// *************************************************************************** *
// *                                                                           *
// * Description:         CANDB File                                           *
// * Generated at:        2023-03-30 16:08                                     *
// * System:              ZSDB123101                                           *
// * Variant:             CS1E                                                 *
// * Network:             Private_CANFD5                                       *
// *                                                                           *
// *************************************************************************** *
VERSION "Private_CANFD5"

NS_ :

BS_ :

BU_ :  ASDM SODL

BO_ 137 SODLPrivateCANFD5Fr72 : 64 SODL
 SG_ ReSideRdrLeDetn229_UB : 487|1@0+ (1,0) [0|1] "" ASDM
 SG_ ReSideRdrLeDetn229RdrDetnAmbigState : 72|1@0+ (1,0) [0|1] "" ASDM
 SG_ ReSideRdrLeDetn229RdrDetnAssoTrkID : 79|7@0+ (1.0,0.0) [0.0|127.0] "Unitless" ASDM
 SG_ ReSideRdrLeDetn229RdrDetnAzi : 34|11@0+ (0.1,-90.0) [-90.0|90.0] "Deg" ASDM
 SG_ ReSideRdrLeDetn229RdrDetnChks : 7|8@0+ (1.0,0.0) [0.0|255.0] "Unitless" ASDM
 SG_ ReSideRdrLeDetn229RdrDetnCntr : 15|4@0+ (1.0,0.0) [0.0|15.0] "Unitless" ASDM
 SG_ ReSideRdrLeDetn229RdrDetnConf : 11|7@0+ (1.0,0.0) [0.0|100.0] "%" ASDM
 SG_ ReSideRdrLeDetn229RdrDetnElevn : 20|5@0+ (1.0,-15.0) [-15.0|15.0] "Deg" ASDM
 SG_ ReSideRdrLeDetn229RdrDetnPwr : 71|6@0+ (1.0,0.0) [0.0|63.0] "dB" ASDM
 SG_ ReSideRdrLeDetn229RdrDetnRng : 55|14@0+ (0.02,-1.0) [-1.0|200.0] "m" ASDM
 SG_ ReSideRdrLeDetn229RdrDetnRngV : 31|13@0+ (0.02,-80.0) [-80.0|80.0] "m/s" ASDM
 SG_ ReSideRdrLeDetn229RdrDetnSameRV : 65|2@0+ (1,0) [0|3] "" ASDM
 SG_ ReSideRdrLeDetn229RdrDetnSts : 57|2@0+ (1,0) [0|3] "" ASDM
 SG_ ReSideRdrLeDetn230_UB : 486|1@0+ (1,0) [0|1] "" ASDM
 SG_ ReSideRdrLeDetn230RdrDetnAmbigState : 152|1@0+ (1,0) [0|1] "" ASDM
 SG_ ReSideRdrLeDetn230RdrDetnAssoTrkID : 159|7@0+ (1.0,0.0) [0.0|127.0] "Unitless" ASDM
 SG_ ReSideRdrLeDetn230RdrDetnAzi : 114|11@0+ (0.1,-90.0) [-90.0|90.0] "Deg" ASDM
 SG_ ReSideRdrLeDetn230RdrDetnChks : 87|8@0+ (1.0,0.0) [0.0|255.0] "Unitless" ASDM
 SG_ ReSideRdrLeDetn230RdrDetnCntr : 95|4@0+ (1.0,0.0) [0.0|15.0] "Unitless" ASDM
 SG_ ReSideRdrLeDetn230RdrDetnConf : 91|7@0+ (1.0,0.0) [0.0|100.0] "%" ASDM
 SG_ ReSideRdrLeDetn230RdrDetnElevn : 100|5@0+ (1.0,-15.0) [-15.0|15.0] "Deg" ASDM
 SG_ ReSideRdrLeDetn230RdrDetnPwr : 151|6@0+ (1.0,0.0) [0.0|63.0] "dB" ASDM
 SG_ ReSideRdrLeDetn230RdrDetnRng : 135|14@0+ (0.02,-1.0) [-1.0|200.0] "m" ASDM
 SG_ ReSideRdrLeDetn230RdrDetnRngV : 111|13@0+ (0.02,-80.0) [-80.0|80.0] "m/s" ASDM
 SG_ ReSideRdrLeDetn230RdrDetnSameRV : 145|2@0+ (1,0) [0|3] "" ASDM
 SG_ ReSideRdrLeDetn230RdrDetnSts : 137|2@0+ (1,0) [0|3] "" ASDM
 SG_ ReSideRdrLeDetn231_UB : 485|1@0+ (1,0) [0|1] "" ASDM
 SG_ ReSideRdrLeDetn231RdrDetnAmbigState : 232|1@0+ (1,0) [0|1] "" ASDM
 SG_ ReSideRdrLeDetn231RdrDetnAssoTrkID : 239|7@0+ (1.0,0.0) [0.0|127.0] "Unitless" ASDM
 SG_ ReSideRdrLeDetn231RdrDetnAzi : 194|11@0+ (0.1,-90.0) [-90.0|90.0] "Deg" ASDM
 SG_ ReSideRdrLeDetn231RdrDetnChks : 167|8@0+ (1.0,0.0) [0.0|255.0] "Unitless" ASDM
 SG_ ReSideRdrLeDetn231RdrDetnCntr : 175|4@0+ (1.0,0.0) [0.0|15.0] "Unitless" ASDM
 SG_ ReSideRdrLeDetn231RdrDetnConf : 171|7@0+ (1.0,0.0) [0.0|100.0] "%" ASDM
 SG_ ReSideRdrLeDetn231RdrDetnElevn : 180|5@0+ (1.0,-15.0) [-15.0|15.0] "Deg" ASDM
 SG_ ReSideRdrLeDetn231RdrDetnPwr : 231|6@0+ (1.0,0.0) [0.0|63.0] "dB" ASDM
 SG_ ReSideRdrLeDetn231RdrDetnRng : 215|14@0+ (0.02,-1.0) [-1.0|200.0] "m" ASDM
 SG_ ReSideRdrLeDetn231RdrDetnRngV : 191|13@0+ (0.02,-80.0) [-80.0|80.0] "m/s" ASDM
 SG_ ReSideRdrLeDetn231RdrDetnSameRV : 225|2@0+ (1,0) [0|3] "" ASDM
 SG_ ReSideRdrLeDetn231RdrDetnSts : 217|2@0+ (1,0) [0|3] "" ASDM
 SG_ ReSideRdrLeDetn232_UB : 484|1@0+ (1,0) [0|1] "" ASDM
 SG_ ReSideRdrLeDetn232RdrDetnAmbigState : 312|1@0+ (1,0) [0|1] "" ASDM
 SG_ ReSideRdrLeDetn232RdrDetnAssoTrkID : 319|7@0+ (1.0,0.0) [0.0|127.0] "Unitless" ASDM
 SG_ ReSideRdrLeDetn232RdrDetnAzi : 274|11@0+ (0.1,-90.0) [-90.0|90.0] "Deg" ASDM
 SG_ ReSideRdrLeDetn232RdrDetnChks : 247|8@0+ (1.0,0.0) [0.0|255.0] "Unitless" ASDM
 SG_ ReSideRdrLeDetn232RdrDetnCntr : 255|4@0+ (1.0,0.0) [0.0|15.0] "Unitless" ASDM
 SG_ ReSideRdrLeDetn232RdrDetnConf : 251|7@0+ (1.0,0.0) [0.0|100.0] "%" ASDM
 SG_ ReSideRdrLeDetn232RdrDetnElevn : 260|5@0+ (1.0,-15.0) [-15.0|15.0] "Deg" ASDM
 SG_ ReSideRdrLeDetn232RdrDetnPwr : 311|6@0+ (1.0,0.0) [0.0|63.0] "dB" ASDM
 SG_ ReSideRdrLeDetn232RdrDetnRng : 295|14@0+ (0.02,-1.0) [-1.0|200.0] "m" ASDM
 SG_ ReSideRdrLeDetn232RdrDetnRngV : 271|13@0+ (0.02,-80.0) [-80.0|80.0] "m/s" ASDM
 SG_ ReSideRdrLeDetn232RdrDetnSameRV : 305|2@0+ (1,0) [0|3] "" ASDM
 SG_ ReSideRdrLeDetn232RdrDetnSts : 297|2@0+ (1,0) [0|3] "" ASDM
 SG_ ReSideRdrLeDetn233_UB : 483|1@0+ (1,0) [0|1] "" ASDM
 SG_ ReSideRdrLeDetn233RdrDetnAmbigState : 392|1@0+ (1,0) [0|1] "" ASDM
 SG_ ReSideRdrLeDetn233RdrDetnAssoTrkID : 399|7@0+ (1.0,0.0) [0.0|127.0] "Unitless" ASDM
 SG_ ReSideRdrLeDetn233RdrDetnAzi : 354|11@0+ (0.1,-90.0) [-90.0|90.0] "Deg" ASDM
 SG_ ReSideRdrLeDetn233RdrDetnChks : 327|8@0+ (1.0,0.0) [0.0|255.0] "Unitless" ASDM
 SG_ ReSideRdrLeDetn233RdrDetnCntr : 335|4@0+ (1.0,0.0) [0.0|15.0] "Unitless" ASDM
 SG_ ReSideRdrLeDetn233RdrDetnConf : 331|7@0+ (1.0,0.0) [0.0|100.0] "%" ASDM
 SG_ ReSideRdrLeDetn233RdrDetnElevn : 340|5@0+ (1.0,-15.0) [-15.0|15.0] "Deg" ASDM
 SG_ ReSideRdrLeDetn233RdrDetnPwr : 391|6@0+ (1.0,0.0) [0.0|63.0] "dB" ASDM
 SG_ ReSideRdrLeDetn233RdrDetnRng : 375|14@0+ (0.02,-1.0) [-1.0|200.0] "m" ASDM
 SG_ ReSideRdrLeDetn233RdrDetnRngV : 351|13@0+ (0.02,-80.0) [-80.0|80.0] "m/s" ASDM
 SG_ ReSideRdrLeDetn233RdrDetnSameRV : 385|2@0+ (1,0) [0|3] "" ASDM
 SG_ ReSideRdrLeDetn233RdrDetnSts : 377|2@0+ (1,0) [0|3] "" ASDM
 SG_ ReSideRdrLeDetn234_UB : 482|1@0+ (1,0) [0|1] "" ASDM
 SG_ ReSideRdrLeDetn234RdrDetnAmbigState : 472|1@0+ (1,0) [0|1] "" ASDM
 SG_ ReSideRdrLeDetn234RdrDetnAssoTrkID : 479|7@0+ (1.0,0.0) [0.0|127.0] "Unitless" ASDM
 SG_ ReSideRdrLeDetn234RdrDetnAzi : 434|11@0+ (0.1,-90.0) [-90.0|90.0] "Deg" ASDM
 SG_ ReSideRdrLeDetn234RdrDetnChks : 407|8@0+ (1.0,0.0) [0.0|255.0] "Unitless" ASDM
 SG_ ReSideRdrLeDetn234RdrDetnCntr : 415|4@0+ (1.0,0.0) [0.0|15.0] "Unitless" ASDM
 SG_ ReSideRdrLeDetn234RdrDetnConf : 411|7@0+ (1.0,0.0) [0.0|100.0] "%" ASDM
 SG_ ReSideRdrLeDetn234RdrDetnElevn : 420|5@0+ (1.0,-15.0) [-15.0|15.0] "Deg" ASDM
 SG_ ReSideRdrLeDetn234RdrDetnPwr : 471|6@0+ (1.0,0.0) [0.0|63.0] "dB" ASDM
 SG_ ReSideRdrLeDetn234RdrDetnRng : 455|14@0+ (0.02,-1.0) [-1.0|200.0] "m" ASDM
 SG_ ReSideRdrLeDetn234RdrDetnRngV : 431|13@0+ (0.02,-80.0) [-80.0|80.0] "m/s" ASDM
 SG_ ReSideRdrLeDetn234RdrDetnSameRV : 465|2@0+ (1,0) [0|3] "" ASDM
 SG_ ReSideRdrLeDetn234RdrDetnSts : 457|2@0+ (1,0) [0|3] "" ASDM

BO_ 144 SODLPrivateCANFD5Fr73 : 64 SODL
 SG_ ReSideRdrLeDetn235_UB : 487|1@0+ (1,0) [0|1] "" ASDM
 SG_ ReSideRdrLeDetn235RdrDetnAmbigState : 72|1@0+ (1,0) [0|1] "" ASDM
 SG_ ReSideRdrLeDetn235RdrDetnAssoTrkID : 79|7@0+ (1.0,0.0) [0.0|127.0] "Unitless" ASDM
 SG_ ReSideRdrLeDetn235RdrDetnAzi : 34|11@0+ (0.1,-90.0) [-90.0|90.0] "Deg" ASDM
 SG_ ReSideRdrLeDetn235RdrDetnChks : 7|8@0+ (1.0,0.0) [0.0|255.0] "Unitless" ASDM
 SG_ ReSideRdrLeDetn235RdrDetnCntr : 15|4@0+ (1.0,0.0) [0.0|15.0] "Unitless" ASDM
 SG_ ReSideRdrLeDetn235RdrDetnConf : 11|7@0+ (1.0,0.0) [0.0|100.0] "%" ASDM
 SG_ ReSideRdrLeDetn235RdrDetnElevn : 20|5@0+ (1.0,-15.0) [-15.0|15.0] "Deg" ASDM
 SG_ ReSideRdrLeDetn235RdrDetnPwr : 71|6@0+ (1.0,0.0) [0.0|63.0] "dB" ASDM
 SG_ ReSideRdrLeDetn235RdrDetnRng : 55|14@0+ (0.02,-1.0) [-1.0|200.0] "m" ASDM
 SG_ ReSideRdrLeDetn235RdrDetnRngV : 31|13@0+ (0.02,-80.0) [-80.0|80.0] "m/s" ASDM
 SG_ ReSideRdrLeDetn235RdrDetnSameRV : 65|2@0+ (1,0) [0|3] "" ASDM
 SG_ ReSideRdrLeDetn235RdrDetnSts : 57|2@0+ (1,0) [0|3] "" ASDM
 SG_ ReSideRdrLeDetn236_UB : 486|1@0+ (1,0) [0|1] "" ASDM
 SG_ ReSideRdrLeDetn236RdrDetnAmbigState : 152|1@0+ (1,0) [0|1] "" ASDM
 SG_ ReSideRdrLeDetn236RdrDetnAssoTrkID : 159|7@0+ (1.0,0.0) [0.0|127.0] "Unitless" ASDM
 SG_ ReSideRdrLeDetn236RdrDetnAzi : 114|11@0+ (0.1,-90.0) [-90.0|90.0] "Deg" ASDM
 SG_ ReSideRdrLeDetn236RdrDetnChks : 87|8@0+ (1.0,0.0) [0.0|255.0] "Unitless" ASDM
 SG_ ReSideRdrLeDetn236RdrDetnCntr : 95|4@0+ (1.0,0.0) [0.0|15.0] "Unitless" ASDM
 SG_ ReSideRdrLeDetn236RdrDetnConf : 91|7@0+ (1.0,0.0) [0.0|100.0] "%" ASDM
 SG_ ReSideRdrLeDetn236RdrDetnElevn : 100|5@0+ (1.0,-15.0) [-15.0|15.0] "Deg" ASDM
 SG_ ReSideRdrLeDetn236RdrDetnPwr : 151|6@0+ (1.0,0.0) [0.0|63.0] "dB" ASDM
 SG_ ReSideRdrLeDetn236RdrDetnRng : 135|14@0+ (0.02,-1.0) [-1.0|200.0] "m" ASDM
 SG_ ReSideRdrLeDetn236RdrDetnRngV : 111|13@0+ (0.02,-80.0) [-80.0|80.0] "m/s" ASDM
 SG_ ReSideRdrLeDetn236RdrDetnSameRV : 145|2@0+ (1,0) [0|3] "" ASDM
 SG_ ReSideRdrLeDetn236RdrDetnSts : 137|2@0+ (1,0) [0|3] "" ASDM
 SG_ ReSideRdrLeDetn237_UB : 485|1@0+ (1,0) [0|1] "" ASDM
 SG_ ReSideRdrLeDetn237RdrDetnAmbigState : 232|1@0+ (1,0) [0|1] "" ASDM
 SG_ ReSideRdrLeDetn237RdrDetnAssoTrkID : 239|7@0+ (1.0,0.0) [0.0|127.0] "Unitless" ASDM
 SG_ ReSideRdrLeDetn237RdrDetnAzi : 194|11@0+ (0.1,-90.0) [-90.0|90.0] "Deg" ASDM
 SG_ ReSideRdrLeDetn237RdrDetnChks : 167|8@0+ (1.0,0.0) [0.0|255.0] "Unitless" ASDM
 SG_ ReSideRdrLeDetn237RdrDetnCntr : 175|4@0+ (1.0,0.0) [0.0|15.0] "Unitless" ASDM
 SG_ ReSideRdrLeDetn237RdrDetnConf : 171|7@0+ (1.0,0.0) [0.0|100.0] "%" ASDM
 SG_ ReSideRdrLeDetn237RdrDetnElevn : 180|5@0+ (1.0,-15.0) [-15.0|15.0] "Deg" ASDM
 SG_ ReSideRdrLeDetn237RdrDetnPwr : 231|6@0+ (1.0,0.0) [0.0|63.0] "dB" ASDM
 SG_ ReSideRdrLeDetn237RdrDetnRng : 215|14@0+ (0.02,-1.0) [-1.0|200.0] "m" ASDM
 SG_ ReSideRdrLeDetn237RdrDetnRngV : 191|13@0+ (0.02,-80.0) [-80.0|80.0] "m/s" ASDM
 SG_ ReSideRdrLeDetn237RdrDetnSameRV : 225|2@0+ (1,0) [0|3] "" ASDM
 SG_ ReSideRdrLeDetn237RdrDetnSts : 217|2@0+ (1,0) [0|3] "" ASDM
 SG_ ReSideRdrLeDetn238_UB : 484|1@0+ (1,0) [0|1] "" ASDM
 SG_ ReSideRdrLeDetn238RdrDetnAmbigState : 312|1@0+ (1,0) [0|1] "" ASDM
 SG_ ReSideRdrLeDetn238RdrDetnAssoTrkID : 319|7@0+ (1.0,0.0) [0.0|127.0] "Unitless" ASDM
 SG_ ReSideRdrLeDetn238RdrDetnAzi : 274|11@0+ (0.1,-90.0) [-90.0|90.0] "Deg" ASDM
 SG_ ReSideRdrLeDetn238RdrDetnChks : 247|8@0+ (1.0,0.0) [0.0|255.0] "Unitless" ASDM
 SG_ ReSideRdrLeDetn238RdrDetnCntr : 255|4@0+ (1.0,0.0) [0.0|15.0] "Unitless" ASDM
 SG_ ReSideRdrLeDetn238RdrDetnConf : 251|7@0+ (1.0,0.0) [0.0|100.0] "%" ASDM
 SG_ ReSideRdrLeDetn238RdrDetnElevn : 260|5@0+ (1.0,-15.0) [-15.0|15.0] "Deg" ASDM
 SG_ ReSideRdrLeDetn238RdrDetnPwr : 311|6@0+ (1.0,0.0) [0.0|63.0] "dB" ASDM
 SG_ ReSideRdrLeDetn238RdrDetnRng : 295|14@0+ (0.02,-1.0) [-1.0|200.0] "m" ASDM
 SG_ ReSideRdrLeDetn238RdrDetnRngV : 271|13@0+ (0.02,-80.0) [-80.0|80.0] "m/s" ASDM
 SG_ ReSideRdrLeDetn238RdrDetnSameRV : 305|2@0+ (1,0) [0|3] "" ASDM
 SG_ ReSideRdrLeDetn238RdrDetnSts : 297|2@0+ (1,0) [0|3] "" ASDM
 SG_ ReSideRdrLeDetn239_UB : 483|1@0+ (1,0) [0|1] "" ASDM
 SG_ ReSideRdrLeDetn239RdrDetnAmbigState : 392|1@0+ (1,0) [0|1] "" ASDM
 SG_ ReSideRdrLeDetn239RdrDetnAssoTrkID : 399|7@0+ (1.0,0.0) [0.0|127.0] "Unitless" ASDM
 SG_ ReSideRdrLeDetn239RdrDetnAzi : 354|11@0+ (0.1,-90.0) [-90.0|90.0] "Deg" ASDM
 SG_ ReSideRdrLeDetn239RdrDetnChks : 327|8@0+ (1.0,0.0) [0.0|255.0] "Unitless" ASDM
 SG_ ReSideRdrLeDetn239RdrDetnCntr : 335|4@0+ (1.0,0.0) [0.0|15.0] "Unitless" ASDM
 SG_ ReSideRdrLeDetn239RdrDetnConf : 331|7@0+ (1.0,0.0) [0.0|100.0] "%" ASDM
 SG_ ReSideRdrLeDetn239RdrDetnElevn : 340|5@0+ (1.0,-15.0) [-15.0|15.0] "Deg" ASDM
 SG_ ReSideRdrLeDetn239RdrDetnPwr : 391|6@0+ (1.0,0.0) [0.0|63.0] "dB" ASDM
 SG_ ReSideRdrLeDetn239RdrDetnRng : 375|14@0+ (0.02,-1.0) [-1.0|200.0] "m" ASDM
 SG_ ReSideRdrLeDetn239RdrDetnRngV : 351|13@0+ (0.02,-80.0) [-80.0|80.0] "m/s" ASDM
 SG_ ReSideRdrLeDetn239RdrDetnSameRV : 385|2@0+ (1,0) [0|3] "" ASDM
 SG_ ReSideRdrLeDetn239RdrDetnSts : 377|2@0+ (1,0) [0|3] "" ASDM
 SG_ ReSideRdrLeDetn240_UB : 482|1@0+ (1,0) [0|1] "" ASDM
 SG_ ReSideRdrLeDetn240RdrDetnAmbigState : 472|1@0+ (1,0) [0|1] "" ASDM
 SG_ ReSideRdrLeDetn240RdrDetnAssoTrkID : 479|7@0+ (1.0,0.0) [0.0|127.0] "Unitless" ASDM
 SG_ ReSideRdrLeDetn240RdrDetnAzi : 434|11@0+ (0.1,-90.0) [-90.0|90.0] "Deg" ASDM
 SG_ ReSideRdrLeDetn240RdrDetnChks : 407|8@0+ (1.0,0.0) [0.0|255.0] "Unitless" ASDM
 SG_ ReSideRdrLeDetn240RdrDetnCntr : 415|4@0+ (1.0,0.0) [0.0|15.0] "Unitless" ASDM
 SG_ ReSideRdrLeDetn240RdrDetnConf : 411|7@0+ (1.0,0.0) [0.0|100.0] "%" ASDM
 SG_ ReSideRdrLeDetn240RdrDetnElevn : 420|5@0+ (1.0,-15.0) [-15.0|15.0] "Deg" ASDM
 SG_ ReSideRdrLeDetn240RdrDetnPwr : 471|6@0+ (1.0,0.0) [0.0|63.0] "dB" ASDM
 SG_ ReSideRdrLeDetn240RdrDetnRng : 455|14@0+ (0.02,-1.0) [-1.0|200.0] "m" ASDM
 SG_ ReSideRdrLeDetn240RdrDetnRngV : 431|13@0+ (0.02,-80.0) [-80.0|80.0] "m/s" ASDM
 SG_ ReSideRdrLeDetn240RdrDetnSameRV : 465|2@0+ (1,0) [0|3] "" ASDM
 SG_ ReSideRdrLeDetn240RdrDetnSts : 457|2@0+ (1,0) [0|3] "" ASDM

BO_ 145 SODLPrivateCANFD5Fr74 : 64 SODL
 SG_ ReSideRdrLeDetn241_UB : 487|1@0+ (1,0) [0|1] "" ASDM
 SG_ ReSideRdrLeDetn241RdrDetnAmbigState : 72|1@0+ (1,0) [0|1] "" ASDM
 SG_ ReSideRdrLeDetn241RdrDetnAssoTrkID : 79|7@0+ (1.0,0.0) [0.0|127.0] "Unitless" ASDM
 SG_ ReSideRdrLeDetn241RdrDetnAzi : 34|11@0+ (0.1,-90.0) [-90.0|90.0] "Deg" ASDM
 SG_ ReSideRdrLeDetn241RdrDetnChks : 7|8@0+ (1.0,0.0) [0.0|255.0] "Unitless" ASDM
 SG_ ReSideRdrLeDetn241RdrDetnCntr : 15|4@0+ (1.0,0.0) [0.0|15.0] "Unitless" ASDM
 SG_ ReSideRdrLeDetn241RdrDetnConf : 11|7@0+ (1.0,0.0) [0.0|100.0] "%" ASDM
 SG_ ReSideRdrLeDetn241RdrDetnElevn : 20|5@0+ (1.0,-15.0) [-15.0|15.0] "Deg" ASDM
 SG_ ReSideRdrLeDetn241RdrDetnPwr : 71|6@0+ (1.0,0.0) [0.0|63.0] "dB" ASDM
 SG_ ReSideRdrLeDetn241RdrDetnRng : 55|14@0+ (0.02,-1.0) [-1.0|200.0] "m" ASDM
 SG_ ReSideRdrLeDetn241RdrDetnRngV : 31|13@0+ (0.02,-80.0) [-80.0|80.0] "m/s" ASDM
 SG_ ReSideRdrLeDetn241RdrDetnSameRV : 65|2@0+ (1,0) [0|3] "" ASDM
 SG_ ReSideRdrLeDetn241RdrDetnSts : 57|2@0+ (1,0) [0|3] "" ASDM
 SG_ ReSideRdrLeDetn242_UB : 486|1@0+ (1,0) [0|1] "" ASDM
 SG_ ReSideRdrLeDetn242RdrDetnAmbigState : 152|1@0+ (1,0) [0|1] "" ASDM
 SG_ ReSideRdrLeDetn242RdrDetnAssoTrkID : 159|7@0+ (1.0,0.0) [0.0|127.0] "Unitless" ASDM
 SG_ ReSideRdrLeDetn242RdrDetnAzi : 114|11@0+ (0.1,-90.0) [-90.0|90.0] "Deg" ASDM
 SG_ ReSideRdrLeDetn242RdrDetnChks : 87|8@0+ (1.0,0.0) [0.0|255.0] "Unitless" ASDM
 SG_ ReSideRdrLeDetn242RdrDetnCntr : 95|4@0+ (1.0,0.0) [0.0|15.0] "Unitless" ASDM
 SG_ ReSideRdrLeDetn242RdrDetnConf : 91|7@0+ (1.0,0.0) [0.0|100.0] "%" ASDM
 SG_ ReSideRdrLeDetn242RdrDetnElevn : 100|5@0+ (1.0,-15.0) [-15.0|15.0] "Deg" ASDM
 SG_ ReSideRdrLeDetn242RdrDetnPwr : 151|6@0+ (1.0,0.0) [0.0|63.0] "dB" ASDM
 SG_ ReSideRdrLeDetn242RdrDetnRng : 135|14@0+ (0.02,-1.0) [-1.0|200.0] "m" ASDM
 SG_ ReSideRdrLeDetn242RdrDetnRngV : 111|13@0+ (0.02,-80.0) [-80.0|80.0] "m/s" ASDM
 SG_ ReSideRdrLeDetn242RdrDetnSameRV : 145|2@0+ (1,0) [0|3] "" ASDM
 SG_ ReSideRdrLeDetn242RdrDetnSts : 137|2@0+ (1,0) [0|3] "" ASDM
 SG_ ReSideRdrLeDetn243_UB : 485|1@0+ (1,0) [0|1] "" ASDM
 SG_ ReSideRdrLeDetn243RdrDetnAmbigState : 232|1@0+ (1,0) [0|1] "" ASDM
 SG_ ReSideRdrLeDetn243RdrDetnAssoTrkID : 239|7@0+ (1.0,0.0) [0.0|127.0] "Unitless" ASDM
 SG_ ReSideRdrLeDetn243RdrDetnAzi : 194|11@0+ (0.1,-90.0) [-90.0|90.0] "Deg" ASDM
 SG_ ReSideRdrLeDetn243RdrDetnChks : 167|8@0+ (1.0,0.0) [0.0|255.0] "Unitless" ASDM
 SG_ ReSideRdrLeDetn243RdrDetnCntr : 175|4@0+ (1.0,0.0) [0.0|15.0] "Unitless" ASDM
 SG_ ReSideRdrLeDetn243RdrDetnConf : 171|7@0+ (1.0,0.0) [0.0|100.0] "%" ASDM
 SG_ ReSideRdrLeDetn243RdrDetnElevn : 180|5@0+ (1.0,-15.0) [-15.0|15.0] "Deg" ASDM
 SG_ ReSideRdrLeDetn243RdrDetnPwr : 231|6@0+ (1.0,0.0) [0.0|63.0] "dB" ASDM
 SG_ ReSideRdrLeDetn243RdrDetnRng : 215|14@0+ (0.02,-1.0) [-1.0|200.0] "m" ASDM
 SG_ ReSideRdrLeDetn243RdrDetnRngV : 191|13@0+ (0.02,-80.0) [-80.0|80.0] "m/s" ASDM
 SG_ ReSideRdrLeDetn243RdrDetnSameRV : 225|2@0+ (1,0) [0|3] "" ASDM
 SG_ ReSideRdrLeDetn243RdrDetnSts : 217|2@0+ (1,0) [0|3] "" ASDM
 SG_ ReSideRdrLeDetn244_UB : 484|1@0+ (1,0) [0|1] "" ASDM
 SG_ ReSideRdrLeDetn244RdrDetnAmbigState : 312|1@0+ (1,0) [0|1] "" ASDM
 SG_ ReSideRdrLeDetn244RdrDetnAssoTrkID : 319|7@0+ (1.0,0.0) [0.0|127.0] "Unitless" ASDM
 SG_ ReSideRdrLeDetn244RdrDetnAzi : 274|11@0+ (0.1,-90.0) [-90.0|90.0] "Deg" ASDM
 SG_ ReSideRdrLeDetn244RdrDetnChks : 247|8@0+ (1.0,0.0) [0.0|255.0] "Unitless" ASDM
 SG_ ReSideRdrLeDetn244RdrDetnCntr : 255|4@0+ (1.0,0.0) [0.0|15.0] "Unitless" ASDM
 SG_ ReSideRdrLeDetn244RdrDetnConf : 251|7@0+ (1.0,0.0) [0.0|100.0] "%" ASDM
 SG_ ReSideRdrLeDetn244RdrDetnElevn : 260|5@0+ (1.0,-15.0) [-15.0|15.0] "Deg" ASDM
 SG_ ReSideRdrLeDetn244RdrDetnPwr : 311|6@0+ (1.0,0.0) [0.0|63.0] "dB" ASDM
 SG_ ReSideRdrLeDetn244RdrDetnRng : 295|14@0+ (0.02,-1.0) [-1.0|200.0] "m" ASDM
 SG_ ReSideRdrLeDetn244RdrDetnRngV : 271|13@0+ (0.02,-80.0) [-80.0|80.0] "m/s" ASDM
 SG_ ReSideRdrLeDetn244RdrDetnSameRV : 305|2@0+ (1,0) [0|3] "" ASDM
 SG_ ReSideRdrLeDetn244RdrDetnSts : 297|2@0+ (1,0) [0|3] "" ASDM
 SG_ ReSideRdrLeDetn245_UB : 483|1@0+ (1,0) [0|1] "" ASDM
 SG_ ReSideRdrLeDetn245RdrDetnAmbigState : 392|1@0+ (1,0) [0|1] "" ASDM
 SG_ ReSideRdrLeDetn245RdrDetnAssoTrkID : 399|7@0+ (1.0,0.0) [0.0|127.0] "Unitless" ASDM
 SG_ ReSideRdrLeDetn245RdrDetnAzi : 354|11@0+ (0.1,-90.0) [-90.0|90.0] "Deg" ASDM
 SG_ ReSideRdrLeDetn245RdrDetnChks : 327|8@0+ (1.0,0.0) [0.0|255.0] "Unitless" ASDM
 SG_ ReSideRdrLeDetn245RdrDetnCntr : 335|4@0+ (1.0,0.0) [0.0|15.0] "Unitless" ASDM
 SG_ ReSideRdrLeDetn245RdrDetnConf : 331|7@0+ (1.0,0.0) [0.0|100.0] "%" ASDM
 SG_ ReSideRdrLeDetn245RdrDetnElevn : 340|5@0+ (1.0,-15.0) [-15.0|15.0] "Deg" ASDM
 SG_ ReSideRdrLeDetn245RdrDetnPwr : 391|6@0+ (1.0,0.0) [0.0|63.0] "dB" ASDM
 SG_ ReSideRdrLeDetn245RdrDetnRng : 375|14@0+ (0.02,-1.0) [-1.0|200.0] "m" ASDM
 SG_ ReSideRdrLeDetn245RdrDetnRngV : 351|13@0+ (0.02,-80.0) [-80.0|80.0] "m/s" ASDM
 SG_ ReSideRdrLeDetn245RdrDetnSameRV : 385|2@0+ (1,0) [0|3] "" ASDM
 SG_ ReSideRdrLeDetn245RdrDetnSts : 377|2@0+ (1,0) [0|3] "" ASDM
 SG_ ReSideRdrLeDetn246_UB : 482|1@0+ (1,0) [0|1] "" ASDM
 SG_ ReSideRdrLeDetn246RdrDetnAmbigState : 472|1@0+ (1,0) [0|1] "" ASDM
 SG_ ReSideRdrLeDetn246RdrDetnAssoTrkID : 479|7@0+ (1.0,0.0) [0.0|127.0] "Unitless" ASDM
 SG_ ReSideRdrLeDetn246RdrDetnAzi : 434|11@0+ (0.1,-90.0) [-90.0|90.0] "Deg" ASDM
 SG_ ReSideRdrLeDetn246RdrDetnChks : 407|8@0+ (1.0,0.0) [0.0|255.0] "Unitless" ASDM
 SG_ ReSideRdrLeDetn246RdrDetnCntr : 415|4@0+ (1.0,0.0) [0.0|15.0] "Unitless" ASDM
 SG_ ReSideRdrLeDetn246RdrDetnConf : 411|7@0+ (1.0,0.0) [0.0|100.0] "%" ASDM
 SG_ ReSideRdrLeDetn246RdrDetnElevn : 420|5@0+ (1.0,-15.0) [-15.0|15.0] "Deg" ASDM
 SG_ ReSideRdrLeDetn246RdrDetnPwr : 471|6@0+ (1.0,0.0) [0.0|63.0] "dB" ASDM
 SG_ ReSideRdrLeDetn246RdrDetnRng : 455|14@0+ (0.02,-1.0) [-1.0|200.0] "m" ASDM
 SG_ ReSideRdrLeDetn246RdrDetnRngV : 431|13@0+ (0.02,-80.0) [-80.0|80.0] "m/s" ASDM
 SG_ ReSideRdrLeDetn246RdrDetnSameRV : 465|2@0+ (1,0) [0|3] "" ASDM
 SG_ ReSideRdrLeDetn246RdrDetnSts : 457|2@0+ (1,0) [0|3] "" ASDM

BO_ 146 SODLPrivateCANFD5Fr75 : 64 SODL
 SG_ ReSideRdrLeDetn247_UB : 487|1@0+ (1,0) [0|1] "" ASDM
 SG_ ReSideRdrLeDetn247RdrDetnAmbigState : 72|1@0+ (1,0) [0|1] "" ASDM
 SG_ ReSideRdrLeDetn247RdrDetnAssoTrkID : 79|7@0+ (1.0,0.0) [0.0|127.0] "Unitless" ASDM
 SG_ ReSideRdrLeDetn247RdrDetnAzi : 34|11@0+ (0.1,-90.0) [-90.0|90.0] "Deg" ASDM
 SG_ ReSideRdrLeDetn247RdrDetnChks : 7|8@0+ (1.0,0.0) [0.0|255.0] "Unitless" ASDM
 SG_ ReSideRdrLeDetn247RdrDetnCntr : 15|4@0+ (1.0,0.0) [0.0|15.0] "Unitless" ASDM
 SG_ ReSideRdrLeDetn247RdrDetnConf : 11|7@0+ (1.0,0.0) [0.0|100.0] "%" ASDM
 SG_ ReSideRdrLeDetn247RdrDetnElevn : 20|5@0+ (1.0,-15.0) [-15.0|15.0] "Deg" ASDM
 SG_ ReSideRdrLeDetn247RdrDetnPwr : 71|6@0+ (1.0,0.0) [0.0|63.0] "dB" ASDM
 SG_ ReSideRdrLeDetn247RdrDetnRng : 55|14@0+ (0.02,-1.0) [-1.0|200.0] "m" ASDM
 SG_ ReSideRdrLeDetn247RdrDetnRngV : 31|13@0+ (0.02,-80.0) [-80.0|80.0] "m/s" ASDM
 SG_ ReSideRdrLeDetn247RdrDetnSameRV : 65|2@0+ (1,0) [0|3] "" ASDM
 SG_ ReSideRdrLeDetn247RdrDetnSts : 57|2@0+ (1,0) [0|3] "" ASDM
 SG_ ReSideRdrLeDetn248_UB : 486|1@0+ (1,0) [0|1] "" ASDM
 SG_ ReSideRdrLeDetn248RdrDetnAmbigState : 152|1@0+ (1,0) [0|1] "" ASDM
 SG_ ReSideRdrLeDetn248RdrDetnAssoTrkID : 159|7@0+ (1.0,0.0) [0.0|127.0] "Unitless" ASDM
 SG_ ReSideRdrLeDetn248RdrDetnAzi : 114|11@0+ (0.1,-90.0) [-90.0|90.0] "Deg" ASDM
 SG_ ReSideRdrLeDetn248RdrDetnChks : 87|8@0+ (1.0,0.0) [0.0|255.0] "Unitless" ASDM
 SG_ ReSideRdrLeDetn248RdrDetnCntr : 95|4@0+ (1.0,0.0) [0.0|15.0] "Unitless" ASDM
 SG_ ReSideRdrLeDetn248RdrDetnConf : 91|7@0+ (1.0,0.0) [0.0|100.0] "%" ASDM
 SG_ ReSideRdrLeDetn248RdrDetnElevn : 100|5@0+ (1.0,-15.0) [-15.0|15.0] "Deg" ASDM
 SG_ ReSideRdrLeDetn248RdrDetnPwr : 151|6@0+ (1.0,0.0) [0.0|63.0] "dB" ASDM
 SG_ ReSideRdrLeDetn248RdrDetnRng : 135|14@0+ (0.02,-1.0) [-1.0|200.0] "m" ASDM
 SG_ ReSideRdrLeDetn248RdrDetnRngV : 111|13@0+ (0.02,-80.0) [-80.0|80.0] "m/s" ASDM
 SG_ ReSideRdrLeDetn248RdrDetnSameRV : 145|2@0+ (1,0) [0|3] "" ASDM
 SG_ ReSideRdrLeDetn248RdrDetnSts : 137|2@0+ (1,0) [0|3] "" ASDM
 SG_ ReSideRdrLeDetn249_UB : 485|1@0+ (1,0) [0|1] "" ASDM
 SG_ ReSideRdrLeDetn249RdrDetnAmbigState : 232|1@0+ (1,0) [0|1] "" ASDM
 SG_ ReSideRdrLeDetn249RdrDetnAssoTrkID : 239|7@0+ (1.0,0.0) [0.0|127.0] "Unitless" ASDM
 SG_ ReSideRdrLeDetn249RdrDetnAzi : 194|11@0+ (0.1,-90.0) [-90.0|90.0] "Deg" ASDM
 SG_ ReSideRdrLeDetn249RdrDetnChks : 167|8@0+ (1.0,0.0) [0.0|255.0] "Unitless" ASDM
 SG_ ReSideRdrLeDetn249RdrDetnCntr : 175|4@0+ (1.0,0.0) [0.0|15.0] "Unitless" ASDM
 SG_ ReSideRdrLeDetn249RdrDetnConf : 171|7@0+ (1.0,0.0) [0.0|100.0] "%" ASDM
 SG_ ReSideRdrLeDetn249RdrDetnElevn : 180|5@0+ (1.0,-15.0) [-15.0|15.0] "Deg" ASDM
 SG_ ReSideRdrLeDetn249RdrDetnPwr : 231|6@0+ (1.0,0.0) [0.0|63.0] "dB" ASDM
 SG_ ReSideRdrLeDetn249RdrDetnRng : 215|14@0+ (0.02,-1.0) [-1.0|200.0] "m" ASDM
 SG_ ReSideRdrLeDetn249RdrDetnRngV : 191|13@0+ (0.02,-80.0) [-80.0|80.0] "m/s" ASDM
 SG_ ReSideRdrLeDetn249RdrDetnSameRV : 225|2@0+ (1,0) [0|3] "" ASDM
 SG_ ReSideRdrLeDetn249RdrDetnSts : 217|2@0+ (1,0) [0|3] "" ASDM
 SG_ ReSideRdrLeDetn250_UB : 484|1@0+ (1,0) [0|1] "" ASDM
 SG_ ReSideRdrLeDetn250RdrDetnAmbigState : 312|1@0+ (1,0) [0|1] "" ASDM
 SG_ ReSideRdrLeDetn250RdrDetnAssoTrkID : 319|7@0+ (1.0,0.0) [0.0|127.0] "Unitless" ASDM
 SG_ ReSideRdrLeDetn250RdrDetnAzi : 274|11@0+ (0.1,-90.0) [-90.0|90.0] "Deg" ASDM
 SG_ ReSideRdrLeDetn250RdrDetnChks : 247|8@0+ (1.0,0.0) [0.0|255.0] "Unitless" ASDM
 SG_ ReSideRdrLeDetn250RdrDetnCntr : 255|4@0+ (1.0,0.0) [0.0|15.0] "Unitless" ASDM
 SG_ ReSideRdrLeDetn250RdrDetnConf : 251|7@0+ (1.0,0.0) [0.0|100.0] "%" ASDM
 SG_ ReSideRdrLeDetn250RdrDetnElevn : 260|5@0+ (1.0,-15.0) [-15.0|15.0] "Deg" ASDM
 SG_ ReSideRdrLeDetn250RdrDetnPwr : 311|6@0+ (1.0,0.0) [0.0|63.0] "dB" ASDM
 SG_ ReSideRdrLeDetn250RdrDetnRng : 295|14@0+ (0.02,-1.0) [-1.0|200.0] "m" ASDM
 SG_ ReSideRdrLeDetn250RdrDetnRngV : 271|13@0+ (0.02,-80.0) [-80.0|80.0] "m/s" ASDM
 SG_ ReSideRdrLeDetn250RdrDetnSameRV : 305|2@0+ (1,0) [0|3] "" ASDM
 SG_ ReSideRdrLeDetn250RdrDetnSts : 297|2@0+ (1,0) [0|3] "" ASDM
 SG_ ReSideRdrLeDetn251_UB : 483|1@0+ (1,0) [0|1] "" ASDM
 SG_ ReSideRdrLeDetn251RdrDetnAmbigState : 392|1@0+ (1,0) [0|1] "" ASDM
 SG_ ReSideRdrLeDetn251RdrDetnAssoTrkID : 399|7@0+ (1.0,0.0) [0.0|127.0] "Unitless" ASDM
 SG_ ReSideRdrLeDetn251RdrDetnAzi : 354|11@0+ (0.1,-90.0) [-90.0|90.0] "Deg" ASDM
 SG_ ReSideRdrLeDetn251RdrDetnChks : 327|8@0+ (1.0,0.0) [0.0|255.0] "Unitless" ASDM
 SG_ ReSideRdrLeDetn251RdrDetnCntr : 335|4@0+ (1.0,0.0) [0.0|15.0] "Unitless" ASDM
 SG_ ReSideRdrLeDetn251RdrDetnConf : 331|7@0+ (1.0,0.0) [0.0|100.0] "%" ASDM
 SG_ ReSideRdrLeDetn251RdrDetnElevn : 340|5@0+ (1.0,-15.0) [-15.0|15.0] "Deg" ASDM
 SG_ ReSideRdrLeDetn251RdrDetnPwr : 391|6@0+ (1.0,0.0) [0.0|63.0] "dB" ASDM
 SG_ ReSideRdrLeDetn251RdrDetnRng : 375|14@0+ (0.02,-1.0) [-1.0|200.0] "m" ASDM
 SG_ ReSideRdrLeDetn251RdrDetnRngV : 351|13@0+ (0.02,-80.0) [-80.0|80.0] "m/s" ASDM
 SG_ ReSideRdrLeDetn251RdrDetnSameRV : 385|2@0+ (1,0) [0|3] "" ASDM
 SG_ ReSideRdrLeDetn251RdrDetnSts : 377|2@0+ (1,0) [0|3] "" ASDM
 SG_ ReSideRdrLeDetn252_UB : 482|1@0+ (1,0) [0|1] "" ASDM
 SG_ ReSideRdrLeDetn252RdrDetnAmbigState : 472|1@0+ (1,0) [0|1] "" ASDM
 SG_ ReSideRdrLeDetn252RdrDetnAssoTrkID : 479|7@0+ (1.0,0.0) [0.0|127.0] "Unitless" ASDM
 SG_ ReSideRdrLeDetn252RdrDetnAzi : 434|11@0+ (0.1,-90.0) [-90.0|90.0] "Deg" ASDM
 SG_ ReSideRdrLeDetn252RdrDetnChks : 407|8@0+ (1.0,0.0) [0.0|255.0] "Unitless" ASDM
 SG_ ReSideRdrLeDetn252RdrDetnCntr : 415|4@0+ (1.0,0.0) [0.0|15.0] "Unitless" ASDM
 SG_ ReSideRdrLeDetn252RdrDetnConf : 411|7@0+ (1.0,0.0) [0.0|100.0] "%" ASDM
 SG_ ReSideRdrLeDetn252RdrDetnElevn : 420|5@0+ (1.0,-15.0) [-15.0|15.0] "Deg" ASDM
 SG_ ReSideRdrLeDetn252RdrDetnPwr : 471|6@0+ (1.0,0.0) [0.0|63.0] "dB" ASDM
 SG_ ReSideRdrLeDetn252RdrDetnRng : 455|14@0+ (0.02,-1.0) [-1.0|200.0] "m" ASDM
 SG_ ReSideRdrLeDetn252RdrDetnRngV : 431|13@0+ (0.02,-80.0) [-80.0|80.0] "m/s" ASDM
 SG_ ReSideRdrLeDetn252RdrDetnSameRV : 465|2@0+ (1,0) [0|3] "" ASDM
 SG_ ReSideRdrLeDetn252RdrDetnSts : 457|2@0+ (1,0) [0|3] "" ASDM

BO_ 147 SODLPrivateCANFD5Fr76 : 64 SODL
 SG_ ReSideRdrLeDetn253_UB : 327|1@0+ (1,0) [0|1] "" ASDM
 SG_ ReSideRdrLeDetn253RdrDetnAmbigState : 72|1@0+ (1,0) [0|1] "" ASDM
 SG_ ReSideRdrLeDetn253RdrDetnAssoTrkID : 79|7@0+ (1.0,0.0) [0.0|127.0] "Unitless" ASDM
 SG_ ReSideRdrLeDetn253RdrDetnAzi : 34|11@0+ (0.1,-90.0) [-90.0|90.0] "Deg" ASDM
 SG_ ReSideRdrLeDetn253RdrDetnChks : 7|8@0+ (1.0,0.0) [0.0|255.0] "Unitless" ASDM
 SG_ ReSideRdrLeDetn253RdrDetnCntr : 15|4@0+ (1.0,0.0) [0.0|15.0] "Unitless" ASDM
 SG_ ReSideRdrLeDetn253RdrDetnConf : 11|7@0+ (1.0,0.0) [0.0|100.0] "%" ASDM
 SG_ ReSideRdrLeDetn253RdrDetnElevn : 20|5@0+ (1.0,-15.0) [-15.0|15.0] "Deg" ASDM
 SG_ ReSideRdrLeDetn253RdrDetnPwr : 71|6@0+ (1.0,0.0) [0.0|63.0] "dB" ASDM
 SG_ ReSideRdrLeDetn253RdrDetnRng : 55|14@0+ (0.02,-1.0) [-1.0|200.0] "m" ASDM
 SG_ ReSideRdrLeDetn253RdrDetnRngV : 31|13@0+ (0.02,-80.0) [-80.0|80.0] "m/s" ASDM
 SG_ ReSideRdrLeDetn253RdrDetnSameRV : 65|2@0+ (1,0) [0|3] "" ASDM
 SG_ ReSideRdrLeDetn253RdrDetnSts : 57|2@0+ (1,0) [0|3] "" ASDM
 SG_ ReSideRdrLeDetn254_UB : 326|1@0+ (1,0) [0|1] "" ASDM
 SG_ ReSideRdrLeDetn254RdrDetnAmbigState : 152|1@0+ (1,0) [0|1] "" ASDM
 SG_ ReSideRdrLeDetn254RdrDetnAssoTrkID : 159|7@0+ (1.0,0.0) [0.0|127.0] "Unitless" ASDM
 SG_ ReSideRdrLeDetn254RdrDetnAzi : 114|11@0+ (0.1,-90.0) [-90.0|90.0] "Deg" ASDM
 SG_ ReSideRdrLeDetn254RdrDetnChks : 87|8@0+ (1.0,0.0) [0.0|255.0] "Unitless" ASDM
 SG_ ReSideRdrLeDetn254RdrDetnCntr : 95|4@0+ (1.0,0.0) [0.0|15.0] "Unitless" ASDM
 SG_ ReSideRdrLeDetn254RdrDetnConf : 91|7@0+ (1.0,0.0) [0.0|100.0] "%" ASDM
 SG_ ReSideRdrLeDetn254RdrDetnElevn : 100|5@0+ (1.0,-15.0) [-15.0|15.0] "Deg" ASDM
 SG_ ReSideRdrLeDetn254RdrDetnPwr : 151|6@0+ (1.0,0.0) [0.0|63.0] "dB" ASDM
 SG_ ReSideRdrLeDetn254RdrDetnRng : 135|14@0+ (0.02,-1.0) [-1.0|200.0] "m" ASDM
 SG_ ReSideRdrLeDetn254RdrDetnRngV : 111|13@0+ (0.02,-80.0) [-80.0|80.0] "m/s" ASDM
 SG_ ReSideRdrLeDetn254RdrDetnSameRV : 145|2@0+ (1,0) [0|3] "" ASDM
 SG_ ReSideRdrLeDetn254RdrDetnSts : 137|2@0+ (1,0) [0|3] "" ASDM
 SG_ ReSideRdrLeDetn255_UB : 325|1@0+ (1,0) [0|1] "" ASDM
 SG_ ReSideRdrLeDetn255RdrDetnAmbigState : 232|1@0+ (1,0) [0|1] "" ASDM
 SG_ ReSideRdrLeDetn255RdrDetnAssoTrkID : 239|7@0+ (1.0,0.0) [0.0|127.0] "Unitless" ASDM
 SG_ ReSideRdrLeDetn255RdrDetnAzi : 194|11@0+ (0.1,-90.0) [-90.0|90.0] "Deg" ASDM
 SG_ ReSideRdrLeDetn255RdrDetnChks : 167|8@0+ (1.0,0.0) [0.0|255.0] "Unitless" ASDM
 SG_ ReSideRdrLeDetn255RdrDetnCntr : 175|4@0+ (1.0,0.0) [0.0|15.0] "Unitless" ASDM
 SG_ ReSideRdrLeDetn255RdrDetnConf : 171|7@0+ (1.0,0.0) [0.0|100.0] "%" ASDM
 SG_ ReSideRdrLeDetn255RdrDetnElevn : 180|5@0+ (1.0,-15.0) [-15.0|15.0] "Deg" ASDM
 SG_ ReSideRdrLeDetn255RdrDetnPwr : 231|6@0+ (1.0,0.0) [0.0|63.0] "dB" ASDM
 SG_ ReSideRdrLeDetn255RdrDetnRng : 215|14@0+ (0.02,-1.0) [-1.0|200.0] "m" ASDM
 SG_ ReSideRdrLeDetn255RdrDetnRngV : 191|13@0+ (0.02,-80.0) [-80.0|80.0] "m/s" ASDM
 SG_ ReSideRdrLeDetn255RdrDetnSameRV : 225|2@0+ (1,0) [0|3] "" ASDM
 SG_ ReSideRdrLeDetn255RdrDetnSts : 217|2@0+ (1,0) [0|3] "" ASDM
 SG_ ReSideRdrLeDetn256_UB : 324|1@0+ (1,0) [0|1] "" ASDM
 SG_ ReSideRdrLeDetn256RdrDetnAmbigState : 312|1@0+ (1,0) [0|1] "" ASDM
 SG_ ReSideRdrLeDetn256RdrDetnAssoTrkID : 319|7@0+ (1.0,0.0) [0.0|127.0] "Unitless" ASDM
 SG_ ReSideRdrLeDetn256RdrDetnAzi : 274|11@0+ (0.1,-90.0) [-90.0|90.0] "Deg" ASDM
 SG_ ReSideRdrLeDetn256RdrDetnChks : 247|8@0+ (1.0,0.0) [0.0|255.0] "Unitless" ASDM
 SG_ ReSideRdrLeDetn256RdrDetnCntr : 255|4@0+ (1.0,0.0) [0.0|15.0] "Unitless" ASDM
 SG_ ReSideRdrLeDetn256RdrDetnConf : 251|7@0+ (1.0,0.0) [0.0|100.0] "%" ASDM
 SG_ ReSideRdrLeDetn256RdrDetnElevn : 260|5@0+ (1.0,-15.0) [-15.0|15.0] "Deg" ASDM
 SG_ ReSideRdrLeDetn256RdrDetnPwr : 311|6@0+ (1.0,0.0) [0.0|63.0] "dB" ASDM
 SG_ ReSideRdrLeDetn256RdrDetnRng : 295|14@0+ (0.02,-1.0) [-1.0|200.0] "m" ASDM
 SG_ ReSideRdrLeDetn256RdrDetnRngV : 271|13@0+ (0.02,-80.0) [-80.0|80.0] "m/s" ASDM
 SG_ ReSideRdrLeDetn256RdrDetnSameRV : 305|2@0+ (1,0) [0|3] "" ASDM
 SG_ ReSideRdrLeDetn256RdrDetnSts : 297|2@0+ (1,0) [0|3] "" ASDM

BO_ 148 SODLPrivateCANFD5Fr77 : 64 SODL
 SG_ ReSideRdrLeDetTiSync_UB : 119|1@0+ (1,0) [0|1] "" ASDM
 SG_ ReSideRdrLeDetTiSyncRdrStsDetChks : 7|8@0+ (1.0,0.0) [0.0|255.0] "Unitless" ASDM
 SG_ ReSideRdrLeDetTiSyncRdrStsDetCntr : 15|4@0+ (1.0,0.0) [0.0|15.0] "Unitless" ASDM
 SG_ ReSideRdrLeDetTiSyncRdrStsDetLatency : 23|16@0+ (1.0,0.0) [0.0|65535.0] "Unitless" ASDM
 SG_ ReSideRdrLeDetTiSyncRdrStsDetTiStamp20 : 39|32@0+ (1.0,0.0) [0.0|4294967295.0] "s" ASDM
 SG_ ReSideRdrLeDetTiSyncRdrStsDetTiStampHi20 : 71|16@0+ (1.0,0.0) [0.0|65535.0] "s" ASDM
 SG_ ReSideRdrLeDetTiSyncRdrStsDetTiStampNano20 : 87|32@0+ (1.0,0.0) [0.0|4294967295.0] "ns" ASDM
 SG_ ReSideRdrLeDetTiSyncRdrStsDetTistampStsGlbTiBas : 11|1@0+ (1,0) [0|1] "" ASDM
 SG_ ReSideRdrLeDetTiSyncRdrStsDetTistampStsSyncToGateway : 10|1@0+ (1,0) [0|1] "" ASDM
 SG_ ReSideRdrLeDetTiSyncRdrStsDetTistampStsTiLeap : 9|1@0+ (1,0) [0|1] "" ASDM
 SG_ ReSideRdrLeDetTiSyncRdrStsDetTistampStsTiOut : 8|1@0+ (1,0) [0|1] "" ASDM

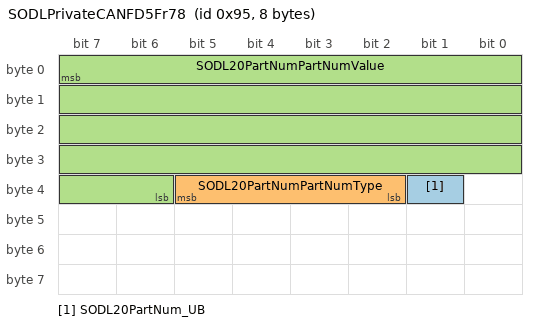
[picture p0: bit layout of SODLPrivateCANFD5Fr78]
BO_ 149 SODLPrivateCANFD5Fr78 : 8 SODL
 SG_ SODL20PartNum_UB : 33|1@0+ (1,0) [0|1] "" ASDM
 SG_ SODL20PartNumPartNumType : 37|4@0+ (1.0,0.0) [0.0|15.0] "Unitless" ASDM
 SG_ SODL20PartNumPartNumValue : 7|34@0+ (1.0,0.0) [0.0|17179869183.0] "Unitless" ASDM

BO_ 1282 SodlPrivateCanFD5NmFr01 : 8 SODL
 SG_ PNC16_SODL : 16|1@0+ (1,0) [0|0] "" ASDM
 SG_ PNC17_SODL : 17|1@0+ (1,0) [0|0] "" ASDM
 SG_ PNC18_SODL : 18|1@0+ (1,0) [0|0] "" ASDM
 SG_ PNC19_SODL : 19|1@0+ (1,0) [0|0] "" ASDM
 SG_ PNC20_SODL : 20|1@0+ (1,0) [0|0] "" ASDM
 SG_ PNC21_SODL : 21|1@0+ (1,0) [0|0] "" ASDM
 SG_ PNC22_SODL : 22|1@0+ (1,0) [0|0] "" ASDM
 SG_ PNC23_SODL : 23|1@0+ (1,0) [0|0] "" ASDM
 SG_ PNC24_SODL : 24|1@0+ (1,0) [0|0] "" ASDM
 SG_ PNC25_SODL : 25|1@0+ (1,0) [0|0] "" ASDM
 SG_ PNC26_SODL : 26|1@0+ (1,0) [0|0] "" ASDM
 SG_ PNC27_SODL : 27|1@0+ (1,0) [0|0] "" ASDM
 SG_ PNC28_SODL : 28|1@0+ (1,0) [0|0] "" ASDM
 SG_ PNC29_SODL : 29|1@0+ (1,0) [0|0] "" ASDM
 SG_ PNC30_SODL : 30|1@0+ (1,0) [0|0] "" ASDM
 SG_ PNC31_SODL : 31|1@0+ (1,0) [0|0] "" ASDM
 SG_ PNC32_SODL : 32|1@0+ (1,0) [0|0] "" ASDM
 SG_ PNC33_SODL : 33|1@0+ (1,0) [0|0] "" ASDM
 SG_ PNC34_SODL : 34|1@0+ (1,0) [0|0] "" ASDM
 SG_ PNC35_SODL : 35|1@0+ (1,0) [0|0] "" ASDM
 SG_ PNC36_SODL : 36|1@0+ (1,0) [0|0] "" ASDM
 SG_ PNC37_SODL : 37|1@0+ (1,0) [0|0] "" ASDM
 SG_ PNC38_SODL : 38|1@0+ (1,0) [0|0] "" ASDM
 SG_ PNC39_SODL : 39|1@0+ (1,0) [0|0] "" ASDM
 SG_ PNC40_SODL : 40|1@0+ (1,0) [0|0] "" ASDM
 SG_ PNC41_SODL : 41|1@0+ (1,0) [0|0] "" ASDM
 SG_ PNC42_SODL : 42|1@0+ (1,0) [0|0] "" ASDM
 SG_ NM_PNI_SODL : 14|1@0+ (1,0) [0|0] "" ASDM
 SG_ NM_AW_SODL : 12|1@0+ (1,0) [0|0] "" ASDM
 SG_ NM_CS_SODL : 11|1@0+ (1,0) [0|0] "" ASDM
 SG_ NM_RMR_SODL : 8|1@0+ (1,0) [0|0] "" ASDM
 SG_ NM_NodeID_SODL : 7|8@0+ (1,0) [0|0] "" ASDM

BO_ 1665 SodrToAdcuPrivateCanFD5DiagResFr : 64 SODL
 SG_ SodlToAdcuPrivateCanFD5DiagResNpdu : 7|512@0+ (1,0) [0|0] "" ASDM

CM_ SG_ 137 ReSideRdrLeDetn229RdrDetnAmbigState "Dection ambiguous status";
CM_ SG_ 137 ReSideRdrLeDetn229RdrDetnAssoTrkID "Associated tracker ID
";
CM_ SG_ 137 ReSideRdrLeDetn229RdrDetnAzi "Refer to the data element description in ReSideRdrLeDetn1 with the same data element name";
CM_ SG_ 137 ReSideRdrLeDetn229RdrDetnChks "Refer to the data element description in ReSideRdrLeDetn1 with the same data element name";
CM_ SG_ 137 ReSideRdrLeDetn229RdrDetnCntr "Refer to the data element description in ReSideRdrLeDetn1 with the same data element name";
CM_ SG_ 137 ReSideRdrLeDetn229RdrDetnConf "Refer to the data element description in ReSideRdrLeDetn1 with the same data element name";
CM_ SG_ 137 ReSideRdrLeDetn229RdrDetnElevn "Refer to the data element description in ReSideRdrLeDetn1 with the same data element name";
CM_ SG_ 137 ReSideRdrLeDetn229RdrDetnPwr "Refer to the data element description in ReSideRdrLeDetn1 with the same data element name";
CM_ SG_ 137 ReSideRdrLeDetn229RdrDetnRng "Refer to the data element description in ReSideRdrLeDetn1 with the same data element name";
CM_ SG_ 137 ReSideRdrLeDetn229RdrDetnRngV "Range Velocity";
CM_ SG_ 137 ReSideRdrLeDetn229RdrDetnSameRV "object with same distance and speed";
CM_ SG_ 137 ReSideRdrLeDetn229RdrDetnSts "Refer to the data element description in ReSideRdrLeDetn1 with the same data element name";
CM_ SG_ 137 ReSideRdrLeDetn230RdrDetnAmbigState "Dection ambiguous status";
CM_ SG_ 137 ReSideRdrLeDetn230RdrDetnAssoTrkID "Associated tracker ID
";
CM_ SG_ 137 ReSideRdrLeDetn230RdrDetnAzi "Refer to the data element description in ReSideRdrLeDetn1 with the same data element name";
CM_ SG_ 137 ReSideRdrLeDetn230RdrDetnChks "Refer to the data element description in ReSideRdrLeDetn1 with the same data element name";
CM_ SG_ 137 ReSideRdrLeDetn230RdrDetnCntr "Refer to the data element description in ReSideRdrLeDetn1 with the same data element name";
CM_ SG_ 137 ReSideRdrLeDetn230RdrDetnConf "Refer to the data element description in ReSideRdrLeDetn1 with the same data element name";
CM_ SG_ 137 ReSideRdrLeDetn230RdrDetnElevn "Refer to the data element description in ReSideRdrLeDetn1 with the same data element name";
CM_ SG_ 137 ReSideRdrLeDetn230RdrDetnPwr "Refer to the data element description in ReSideRdrLeDetn1 with the same data element name";
CM_ SG_ 137 ReSideRdrLeDetn230RdrDetnRng "Refer to the data element description in ReSideRdrLeDetn1 with the same data element name";
CM_ SG_ 137 ReSideRdrLeDetn230RdrDetnRngV "Range Velocity";
CM_ SG_ 137 ReSideRdrLeDetn230RdrDetnSameRV "object with same distance and speed";
CM_ SG_ 137 ReSideRdrLeDetn230RdrDetnSts "Refer to the data element description in ReSideRdrLeDetn1 with the same data element name";
CM_ SG_ 137 ReSideRdrLeDetn231RdrDetnAmbigState "Dection ambiguous status";
CM_ SG_ 137 ReSideRdrLeDetn231RdrDetnAssoTrkID "Associated tracker ID
";
CM_ SG_ 137 ReSideRdrLeDetn231RdrDetnAzi "Refer to the data element description in ReSideRdrLeDetn1 with the same data element name";
CM_ SG_ 137 ReSideRdrLeDetn231RdrDetnChks "Refer to the data element description in ReSideRdrLeDetn1 with the same data element name";
CM_ SG_ 137 ReSideRdrLeDetn231RdrDetnCntr "Refer to the data element description in ReSideRdrLeDetn1 with the same data element name";
CM_ SG_ 137 ReSideRdrLeDetn231RdrDetnConf "Refer to the data element description in ReSideRdrLeDetn1 with the same data element name";
CM_ SG_ 137 ReSideRdrLeDetn231RdrDetnElevn "Refer to the data element description in ReSideRdrLeDetn1 with the same data element name";
CM_ SG_ 137 ReSideRdrLeDetn231RdrDetnPwr "Refer to the data element description in ReSideRdrLeDetn1 with the same data element name";
CM_ SG_ 137 ReSideRdrLeDetn231RdrDetnRng "Refer to the data element description in ReSideRdrLeDetn1 with the same data element name";
CM_ SG_ 137 ReSideRdrLeDetn231RdrDetnRngV "Range Velocity";
CM_ SG_ 137 ReSideRdrLeDetn231RdrDetnSameRV "object with same distance and speed";
CM_ SG_ 137 ReSideRdrLeDetn231RdrDetnSts "Refer to the data element description in ReSideRdrLeDetn1 with the same data element name";
CM_ SG_ 137 ReSideRdrLeDetn232RdrDetnAmbigState "Dection ambiguous status";
CM_ SG_ 137 ReSideRdrLeDetn232RdrDetnAssoTrkID "Associated tracker ID
";
CM_ SG_ 137 ReSideRdrLeDetn232RdrDetnAzi "Refer to the data element description in ReSideRdrLeDetn1 with the same data element name";
CM_ SG_ 137 ReSideRdrLeDetn232RdrDetnChks "Refer to the data element description in ReSideRdrLeDetn1 with the same data element name";
CM_ SG_ 137 ReSideRdrLeDetn232RdrDetnCntr "Refer to the data element description in ReSideRdrLeDetn1 with the same data element name";
CM_ SG_ 137 ReSideRdrLeDetn232RdrDetnConf "Refer to the data element description in ReSideRdrLeDetn1 with the same data element name";
CM_ SG_ 137 ReSideRdrLeDetn232RdrDetnElevn "Refer to the data element description in ReSideRdrLeDetn1 with the same data element name";
CM_ SG_ 137 ReSideRdrLeDetn232RdrDetnPwr "Refer to the data element description in ReSideRdrLeDetn1 with the same data element name";
CM_ SG_ 137 ReSideRdrLeDetn232RdrDetnRng "Refer to the data element description in ReSideRdrLeDetn1 with the same data element name";
CM_ SG_ 137 ReSideRdrLeDetn232RdrDetnRngV "Range Velocity";
CM_ SG_ 137 ReSideRdrLeDetn232RdrDetnSameRV "object with same distance and speed";
CM_ SG_ 137 ReSideRdrLeDetn232RdrDetnSts "Refer to the data element description in ReSideRdrLeDetn1 with the same data element name";
CM_ SG_ 137 ReSideRdrLeDetn233RdrDetnAmbigState "Dection ambiguous status";
CM_ SG_ 137 ReSideRdrLeDetn233RdrDetnAssoTrkID "Associated tracker ID
";
CM_ SG_ 137 ReSideRdrLeDetn233RdrDetnAzi "Refer to the data element description in ReSideRdrLeDetn1 with the same data element name";
CM_ SG_ 137 ReSideRdrLeDetn233RdrDetnChks "Refer to the data element description in ReSideRdrLeDetn1 with the same data element name";
CM_ SG_ 137 ReSideRdrLeDetn233RdrDetnCntr "Refer to the data element description in ReSideRdrLeDetn1 with the same data element name";
CM_ SG_ 137 ReSideRdrLeDetn233RdrDetnConf "Refer to the data element description in ReSideRdrLeDetn1 with the same data element name";
CM_ SG_ 137 ReSideRdrLeDetn233RdrDetnElevn "Refer to the data element description in ReSideRdrLeDetn1 with the same data element name";
CM_ SG_ 137 ReSideRdrLeDetn233RdrDetnPwr "Refer to the data element description in ReSideRdrLeDetn1 with the same data element name";
CM_ SG_ 137 ReSideRdrLeDetn233RdrDetnRng "Refer to the data element description in ReSideRdrLeDetn1 with the same data element name";
CM_ SG_ 137 ReSideRdrLeDetn233RdrDetnRngV "Range Velocity";
CM_ SG_ 137 ReSideRdrLeDetn233RdrDetnSameRV "object with same distance and speed";
CM_ SG_ 137 ReSideRdrLeDetn233RdrDetnSts "Refer to the data element description in ReSideRdrLeDetn1 with the same data element name";
CM_ SG_ 137 ReSideRdrLeDetn234RdrDetnAmbigState "Dection ambiguous status";
CM_ SG_ 137 ReSideRdrLeDetn234RdrDetnAssoTrkID "Associated tracker ID
";
CM_ SG_ 137 ReSideRdrLeDetn234RdrDetnAzi "Refer to the data element description in ReSideRdrLeDetn1 with the same data element name";
CM_ SG_ 137 ReSideRdrLeDetn234RdrDetnChks "Refer to the data element description in ReSideRdrLeDetn1 with the same data element name";
CM_ SG_ 137 ReSideRdrLeDetn234RdrDetnCntr "Refer to the data element description in ReSideRdrLeDetn1 with the same data element name";
CM_ SG_ 137 ReSideRdrLeDetn234RdrDetnConf "Refer to the data element description in ReSideRdrLeDetn1 with the same data element name";
CM_ SG_ 137 ReSideRdrLeDetn234RdrDetnElevn "Refer to the data element description in ReSideRdrLeDetn1 with the same data element name";
CM_ SG_ 137 ReSideRdrLeDetn234RdrDetnPwr "Refer to the data element description in ReSideRdrLeDetn1 with the same data element name";
CM_ SG_ 137 ReSideRdrLeDetn234RdrDetnRng "Refer to the data element description in ReSideRdrLeDetn1 with the same data element name";
CM_ SG_ 137 ReSideRdrLeDetn234RdrDetnRngV "Range Velocity";
CM_ SG_ 137 ReSideRdrLeDetn234RdrDetnSameRV "object with same distance and speed";
CM_ SG_ 137 ReSideRdrLeDetn234RdrDetnSts "Refer to the data element description in ReSideRdrLeDetn1 with the same data element name";
CM_ SG_ 144 ReSideRdrLeDetn235RdrDetnAmbigState "Dection ambiguous status";
CM_ SG_ 144 ReSideRdrLeDetn235RdrDetnAssoTrkID "Associated tracker ID
";
CM_ SG_ 144 ReSideRdrLeDetn235RdrDetnAzi "Refer to the data element description in ReSideRdrLeDetn1 with the same data element name";
CM_ SG_ 144 ReSideRdrLeDetn235RdrDetnChks "Refer to the data element description in ReSideRdrLeDetn1 with the same data element name";
CM_ SG_ 144 ReSideRdrLeDetn235RdrDetnCntr "Refer to the data element description in ReSideRdrLeDetn1 with the same data element name";
CM_ SG_ 144 ReSideRdrLeDetn235RdrDetnConf "Refer to the data element description in ReSideRdrLeDetn1 with the same data element name";
CM_ SG_ 144 ReSideRdrLeDetn235RdrDetnElevn "Refer to the data element description in ReSideRdrLeDetn1 with the same data element name";
CM_ SG_ 144 ReSideRdrLeDetn235RdrDetnPwr "Refer to the data element description in ReSideRdrLeDetn1 with the same data element name";
CM_ SG_ 144 ReSideRdrLeDetn235RdrDetnRng "Refer to the data element description in ReSideRdrLeDetn1 with the same data element name";
CM_ SG_ 144 ReSideRdrLeDetn235RdrDetnRngV "Range Velocity";
CM_ SG_ 144 ReSideRdrLeDetn235RdrDetnSameRV "object with same distance and speed";
CM_ SG_ 144 ReSideRdrLeDetn235RdrDetnSts "Refer to the data element description in ReSideRdrLeDetn1 with the same data element name";
CM_ SG_ 144 ReSideRdrLeDetn236RdrDetnAmbigState "Dection ambiguous status";
CM_ SG_ 144 ReSideRdrLeDetn236RdrDetnAssoTrkID "Associated tracker ID
";
CM_ SG_ 144 ReSideRdrLeDetn236RdrDetnAzi "Refer to the data element description in ReSideRdrLeDetn1 with the same data element name";
CM_ SG_ 144 ReSideRdrLeDetn236RdrDetnChks "Refer to the data element description in ReSideRdrLeDetn1 with the same data element name";
CM_ SG_ 144 ReSideRdrLeDetn236RdrDetnCntr "Refer to the data element description in ReSideRdrLeDetn1 with the same data element name";
CM_ SG_ 144 ReSideRdrLeDetn236RdrDetnConf "Refer to the data element description in ReSideRdrLeDetn1 with the same data element name";
CM_ SG_ 144 ReSideRdrLeDetn236RdrDetnElevn "Refer to the data element description in ReSideRdrLeDetn1 with the same data element name";
CM_ SG_ 144 ReSideRdrLeDetn236RdrDetnPwr "Refer to the data element description in ReSideRdrLeDetn1 with the same data element name";
CM_ SG_ 144 ReSideRdrLeDetn236RdrDetnRng "Refer to the data element description in ReSideRdrLeDetn1 with the same data element name";
CM_ SG_ 144 ReSideRdrLeDetn236RdrDetnRngV "Range Velocity";
CM_ SG_ 144 ReSideRdrLeDetn236RdrDetnSameRV "object with same distance and speed";
CM_ SG_ 144 ReSideRdrLeDetn236RdrDetnSts "Refer to the data element description in ReSideRdrLeDetn1 with the same data element name";
CM_ SG_ 144 ReSideRdrLeDetn237RdrDetnAmbigState "Dection ambiguous status";
CM_ SG_ 144 ReSideRdrLeDetn237RdrDetnAssoTrkID "Associated tracker ID
";
CM_ SG_ 144 ReSideRdrLeDetn237RdrDetnAzi "Refer to the data element description in ReSideRdrLeDetn1 with the same data element name";
CM_ SG_ 144 ReSideRdrLeDetn237RdrDetnChks "Refer to the data element description in ReSideRdrLeDetn1 with the same data element name";
CM_ SG_ 144 ReSideRdrLeDetn237RdrDetnCntr "Refer to the data element description in ReSideRdrLeDetn1 with the same data element name";
CM_ SG_ 144 ReSideRdrLeDetn237RdrDetnConf "Refer to the data element description in ReSideRdrLeDetn1 with the same data element name";
CM_ SG_ 144 ReSideRdrLeDetn237RdrDetnElevn "Refer to the data element description in ReSideRdrLeDetn1 with the same data element name";
CM_ SG_ 144 ReSideRdrLeDetn237RdrDetnPwr "Refer to the data element description in ReSideRdrLeDetn1 with the same data element name";
CM_ SG_ 144 ReSideRdrLeDetn237RdrDetnRng "Refer to the data element description in ReSideRdrLeDetn1 with the same data element name";
CM_ SG_ 144 ReSideRdrLeDetn237RdrDetnRngV "Range Velocity";
CM_ SG_ 144 ReSideRdrLeDetn237RdrDetnSameRV "object with same distance and speed";
CM_ SG_ 144 ReSideRdrLeDetn237RdrDetnSts "Refer to the data element description in ReSideRdrLeDetn1 with the same data element name";
CM_ SG_ 144 ReSideRdrLeDetn238RdrDetnAmbigState "Dection ambiguous status";
CM_ SG_ 144 ReSideRdrLeDetn238RdrDetnAssoTrkID "Associated tracker ID
";
CM_ SG_ 144 ReSideRdrLeDetn238RdrDetnAzi "Refer to the data element description in ReSideRdrLeDetn1 with the same data element name";
CM_ SG_ 144 ReSideRdrLeDetn238RdrDetnChks "Refer to the data element description in ReSideRdrLeDetn1 with the same data element name";
CM_ SG_ 144 ReSideRdrLeDetn238RdrDetnCntr "Refer to the data element description in ReSideRdrLeDetn1 with the same data element name";
CM_ SG_ 144 ReSideRdrLeDetn238RdrDetnConf "Refer to the data element description in ReSideRdrLeDetn1 with the same data element name";
CM_ SG_ 144 ReSideRdrLeDetn238RdrDetnElevn "Refer to the data element description in ReSideRdrLeDetn1 with the same data element name";
CM_ SG_ 144 ReSideRdrLeDetn238RdrDetnPwr "Refer to the data element description in ReSideRdrLeDetn1 with the same data element name";
CM_ SG_ 144 ReSideRdrLeDetn238RdrDetnRng "Refer to the data element description in ReSideRdrLeDetn1 with the same data element name";
CM_ SG_ 144 ReSideRdrLeDetn238RdrDetnRngV "Range Velocity";
CM_ SG_ 144 ReSideRdrLeDetn238RdrDetnSameRV "object with same distance and speed";
CM_ SG_ 144 ReSideRdrLeDetn238RdrDetnSts "Refer to the data element description in ReSideRdrLeDetn1 with the same data element name";
CM_ SG_ 144 ReSideRdrLeDetn239RdrDetnAmbigState "Dection ambiguous status";
CM_ SG_ 144 ReSideRdrLeDetn239RdrDetnAssoTrkID "Associated tracker ID
";
CM_ SG_ 144 ReSideRdrLeDetn239RdrDetnAzi "Refer to the data element description in ReSideRdrLeDetn1 with the same data element name";
CM_ SG_ 144 ReSideRdrLeDetn239RdrDetnChks "Refer to the data element description in ReSideRdrLeDetn1 with the same data element name";
CM_ SG_ 144 ReSideRdrLeDetn239RdrDetnCntr "Refer to the data element description in ReSideRdrLeDetn1 with the same data element name";
CM_ SG_ 144 ReSideRdrLeDetn239RdrDetnConf "Refer to the data element description in ReSideRdrLeDetn1 with the same data element name";
CM_ SG_ 144 ReSideRdrLeDetn239RdrDetnElevn "Refer to the data element description in ReSideRdrLeDetn1 with the same data element name";
CM_ SG_ 144 ReSideRdrLeDetn239RdrDetnPwr "Refer to the data element description in ReSideRdrLeDetn1 with the same data element name";
CM_ SG_ 144 ReSideRdrLeDetn239RdrDetnRng "Refer to the data element description in ReSideRdrLeDetn1 with the same data element name";
CM_ SG_ 144 ReSideRdrLeDetn239RdrDetnRngV "Range Velocity";
CM_ SG_ 144 ReSideRdrLeDetn239RdrDetnSameRV "object with same distance and speed";
CM_ SG_ 144 ReSideRdrLeDetn239RdrDetnSts "Refer to the data element description in ReSideRdrLeDetn1 with the same data element name";
CM_ SG_ 144 ReSideRdrLeDetn240RdrDetnAmbigState "Dection ambiguous status";
CM_ SG_ 144 ReSideRdrLeDetn240RdrDetnAssoTrkID "Associated tracker ID
";
CM_ SG_ 144 ReSideRdrLeDetn240RdrDetnAzi "Refer to the data element description in ReSideRdrLeDetn1 with the same data element name";
CM_ SG_ 144 ReSideRdrLeDetn240RdrDetnChks "Refer to the data element description in ReSideRdrLeDetn1 with the same data element name";
CM_ SG_ 144 ReSideRdrLeDetn240RdrDetnCntr "Refer to the data element description in ReSideRdrLeDetn1 with the same data element name";
CM_ SG_ 144 ReSideRdrLeDetn240RdrDetnConf "Refer to the data element description in ReSideRdrLeDetn1 with the same data element name";
CM_ SG_ 144 ReSideRdrLeDetn240RdrDetnElevn "Refer to the data element description in ReSideRdrLeDetn1 with the same data element name";
CM_ SG_ 144 ReSideRdrLeDetn240RdrDetnPwr "Refer to the data element description in ReSideRdrLeDetn1 with the same data element name";
CM_ SG_ 144 ReSideRdrLeDetn240RdrDetnRng "Refer to the data element description in ReSideRdrLeDetn1 with the same data element name";
CM_ SG_ 144 ReSideRdrLeDetn240RdrDetnRngV "Range Velocity";
CM_ SG_ 144 ReSideRdrLeDetn240RdrDetnSameRV "object with same distance and speed";
CM_ SG_ 144 ReSideRdrLeDetn240RdrDetnSts "Refer to the data element description in ReSideRdrLeDetn1 with the same data element name";
CM_ SG_ 145 ReSideRdrLeDetn241RdrDetnAmbigState "Dection ambiguous status";
CM_ SG_ 145 ReSideRdrLeDetn241RdrDetnAssoTrkID "Associated tracker ID
";
CM_ SG_ 145 ReSideRdrLeDetn241RdrDetnAzi "Refer to the data element description in ReSideRdrLeDetn1 with the same data element name";
CM_ SG_ 145 ReSideRdrLeDetn241RdrDetnChks "Refer to the data element description in ReSideRdrLeDetn1 with the same data element name";
CM_ SG_ 145 ReSideRdrLeDetn241RdrDetnCntr "Refer to the data element description in ReSideRdrLeDetn1 with the same data element name";
CM_ SG_ 145 ReSideRdrLeDetn241RdrDetnConf "Refer to the data element description in ReSideRdrLeDetn1 with the same data element name";
CM_ SG_ 145 ReSideRdrLeDetn241RdrDetnElevn "Refer to the data element description in ReSideRdrLeDetn1 with the same data element name";
CM_ SG_ 145 ReSideRdrLeDetn241RdrDetnPwr "Refer to the data element description in ReSideRdrLeDetn1 with the same data element name";
CM_ SG_ 145 ReSideRdrLeDetn241RdrDetnRng "Refer to the data element description in ReSideRdrLeDetn1 with the same data element name";
CM_ SG_ 145 ReSideRdrLeDetn241RdrDetnRngV "Range Velocity";
CM_ SG_ 145 ReSideRdrLeDetn241RdrDetnSameRV "object with same distance and speed";
CM_ SG_ 145 ReSideRdrLeDetn241RdrDetnSts "Refer to the data element description in ReSideRdrLeDetn1 with the same data element name";
CM_ SG_ 145 ReSideRdrLeDetn242RdrDetnAmbigState "Dection ambiguous status";
CM_ SG_ 145 ReSideRdrLeDetn242RdrDetnAssoTrkID "Associated tracker ID
";
CM_ SG_ 145 ReSideRdrLeDetn242RdrDetnAzi "Refer to the data element description in ReSideRdrLeDetn1 with the same data element name";
CM_ SG_ 145 ReSideRdrLeDetn242RdrDetnChks "Refer to the data element description in ReSideRdrLeDetn1 with the same data element name";
CM_ SG_ 145 ReSideRdrLeDetn242RdrDetnCntr "Refer to the data element description in ReSideRdrLeDetn1 with the same data element name";
CM_ SG_ 145 ReSideRdrLeDetn242RdrDetnConf "Refer to the data element description in ReSideRdrLeDetn1 with the same data element name";
CM_ SG_ 145 ReSideRdrLeDetn242RdrDetnElevn "Refer to the data element description in ReSideRdrLeDetn1 with the same data element name";
CM_ SG_ 145 ReSideRdrLeDetn242RdrDetnPwr "Refer to the data element description in ReSideRdrLeDetn1 with the same data element name";
CM_ SG_ 145 ReSideRdrLeDetn242RdrDetnRng "Refer to the data element description in ReSideRdrLeDetn1 with the same data element name";
CM_ SG_ 145 ReSideRdrLeDetn242RdrDetnRngV "Range Velocity";
CM_ SG_ 145 ReSideRdrLeDetn242RdrDetnSameRV "object with same distance and speed";
CM_ SG_ 145 ReSideRdrLeDetn242RdrDetnSts "Refer to the data element description in ReSideRdrLeDetn1 with the same data element name";
CM_ SG_ 145 ReSideRdrLeDetn243RdrDetnAmbigState "Dection ambiguous status";
CM_ SG_ 145 ReSideRdrLeDetn243RdrDetnAssoTrkID "Associated tracker ID
";
CM_ SG_ 145 ReSideRdrLeDetn243RdrDetnAzi "Refer to the data element description in ReSideRdrLeDetn1 with the same data element name";
CM_ SG_ 145 ReSideRdrLeDetn243RdrDetnChks "Refer to the data element description in ReSideRdrLeDetn1 with the same data element name";
CM_ SG_ 145 ReSideRdrLeDetn243RdrDetnCntr "Refer to the data element description in ReSideRdrLeDetn1 with the same data element name";
CM_ SG_ 145 ReSideRdrLeDetn243RdrDetnConf "Refer to the data element description in ReSideRdrLeDetn1 with the same data element name";
CM_ SG_ 145 ReSideRdrLeDetn243RdrDetnElevn "Refer to the data element description in ReSideRdrLeDetn1 with the same data element name";
CM_ SG_ 145 ReSideRdrLeDetn243RdrDetnPwr "Refer to the data element description in ReSideRdrLeDetn1 with the same data element name";
CM_ SG_ 145 ReSideRdrLeDetn243RdrDetnRng "Refer to the data element description in ReSideRdrLeDetn1 with the same data element name";
CM_ SG_ 145 ReSideRdrLeDetn243RdrDetnRngV "Range Velocity";
CM_ SG_ 145 ReSideRdrLeDetn243RdrDetnSameRV "object with same distance and speed";
CM_ SG_ 145 ReSideRdrLeDetn243RdrDetnSts "Refer to the data element description in ReSideRdrLeDetn1 with the same data element name";
CM_ SG_ 145 ReSideRdrLeDetn244RdrDetnAmbigState "Dection ambiguous status";
CM_ SG_ 145 ReSideRdrLeDetn244RdrDetnAssoTrkID "Associated tracker ID
";
CM_ SG_ 145 ReSideRdrLeDetn244RdrDetnAzi "Refer to the data element description in ReSideRdrLeDetn1 with the same data element name";
CM_ SG_ 145 ReSideRdrLeDetn244RdrDetnChks "Refer to the data element description in ReSideRdrLeDetn1 with the same data element name";
CM_ SG_ 145 ReSideRdrLeDetn244RdrDetnCntr "Refer to the data element description in ReSideRdrLeDetn1 with the same data element name";
CM_ SG_ 145 ReSideRdrLeDetn244RdrDetnConf "Refer to the data element description in ReSideRdrLeDetn1 with the same data element name";
CM_ SG_ 145 ReSideRdrLeDetn244RdrDetnElevn "Refer to the data element description in ReSideRdrLeDetn1 with the same data element name";
CM_ SG_ 145 ReSideRdrLeDetn244RdrDetnPwr "Refer to the data element description in ReSideRdrLeDetn1 with the same data element name";
CM_ SG_ 145 ReSideRdrLeDetn244RdrDetnRng "Refer to the data element description in ReSideRdrLeDetn1 with the same data element name";
CM_ SG_ 145 ReSideRdrLeDetn244RdrDetnRngV "Range Velocity";
CM_ SG_ 145 ReSideRdrLeDetn244RdrDetnSameRV "object with same distance and speed";
CM_ SG_ 145 ReSideRdrLeDetn244RdrDetnSts "Refer to the data element description in ReSideRdrLeDetn1 with the same data element name";
CM_ SG_ 145 ReSideRdrLeDetn245RdrDetnAmbigState "Dection ambiguous status";
CM_ SG_ 145 ReSideRdrLeDetn245RdrDetnAssoTrkID "Associated tracker ID
";
CM_ SG_ 145 ReSideRdrLeDetn245RdrDetnAzi "Refer to the data element description in ReSideRdrLeDetn1 with the same data element name";
CM_ SG_ 145 ReSideRdrLeDetn245RdrDetnChks "Refer to the data element description in ReSideRdrLeDetn1 with the same data element name";
CM_ SG_ 145 ReSideRdrLeDetn245RdrDetnCntr "Refer to the data element description in ReSideRdrLeDetn1 with the same data element name";
CM_ SG_ 145 ReSideRdrLeDetn245RdrDetnConf "Refer to the data element description in ReSideRdrLeDetn1 with the same data element name";
CM_ SG_ 145 ReSideRdrLeDetn245RdrDetnElevn "Refer to the data element description in ReSideRdrLeDetn1 with the same data element name";
CM_ SG_ 145 ReSideRdrLeDetn245RdrDetnPwr "Refer to the data element description in ReSideRdrLeDetn1 with the same data element name";
CM_ SG_ 145 ReSideRdrLeDetn245RdrDetnRng "Refer to the data element description in ReSideRdrLeDetn1 with the same data element name";
CM_ SG_ 145 ReSideRdrLeDetn245RdrDetnRngV "Range Velocity";
CM_ SG_ 145 ReSideRdrLeDetn245RdrDetnSameRV "object with same distance and speed";
CM_ SG_ 145 ReSideRdrLeDetn245RdrDetnSts "Refer to the data element description in ReSideRdrLeDetn1 with the same data element name";
CM_ SG_ 145 ReSideRdrLeDetn246RdrDetnAmbigState "Dection ambiguous status";
CM_ SG_ 145 ReSideRdrLeDetn246RdrDetnAssoTrkID "Associated tracker ID
";
CM_ SG_ 145 ReSideRdrLeDetn246RdrDetnAzi "Refer to the data element description in ReSideRdrLeDetn1 with the same data element name";
CM_ SG_ 145 ReSideRdrLeDetn246RdrDetnChks "Refer to the data element description in ReSideRdrLeDetn1 with the same data element name";
CM_ SG_ 145 ReSideRdrLeDetn246RdrDetnCntr "Refer to the data element description in ReSideRdrLeDetn1 with the same data element name";
CM_ SG_ 145 ReSideRdrLeDetn246RdrDetnConf "Refer to the data element description in ReSideRdrLeDetn1 with the same data element name";
CM_ SG_ 145 ReSideRdrLeDetn246RdrDetnElevn "Refer to the data element description in ReSideRdrLeDetn1 with the same data element name";
CM_ SG_ 145 ReSideRdrLeDetn246RdrDetnPwr "Refer to the data element description in ReSideRdrLeDetn1 with the same data element name";
CM_ SG_ 145 ReSideRdrLeDetn246RdrDetnRng "Refer to the data element description in ReSideRdrLeDetn1 with the same data element name";
CM_ SG_ 145 ReSideRdrLeDetn246RdrDetnRngV "Range Velocity";
CM_ SG_ 145 ReSideRdrLeDetn246RdrDetnSameRV "object with same distance and speed";
CM_ SG_ 145 ReSideRdrLeDetn246RdrDetnSts "Refer to the data element description in ReSideRdrLeDetn1 with the same data element name";
CM_ SG_ 146 ReSideRdrLeDetn247RdrDetnAmbigState "Dection ambiguous status";
CM_ SG_ 146 ReSideRdrLeDetn247RdrDetnAssoTrkID "Associated tracker ID
";
CM_ SG_ 146 ReSideRdrLeDetn247RdrDetnAzi "Refer to the data element description in ReSideRdrLeDetn1 with the same data element name";
CM_ SG_ 146 ReSideRdrLeDetn247RdrDetnChks "Refer to the data element description in ReSideRdrLeDetn1 with the same data element name";
CM_ SG_ 146 ReSideRdrLeDetn247RdrDetnCntr "Refer to the data element description in ReSideRdrLeDetn1 with the same data element name";
CM_ SG_ 146 ReSideRdrLeDetn247RdrDetnConf "Refer to the data element description in ReSideRdrLeDetn1 with the same data element name";
CM_ SG_ 146 ReSideRdrLeDetn247RdrDetnElevn "Refer to the data element description in ReSideRdrLeDetn1 with the same data element name";
CM_ SG_ 146 ReSideRdrLeDetn247RdrDetnPwr "Refer to the data element description in ReSideRdrLeDetn1 with the same data element name";
CM_ SG_ 146 ReSideRdrLeDetn247RdrDetnRng "Refer to the data element description in ReSideRdrLeDetn1 with the same data element name";
CM_ SG_ 146 ReSideRdrLeDetn247RdrDetnRngV "Range Velocity";
CM_ SG_ 146 ReSideRdrLeDetn247RdrDetnSameRV "object with same distance and speed";
CM_ SG_ 146 ReSideRdrLeDetn247RdrDetnSts "Refer to the data element description in ReSideRdrLeDetn1 with the same data element name";
CM_ SG_ 146 ReSideRdrLeDetn248RdrDetnAmbigState "Dection ambiguous status";
CM_ SG_ 146 ReSideRdrLeDetn248RdrDetnAssoTrkID "Associated tracker ID
";
CM_ SG_ 146 ReSideRdrLeDetn248RdrDetnAzi "Refer to the data element description in ReSideRdrLeDetn1 with the same data element name";
CM_ SG_ 146 ReSideRdrLeDetn248RdrDetnChks "Refer to the data element description in ReSideRdrLeDetn1 with the same data element name";
CM_ SG_ 146 ReSideRdrLeDetn248RdrDetnCntr "Refer to the data element description in ReSideRdrLeDetn1 with the same data element name";
CM_ SG_ 146 ReSideRdrLeDetn248RdrDetnConf "Refer to the data element description in ReSideRdrLeDetn1 with the same data element name";
CM_ SG_ 146 ReSideRdrLeDetn248RdrDetnElevn "Refer to the data element description in ReSideRdrLeDetn1 with the same data element name";
CM_ SG_ 146 ReSideRdrLeDetn248RdrDetnPwr "Refer to the data element description in ReSideRdrLeDetn1 with the same data element name";
CM_ SG_ 146 ReSideRdrLeDetn248RdrDetnRng "Refer to the data element description in ReSideRdrLeDetn1 with the same data element name";
CM_ SG_ 146 ReSideRdrLeDetn248RdrDetnRngV "Range Velocity";
CM_ SG_ 146 ReSideRdrLeDetn248RdrDetnSameRV "object with same distance and speed";
CM_ SG_ 146 ReSideRdrLeDetn248RdrDetnSts "Refer to the data element description in ReSideRdrLeDetn1 with the same data element name";
CM_ SG_ 146 ReSideRdrLeDetn249RdrDetnAmbigState "Dection ambiguous status";
CM_ SG_ 146 ReSideRdrLeDetn249RdrDetnAssoTrkID "Associated tracker ID
";
CM_ SG_ 146 ReSideRdrLeDetn249RdrDetnAzi "Refer to the data element description in ReSideRdrLeDetn1 with the same data element name";
CM_ SG_ 146 ReSideRdrLeDetn249RdrDetnChks "Refer to the data element description in ReSideRdrLeDetn1 with the same data element name";
CM_ SG_ 146 ReSideRdrLeDetn249RdrDetnCntr "Refer to the data element description in ReSideRdrLeDetn1 with the same data element name";
CM_ SG_ 146 ReSideRdrLeDetn249RdrDetnConf "Refer to the data element description in ReSideRdrLeDetn1 with the same data element name";
CM_ SG_ 146 ReSideRdrLeDetn249RdrDetnElevn "Refer to the data element description in ReSideRdrLeDetn1 with the same data element name";
CM_ SG_ 146 ReSideRdrLeDetn249RdrDetnPwr "Refer to the data element description in ReSideRdrLeDetn1 with the same data element name";
CM_ SG_ 146 ReSideRdrLeDetn249RdrDetnRng "Refer to the data element description in ReSideRdrLeDetn1 with the same data element name";
CM_ SG_ 146 ReSideRdrLeDetn249RdrDetnRngV "Range Velocity";
CM_ SG_ 146 ReSideRdrLeDetn249RdrDetnSameRV "object with same distance and speed";
CM_ SG_ 146 ReSideRdrLeDetn249RdrDetnSts "Refer to the data element description in ReSideRdrLeDetn1 with the same data element name";
CM_ SG_ 146 ReSideRdrLeDetn250RdrDetnAmbigState "Dection ambiguous status";
CM_ SG_ 146 ReSideRdrLeDetn250RdrDetnAssoTrkID "Associated tracker ID
";
CM_ SG_ 146 ReSideRdrLeDetn250RdrDetnAzi "Refer to the data element description in ReSideRdrLeDetn1 with the same data element name";
CM_ SG_ 146 ReSideRdrLeDetn250RdrDetnChks "Refer to the data element description in ReSideRdrLeDetn1 with the same data element name";
CM_ SG_ 146 ReSideRdrLeDetn250RdrDetnCntr "Refer to the data element description in ReSideRdrLeDetn1 with the same data element name";
CM_ SG_ 146 ReSideRdrLeDetn250RdrDetnConf "Refer to the data element description in ReSideRdrLeDetn1 with the same data element name";
CM_ SG_ 146 ReSideRdrLeDetn250RdrDetnElevn "Refer to the data element description in ReSideRdrLeDetn1 with the same data element name";
CM_ SG_ 146 ReSideRdrLeDetn250RdrDetnPwr "Refer to the data element description in ReSideRdrLeDetn1 with the same data element name";
CM_ SG_ 146 ReSideRdrLeDetn250RdrDetnRng "Refer to the data element description in ReSideRdrLeDetn1 with the same data element name";
CM_ SG_ 146 ReSideRdrLeDetn250RdrDetnRngV "Range Velocity";
CM_ SG_ 146 ReSideRdrLeDetn250RdrDetnSameRV "object with same distance and speed";
CM_ SG_ 146 ReSideRdrLeDetn250RdrDetnSts "Refer to the data element description in ReSideRdrLeDetn1 with the same data element name";
CM_ SG_ 146 ReSideRdrLeDetn251RdrDetnAmbigState "Dection ambiguous status";
CM_ SG_ 146 ReSideRdrLeDetn251RdrDetnAssoTrkID "Associated tracker ID
";
CM_ SG_ 146 ReSideRdrLeDetn251RdrDetnAzi "Refer to the data element description in ReSideRdrLeDetn1 with the same data element name";
CM_ SG_ 146 ReSideRdrLeDetn251RdrDetnChks "Refer to the data element description in ReSideRdrLeDetn1 with the same data element name";
CM_ SG_ 146 ReSideRdrLeDetn251RdrDetnCntr "Refer to the data element description in ReSideRdrLeDetn1 with the same data element name";
CM_ SG_ 146 ReSideRdrLeDetn251RdrDetnConf "Refer to the data element description in ReSideRdrLeDetn1 with the same data element name";
CM_ SG_ 146 ReSideRdrLeDetn251RdrDetnElevn "Refer to the data element description in ReSideRdrLeDetn1 with the same data element name";
CM_ SG_ 146 ReSideRdrLeDetn251RdrDetnPwr "Refer to the data element description in ReSideRdrLeDetn1 with the same data element name";
CM_ SG_ 146 ReSideRdrLeDetn251RdrDetnRng "Refer to the data element description in ReSideRdrLeDetn1 with the same data element name";
CM_ SG_ 146 ReSideRdrLeDetn251RdrDetnRngV "Range Velocity";
CM_ SG_ 146 ReSideRdrLeDetn251RdrDetnSameRV "object with same distance and speed";
CM_ SG_ 146 ReSideRdrLeDetn251RdrDetnSts "Refer to the data element description in ReSideRdrLeDetn1 with the same data element name";
CM_ SG_ 146 ReSideRdrLeDetn252RdrDetnAmbigState "Dection ambiguous status";
CM_ SG_ 146 ReSideRdrLeDetn252RdrDetnAssoTrkID "Associated tracker ID
";
CM_ SG_ 146 ReSideRdrLeDetn252RdrDetnAzi "Refer to the data element description in ReSideRdrLeDetn1 with the same data element name";
CM_ SG_ 146 ReSideRdrLeDetn252RdrDetnChks "Refer to the data element description in ReSideRdrLeDetn1 with the same data element name";
CM_ SG_ 146 ReSideRdrLeDetn252RdrDetnCntr "Refer to the data element description in ReSideRdrLeDetn1 with the same data element name";
CM_ SG_ 146 ReSideRdrLeDetn252RdrDetnConf "Refer to the data element description in ReSideRdrLeDetn1 with the same data element name";
CM_ SG_ 146 ReSideRdrLeDetn252RdrDetnElevn "Refer to the data element description in ReSideRdrLeDetn1 with the same data element name";
CM_ SG_ 146 ReSideRdrLeDetn252RdrDetnPwr "Refer to the data element description in ReSideRdrLeDetn1 with the same data element name";
CM_ SG_ 146 ReSideRdrLeDetn252RdrDetnRng "Refer to the data element description in ReSideRdrLeDetn1 with the same data element name";
CM_ SG_ 146 ReSideRdrLeDetn252RdrDetnRngV "Range Velocity";
CM_ SG_ 146 ReSideRdrLeDetn252RdrDetnSameRV "object with same distance and speed";
CM_ SG_ 146 ReSideRdrLeDetn252RdrDetnSts "Refer to the data element description in ReSideRdrLeDetn1 with the same data element name";
CM_ SG_ 147 ReSideRdrLeDetn253RdrDetnAmbigState "Dection ambiguous status";
CM_ SG_ 147 ReSideRdrLeDetn253RdrDetnAssoTrkID "Associated tracker ID
";
CM_ SG_ 147 ReSideRdrLeDetn253RdrDetnAzi "Refer to the data element description in ReSideRdrLeDetn1 with the same data element name";
CM_ SG_ 147 ReSideRdrLeDetn253RdrDetnChks "Refer to the data element description in ReSideRdrLeDetn1 with the same data element name";
CM_ SG_ 147 ReSideRdrLeDetn253RdrDetnCntr "Refer to the data element description in ReSideRdrLeDetn1 with the same data element name";
CM_ SG_ 147 ReSideRdrLeDetn253RdrDetnConf "Refer to the data element description in ReSideRdrLeDetn1 with the same data element name";
CM_ SG_ 147 ReSideRdrLeDetn253RdrDetnElevn "Refer to the data element description in ReSideRdrLeDetn1 with the same data element name";
CM_ SG_ 147 ReSideRdrLeDetn253RdrDetnPwr "Refer to the data element description in ReSideRdrLeDetn1 with the same data element name";
CM_ SG_ 147 ReSideRdrLeDetn253RdrDetnRng "Refer to the data element description in ReSideRdrLeDetn1 with the same data element name";
CM_ SG_ 147 ReSideRdrLeDetn253RdrDetnRngV "Range Velocity";
CM_ SG_ 147 ReSideRdrLeDetn253RdrDetnSameRV "object with same distance and speed";
CM_ SG_ 147 ReSideRdrLeDetn253RdrDetnSts "Refer to the data element description in ReSideRdrLeDetn1 with the same data element name";
CM_ SG_ 147 ReSideRdrLeDetn254RdrDetnAmbigState "Dection ambiguous status";
CM_ SG_ 147 ReSideRdrLeDetn254RdrDetnAssoTrkID "Associated tracker ID
";
CM_ SG_ 147 ReSideRdrLeDetn254RdrDetnAzi "Refer to the data element description in ReSideRdrLeDetn1 with the same data element name";
CM_ SG_ 147 ReSideRdrLeDetn254RdrDetnChks "Refer to the data element description in ReSideRdrLeDetn1 with the same data element name";
CM_ SG_ 147 ReSideRdrLeDetn254RdrDetnCntr "Refer to the data element description in ReSideRdrLeDetn1 with the same data element name";
CM_ SG_ 147 ReSideRdrLeDetn254RdrDetnConf "Refer to the data element description in ReSideRdrLeDetn1 with the same data element name";
CM_ SG_ 147 ReSideRdrLeDetn254RdrDetnElevn "Refer to the data element description in ReSideRdrLeDetn1 with the same data element name";
CM_ SG_ 147 ReSideRdrLeDetn254RdrDetnPwr "Refer to the data element description in ReSideRdrLeDetn1 with the same data element name";
CM_ SG_ 147 ReSideRdrLeDetn254RdrDetnRng "Refer to the data element description in ReSideRdrLeDetn1 with the same data element name";
CM_ SG_ 147 ReSideRdrLeDetn254RdrDetnRngV "Range Velocity";
CM_ SG_ 147 ReSideRdrLeDetn254RdrDetnSameRV "object with same distance and speed";
CM_ SG_ 147 ReSideRdrLeDetn254RdrDetnSts "Refer to the data element description in ReSideRdrLeDetn1 with the same data element name";
CM_ SG_ 147 ReSideRdrLeDetn255RdrDetnAmbigState "Dection ambiguous status";
CM_ SG_ 147 ReSideRdrLeDetn255RdrDetnAssoTrkID "Associated tracker ID
";
CM_ SG_ 147 ReSideRdrLeDetn255RdrDetnAzi "Refer to the data element description in ReSideRdrLeDetn1 with the same data element name";
CM_ SG_ 147 ReSideRdrLeDetn255RdrDetnChks "Refer to the data element description in ReSideRdrLeDetn1 with the same data element name";
CM_ SG_ 147 ReSideRdrLeDetn255RdrDetnCntr "Refer to the data element description in ReSideRdrLeDetn1 with the same data element name";
CM_ SG_ 147 ReSideRdrLeDetn255RdrDetnConf "Refer to the data element description in ReSideRdrLeDetn1 with the same data element name";
CM_ SG_ 147 ReSideRdrLeDetn255RdrDetnElevn "Refer to the data element description in ReSideRdrLeDetn1 with the same data element name";
CM_ SG_ 147 ReSideRdrLeDetn255RdrDetnPwr "Refer to the data element description in ReSideRdrLeDetn1 with the same data element name";
CM_ SG_ 147 ReSideRdrLeDetn255RdrDetnRng "Refer to the data element description in ReSideRdrLeDetn1 with the same data element name";
CM_ SG_ 147 ReSideRdrLeDetn255RdrDetnRngV "Range Velocity";
CM_ SG_ 147 ReSideRdrLeDetn255RdrDetnSameRV "object with same distance and speed";
CM_ SG_ 147 ReSideRdrLeDetn255RdrDetnSts "Refer to the data element description in ReSideRdrLeDetn1 with the same data element name";
CM_ SG_ 147 ReSideRdrLeDetn256RdrDetnAmbigState "Dection ambiguous status";
CM_ SG_ 147 ReSideRdrLeDetn256RdrDetnAssoTrkID "Associated tracker ID
";
CM_ SG_ 147 ReSideRdrLeDetn256RdrDetnAzi "Refer to the data element description in ReSideRdrLeDetn1 with the same data element name";
CM_ SG_ 147 ReSideRdrLeDetn256RdrDetnChks "Refer to the data element description in ReSideRdrLeDetn1 with the same data element name";
CM_ SG_ 147 ReSideRdrLeDetn256RdrDetnCntr "Refer to the data element description in ReSideRdrLeDetn1 with the same data element name";
CM_ SG_ 147 ReSideRdrLeDetn256RdrDetnConf "Refer to the data element description in ReSideRdrLeDetn1 with the same data element name";
CM_ SG_ 147 ReSideRdrLeDetn256RdrDetnElevn "Refer to the data element description in ReSideRdrLeDetn1 with the same data element name";
CM_ SG_ 147 ReSideRdrLeDetn256RdrDetnPwr "Refer to the data element description in ReSideRdrLeDetn1 with the same data element name";
CM_ SG_ 147 ReSideRdrLeDetn256RdrDetnRng "Refer to the data element description in ReSideRdrLeDetn1 with the same data element name";
CM_ SG_ 147 ReSideRdrLeDetn256RdrDetnRngV "Range Velocity";
CM_ SG_ 147 ReSideRdrLeDetn256RdrDetnSameRV "object with same distance and speed";
CM_ SG_ 147 ReSideRdrLeDetn256RdrDetnSts "Refer to the data element description in ReSideRdrLeDetn1 with the same data element name";
CM_ SG_ 148 ReSideRdrLeDetTiSyncRdrStsDetChks "Checksum";
CM_ SG_ 148 ReSideRdrLeDetTiSyncRdrStsDetCntr "Counter";
CM_ SG_ 148 ReSideRdrLeDetTiSyncRdrStsDetLatency "The time instance starting from the end of the last measurement acquisition per cycle to the CAN-FD frames being outputted on the CAN-FD bus";
CM_ SG_ 148 ReSideRdrLeDetTiSyncRdrStsDetTiStamp20 "Timestamp; Seconds part of the time";
CM_ SG_ 148 ReSideRdrLeDetTiSyncRdrStsDetTiStampHi20 "Timestamp; Seconds part of the time";
CM_ SG_ 148 ReSideRdrLeDetTiSyncRdrStsDetTiStampNano20 "Timestamp; Nano Seconds part of the time";
CM_ SG_ 148 ReSideRdrLeDetTiSyncRdrStsDetTistampStsGlbTiBas "Timestamp";
CM_ SG_ 148 ReSideRdrLeDetTiSyncRdrStsDetTistampStsSyncToGateway "Time synchronization status - synchronized to gateway";
CM_ SG_ 148 ReSideRdrLeDetTiSyncRdrStsDetTistampStsTiLeap "Time synchronization status - time leap";
CM_ SG_ 148 ReSideRdrLeDetTiSyncRdrStsDetTistampStsTiOut "Time synchronization status - time out";
CM_ SG_ 149 SODL20PartNumPartNumType "SODL20 part number counter";
CM_ SG_ 149 SODL20PartNumPartNumValue "SODL20 part number value";
BA_DEF_ BO_ "CANFD_BRS" ENUM "0","1";
BA_DEF_ BO_ "GenMsgCycleTime" INT 0 65536; // [ms]
BA_DEF_ BO_ "GenMsgDelayTime" INT 0 65536; // [ms]
BA_DEF_ BO_ "GenMsgSendType" ENUM "cyclic", "spontaneous", "not-used", "not-used", "not-used", "cyclicAndSpontaneous", "not-used", "cyclicIfActive", "NoMsgSendType"; // [us]
BA_DEF_ BO_ "GenMsgStartDelayTime" INT 0 65536; // [ms]
BA_DEF_ BO_ "VFrameFormat" ENUM "StandardCAN","ExtendedCAN","reserved","J1939PG","reserved","reserved","reserved","reserved","reserved","reserved","reserved","reserved","reserved","reserved","StandardCAN_FD","ExtendedCAN_FD";
BA_DEF_ SG_ "GenSigSendType" ENUM "Cyclic","OnWrite","OnWriteWithRepetition","OnChange","OnChangeWithRepetition","IfActive","IfActiveWithRepetition","NoSigSendType";
BA_DEF_ SG_ "GenSigStartValue" HEX 0 80000000;
BA_DEF_ BO_ "GenMsgILSupport" ENUM "No","Yes";
BA_DEF_ BO_ "NmAsrMessage" ENUM "No","Yes";
BA_DEF_ SG_ "GenSigFuncType" ENUM "NoFunction","n/a","n/a","n/a","n/a","n/a","n/a","n/a","n/a","n/a","n/a","n/a","n/a","n/a","n/a","CHK","CNTR","n/a","n/a","n/a","CNTR_AR_01","CRC_AR_01_BOTH","CRC_AR_01_ALT","CRC_AR_01_LOW","CRC_AR_01_NIBBLE","CNTR_AR_04","CRC_AR_04A","CNTR_AR_05","CRC_AR_05";
BA_DEF_ SG_ "GenSigDataID" STRING;
BA_DEF_DEF_ "CANFD_BRS" "1";
BA_DEF_DEF_ "GenSigStartValue" 0;
BA_DEF_DEF_ "VFrameFormat" "J1939PG";
BA_DEF_DEF_ "GenSigSendType" "NoSigSendType";
BA_DEF_DEF_ "GenMsgCycleTime" 0;
BA_DEF_DEF_ "GenMsgDelayTime" 0;
BA_DEF_DEF_ "GenMsgStartDelayTime" 0;
BA_DEF_DEF_ "GenMsgSendType" "NoMsgSendType";
BA_DEF_DEF_ "GenMsgILSupport" "Yes";
BA_DEF_DEF_ "NmAsrMessage" "No";
BA_DEF_DEF_ "GenSigFuncType" "NoFunction";
BA_DEF_DEF_ "GenSigDataID" "";
// Frame: SODLPrivateCANFD5Fr72
BA_ "GenMsgCycleTime" BO_ 137 50 ;
BA_ "GenMsgSendType" BO_ 137 0;
BA_ "VFrameFormat" BO_ 137 14;
// Frame: SODLPrivateCANFD5Fr73
BA_ "GenMsgCycleTime" BO_ 144 50 ;
BA_ "GenMsgSendType" BO_ 144 0;
BA_ "VFrameFormat" BO_ 144 14;
// Frame: SODLPrivateCANFD5Fr74
BA_ "GenMsgCycleTime" BO_ 145 50 ;
BA_ "GenMsgSendType" BO_ 145 0;
BA_ "VFrameFormat" BO_ 145 14;
// Frame: SODLPrivateCANFD5Fr75
BA_ "GenMsgCycleTime" BO_ 146 50 ;
BA_ "GenMsgSendType" BO_ 146 0;
BA_ "VFrameFormat" BO_ 146 14;
// Frame: SODLPrivateCANFD5Fr76
BA_ "GenMsgCycleTime" BO_ 147 50 ;
BA_ "GenMsgSendType" BO_ 147 0;
BA_ "VFrameFormat" BO_ 147 14;
// Frame: SODLPrivateCANFD5Fr77
BA_ "GenMsgCycleTime" BO_ 148 50 ;
BA_ "GenMsgSendType" BO_ 148 0;
BA_ "VFrameFormat" BO_ 148 14;
// Frame: SODLPrivateCANFD5Fr78
BA_ "GenMsgCycleTime" BO_ 149 200 ;
BA_ "GenMsgSendType" BO_ 149 0;
BA_ "VFrameFormat" BO_ 149 14;
// Frame: SodlPrivateCanFD5NmFr01
BA_ "GenMsgDelayTime" BO_ 1282 20 ;
BA_ "GenMsgSendType" BO_ 1282 1;
BA_ "VFrameFormat" BO_ 1282 0;
// Frame: SodrToAdcuPrivateCanFD5DiagResFr
BA_ "GenMsgDelayTime" BO_ 1665 5 ;
BA_ "GenMsgSendType" BO_ 1665 1;
BA_ "VFrameFormat" BO_ 1665 14;
BA_ "GenMsgILSupport" BO_ 1282 0;
BA_ "NmAsrMessage" BO_ 1282 1;
BA_ "GenSigDataID" SG_ 148 ReSideRdrLeDetTiSyncRdrStsDetChks "0x1237";
BA_ "GenSigFuncType" SG_ 148 ReSideRdrLeDetTiSyncRdrStsDetChks 15;
BA_ "GenSigSendType" SG_ 148 ReSideRdrLeDetTiSyncRdrStsDetChks 0;
BA_ "GenSigFuncType" SG_ 148 ReSideRdrLeDetTiSyncRdrStsDetCntr 16;
BA_ "GenSigSendType" SG_ 148 ReSideRdrLeDetTiSyncRdrStsDetCntr 0;
BA_ "GenSigSendType" SG_ 148 ReSideRdrLeDetTiSyncRdrStsDetLatency 0;
BA_ "GenSigSendType" SG_ 148 ReSideRdrLeDetTiSyncRdrStsDetTiStamp20 0;
BA_ "GenSigSendType" SG_ 148 ReSideRdrLeDetTiSyncRdrStsDetTiStampHi20 0;
BA_ "GenSigSendType" SG_ 148 ReSideRdrLeDetTiSyncRdrStsDetTiStampNano20 0;
BA_ "GenSigSendType" SG_ 148 ReSideRdrLeDetTiSyncRdrStsDetTistampStsGlbTiBas 0;
BA_ "GenSigSendType" SG_ 148 ReSideRdrLeDetTiSyncRdrStsDetTistampStsSyncToGateway 0;
BA_ "GenSigSendType" SG_ 148 ReSideRdrLeDetTiSyncRdrStsDetTistampStsTiLeap 0;
BA_ "GenSigSendType" SG_ 148 ReSideRdrLeDetTiSyncRdrStsDetTistampStsTiOut 0;
BA_ "GenSigSendType" SG_ 137 ReSideRdrLeDetn229RdrDetnAmbigState 0;
BA_ "GenSigSendType" SG_ 137 ReSideRdrLeDetn229RdrDetnAssoTrkID 0;
BA_ "GenSigSendType" SG_ 137 ReSideRdrLeDetn229RdrDetnAzi 0;
BA_ "GenSigStartValue" SG_ 137 ReSideRdrLeDetn229RdrDetnAzi 900;
BA_ "GenSigDataID" SG_ 137 ReSideRdrLeDetn229RdrDetnChks "0x1141";
BA_ "GenSigFuncType" SG_ 137 ReSideRdrLeDetn229RdrDetnChks 15;
BA_ "GenSigSendType" SG_ 137 ReSideRdrLeDetn229RdrDetnChks 0;
BA_ "GenSigFuncType" SG_ 137 ReSideRdrLeDetn229RdrDetnCntr 16;
BA_ "GenSigSendType" SG_ 137 ReSideRdrLeDetn229RdrDetnCntr 0;
BA_ "GenSigSendType" SG_ 137 ReSideRdrLeDetn229RdrDetnConf 0;
BA_ "GenSigSendType" SG_ 137 ReSideRdrLeDetn229RdrDetnElevn 0;
BA_ "GenSigStartValue" SG_ 137 ReSideRdrLeDetn229RdrDetnElevn 15;
BA_ "GenSigSendType" SG_ 137 ReSideRdrLeDetn229RdrDetnPwr 0;
BA_ "GenSigSendType" SG_ 137 ReSideRdrLeDetn229RdrDetnRng 0;
BA_ "GenSigStartValue" SG_ 137 ReSideRdrLeDetn229RdrDetnRng 10050;
BA_ "GenSigSendType" SG_ 137 ReSideRdrLeDetn229RdrDetnRngV 0;
BA_ "GenSigStartValue" SG_ 137 ReSideRdrLeDetn229RdrDetnRngV 4000;
BA_ "GenSigSendType" SG_ 137 ReSideRdrLeDetn229RdrDetnSameRV 0;
BA_ "GenSigSendType" SG_ 137 ReSideRdrLeDetn229RdrDetnSts 0;
BA_ "GenSigStartValue" SG_ 137 ReSideRdrLeDetn229RdrDetnSts 3;
BA_ "GenSigSendType" SG_ 137 ReSideRdrLeDetn230RdrDetnAmbigState 0;
BA_ "GenSigSendType" SG_ 137 ReSideRdrLeDetn230RdrDetnAssoTrkID 0;
BA_ "GenSigSendType" SG_ 137 ReSideRdrLeDetn230RdrDetnAzi 0;
BA_ "GenSigStartValue" SG_ 137 ReSideRdrLeDetn230RdrDetnAzi 900;
BA_ "GenSigDataID" SG_ 137 ReSideRdrLeDetn230RdrDetnChks "0x1142";
BA_ "GenSigFuncType" SG_ 137 ReSideRdrLeDetn230RdrDetnChks 15;
BA_ "GenSigSendType" SG_ 137 ReSideRdrLeDetn230RdrDetnChks 0;
BA_ "GenSigFuncType" SG_ 137 ReSideRdrLeDetn230RdrDetnCntr 16;
BA_ "GenSigSendType" SG_ 137 ReSideRdrLeDetn230RdrDetnCntr 0;
BA_ "GenSigSendType" SG_ 137 ReSideRdrLeDetn230RdrDetnConf 0;
BA_ "GenSigSendType" SG_ 137 ReSideRdrLeDetn230RdrDetnElevn 0;
BA_ "GenSigStartValue" SG_ 137 ReSideRdrLeDetn230RdrDetnElevn 15;
BA_ "GenSigSendType" SG_ 137 ReSideRdrLeDetn230RdrDetnPwr 0;
BA_ "GenSigSendType" SG_ 137 ReSideRdrLeDetn230RdrDetnRng 0;
BA_ "GenSigStartValue" SG_ 137 ReSideRdrLeDetn230RdrDetnRng 10050;
BA_ "GenSigSendType" SG_ 137 ReSideRdrLeDetn230RdrDetnRngV 0;
BA_ "GenSigStartValue" SG_ 137 ReSideRdrLeDetn230RdrDetnRngV 4000;
BA_ "GenSigSendType" SG_ 137 ReSideRdrLeDetn230RdrDetnSameRV 0;
BA_ "GenSigSendType" SG_ 137 ReSideRdrLeDetn230RdrDetnSts 0;
BA_ "GenSigStartValue" SG_ 137 ReSideRdrLeDetn230RdrDetnSts 3;
BA_ "GenSigSendType" SG_ 137 ReSideRdrLeDetn231RdrDetnAmbigState 0;
BA_ "GenSigSendType" SG_ 137 ReSideRdrLeDetn231RdrDetnAssoTrkID 0;
BA_ "GenSigSendType" SG_ 137 ReSideRdrLeDetn231RdrDetnAzi 0;
BA_ "GenSigStartValue" SG_ 137 ReSideRdrLeDetn231RdrDetnAzi 900;
BA_ "GenSigDataID" SG_ 137 ReSideRdrLeDetn231RdrDetnChks "0x1143";
BA_ "GenSigFuncType" SG_ 137 ReSideRdrLeDetn231RdrDetnChks 15;
BA_ "GenSigSendType" SG_ 137 ReSideRdrLeDetn231RdrDetnChks 0;
BA_ "GenSigFuncType" SG_ 137 ReSideRdrLeDetn231RdrDetnCntr 16;
BA_ "GenSigSendType" SG_ 137 ReSideRdrLeDetn231RdrDetnCntr 0;
BA_ "GenSigSendType" SG_ 137 ReSideRdrLeDetn231RdrDetnConf 0;
BA_ "GenSigSendType" SG_ 137 ReSideRdrLeDetn231RdrDetnElevn 0;
BA_ "GenSigStartValue" SG_ 137 ReSideRdrLeDetn231RdrDetnElevn 15;
BA_ "GenSigSendType" SG_ 137 ReSideRdrLeDetn231RdrDetnPwr 0;
BA_ "GenSigSendType" SG_ 137 ReSideRdrLeDetn231RdrDetnRng 0;
BA_ "GenSigStartValue" SG_ 137 ReSideRdrLeDetn231RdrDetnRng 10050;
BA_ "GenSigSendType" SG_ 137 ReSideRdrLeDetn231RdrDetnRngV 0;
BA_ "GenSigStartValue" SG_ 137 ReSideRdrLeDetn231RdrDetnRngV 4000;
BA_ "GenSigSendType" SG_ 137 ReSideRdrLeDetn231RdrDetnSameRV 0;
BA_ "GenSigSendType" SG_ 137 ReSideRdrLeDetn231RdrDetnSts 0;
BA_ "GenSigStartValue" SG_ 137 ReSideRdrLeDetn231RdrDetnSts 3;
BA_ "GenSigSendType" SG_ 137 ReSideRdrLeDetn232RdrDetnAmbigState 0;
BA_ "GenSigSendType" SG_ 137 ReSideRdrLeDetn232RdrDetnAssoTrkID 0;
BA_ "GenSigSendType" SG_ 137 ReSideRdrLeDetn232RdrDetnAzi 0;
BA_ "GenSigStartValue" SG_ 137 ReSideRdrLeDetn232RdrDetnAzi 900;
BA_ "GenSigDataID" SG_ 137 ReSideRdrLeDetn232RdrDetnChks "0x1144";
BA_ "GenSigFuncType" SG_ 137 ReSideRdrLeDetn232RdrDetnChks 15;
BA_ "GenSigSendType" SG_ 137 ReSideRdrLeDetn232RdrDetnChks 0;
BA_ "GenSigFuncType" SG_ 137 ReSideRdrLeDetn232RdrDetnCntr 16;
BA_ "GenSigSendType" SG_ 137 ReSideRdrLeDetn232RdrDetnCntr 0;
BA_ "GenSigSendType" SG_ 137 ReSideRdrLeDetn232RdrDetnConf 0;
BA_ "GenSigSendType" SG_ 137 ReSideRdrLeDetn232RdrDetnElevn 0;
BA_ "GenSigStartValue" SG_ 137 ReSideRdrLeDetn232RdrDetnElevn 15;
BA_ "GenSigSendType" SG_ 137 ReSideRdrLeDetn232RdrDetnPwr 0;
BA_ "GenSigSendType" SG_ 137 ReSideRdrLeDetn232RdrDetnRng 0;
BA_ "GenSigStartValue" SG_ 137 ReSideRdrLeDetn232RdrDetnRng 10050;
BA_ "GenSigSendType" SG_ 137 ReSideRdrLeDetn232RdrDetnRngV 0;
BA_ "GenSigStartValue" SG_ 137 ReSideRdrLeDetn232RdrDetnRngV 4000;
BA_ "GenSigSendType" SG_ 137 ReSideRdrLeDetn232RdrDetnSameRV 0;
BA_ "GenSigSendType" SG_ 137 ReSideRdrLeDetn232RdrDetnSts 0;
BA_ "GenSigStartValue" SG_ 137 ReSideRdrLeDetn232RdrDetnSts 3;
BA_ "GenSigSendType" SG_ 137 ReSideRdrLeDetn233RdrDetnAmbigState 0;
BA_ "GenSigSendType" SG_ 137 ReSideRdrLeDetn233RdrDetnAssoTrkID 0;
BA_ "GenSigSendType" SG_ 137 ReSideRdrLeDetn233RdrDetnAzi 0;
BA_ "GenSigStartValue" SG_ 137 ReSideRdrLeDetn233RdrDetnAzi 900;
BA_ "GenSigDataID" SG_ 137 ReSideRdrLeDetn233RdrDetnChks "0x1145";
BA_ "GenSigFuncType" SG_ 137 ReSideRdrLeDetn233RdrDetnChks 15;
BA_ "GenSigSendType" SG_ 137 ReSideRdrLeDetn233RdrDetnChks 0;
BA_ "GenSigFuncType" SG_ 137 ReSideRdrLeDetn233RdrDetnCntr 16;
BA_ "GenSigSendType" SG_ 137 ReSideRdrLeDetn233RdrDetnCntr 0;
BA_ "GenSigSendType" SG_ 137 ReSideRdrLeDetn233RdrDetnConf 0;
BA_ "GenSigSendType" SG_ 137 ReSideRdrLeDetn233RdrDetnElevn 0;
BA_ "GenSigStartValue" SG_ 137 ReSideRdrLeDetn233RdrDetnElevn 15;
BA_ "GenSigSendType" SG_ 137 ReSideRdrLeDetn233RdrDetnPwr 0;
BA_ "GenSigSendType" SG_ 137 ReSideRdrLeDetn233RdrDetnRng 0;
BA_ "GenSigStartValue" SG_ 137 ReSideRdrLeDetn233RdrDetnRng 10050;
BA_ "GenSigSendType" SG_ 137 ReSideRdrLeDetn233RdrDetnRngV 0;
BA_ "GenSigStartValue" SG_ 137 ReSideRdrLeDetn233RdrDetnRngV 4000;
BA_ "GenSigSendType" SG_ 137 ReSideRdrLeDetn233RdrDetnSameRV 0;
BA_ "GenSigSendType" SG_ 137 ReSideRdrLeDetn233RdrDetnSts 0;
BA_ "GenSigStartValue" SG_ 137 ReSideRdrLeDetn233RdrDetnSts 3;
BA_ "GenSigSendType" SG_ 137 ReSideRdrLeDetn234RdrDetnAmbigState 0;
BA_ "GenSigSendType" SG_ 137 ReSideRdrLeDetn234RdrDetnAssoTrkID 0;
BA_ "GenSigSendType" SG_ 137 ReSideRdrLeDetn234RdrDetnAzi 0;
BA_ "GenSigStartValue" SG_ 137 ReSideRdrLeDetn234RdrDetnAzi 900;
BA_ "GenSigDataID" SG_ 137 ReSideRdrLeDetn234RdrDetnChks "0x1146";
BA_ "GenSigFuncType" SG_ 137 ReSideRdrLeDetn234RdrDetnChks 15;
BA_ "GenSigSendType" SG_ 137 ReSideRdrLeDetn234RdrDetnChks 0;
BA_ "GenSigFuncType" SG_ 137 ReSideRdrLeDetn234RdrDetnCntr 16;
BA_ "GenSigSendType" SG_ 137 ReSideRdrLeDetn234RdrDetnCntr 0;
BA_ "GenSigSendType" SG_ 137 ReSideRdrLeDetn234RdrDetnConf 0;
BA_ "GenSigSendType" SG_ 137 ReSideRdrLeDetn234RdrDetnElevn 0;
BA_ "GenSigStartValue" SG_ 137 ReSideRdrLeDetn234RdrDetnElevn 15;
BA_ "GenSigSendType" SG_ 137 ReSideRdrLeDetn234RdrDetnPwr 0;
BA_ "GenSigSendType" SG_ 137 ReSideRdrLeDetn234RdrDetnRng 0;
BA_ "GenSigStartValue" SG_ 137 ReSideRdrLeDetn234RdrDetnRng 10050;
BA_ "GenSigSendType" SG_ 137 ReSideRdrLeDetn234RdrDetnRngV 0;
BA_ "GenSigStartValue" SG_ 137 ReSideRdrLeDetn234RdrDetnRngV 4000;
BA_ "GenSigSendType" SG_ 137 ReSideRdrLeDetn234RdrDetnSameRV 0;
BA_ "GenSigSendType" SG_ 137 ReSideRdrLeDetn234RdrDetnSts 0;
BA_ "GenSigStartValue" SG_ 137 ReSideRdrLeDetn234RdrDetnSts 3;
BA_ "GenSigSendType" SG_ 144 ReSideRdrLeDetn235RdrDetnAmbigState 0;
BA_ "GenSigSendType" SG_ 144 ReSideRdrLeDetn235RdrDetnAssoTrkID 0;
BA_ "GenSigSendType" SG_ 144 ReSideRdrLeDetn235RdrDetnAzi 0;
BA_ "GenSigStartValue" SG_ 144 ReSideRdrLeDetn235RdrDetnAzi 900;
BA_ "GenSigDataID" SG_ 144 ReSideRdrLeDetn235RdrDetnChks "0x1147";
BA_ "GenSigFuncType" SG_ 144 ReSideRdrLeDetn235RdrDetnChks 15;
BA_ "GenSigSendType" SG_ 144 ReSideRdrLeDetn235RdrDetnChks 0;
BA_ "GenSigFuncType" SG_ 144 ReSideRdrLeDetn235RdrDetnCntr 16;
BA_ "GenSigSendType" SG_ 144 ReSideRdrLeDetn235RdrDetnCntr 0;
BA_ "GenSigSendType" SG_ 144 ReSideRdrLeDetn235RdrDetnConf 0;
BA_ "GenSigSendType" SG_ 144 ReSideRdrLeDetn235RdrDetnElevn 0;
BA_ "GenSigStartValue" SG_ 144 ReSideRdrLeDetn235RdrDetnElevn 15;
BA_ "GenSigSendType" SG_ 144 ReSideRdrLeDetn235RdrDetnPwr 0;
BA_ "GenSigSendType" SG_ 144 ReSideRdrLeDetn235RdrDetnRng 0;
BA_ "GenSigStartValue" SG_ 144 ReSideRdrLeDetn235RdrDetnRng 10050;
BA_ "GenSigSendType" SG_ 144 ReSideRdrLeDetn235RdrDetnRngV 0;
BA_ "GenSigStartValue" SG_ 144 ReSideRdrLeDetn235RdrDetnRngV 4000;
BA_ "GenSigSendType" SG_ 144 ReSideRdrLeDetn235RdrDetnSameRV 0;
BA_ "GenSigSendType" SG_ 144 ReSideRdrLeDetn235RdrDetnSts 0;
BA_ "GenSigStartValue" SG_ 144 ReSideRdrLeDetn235RdrDetnSts 3;
BA_ "GenSigSendType" SG_ 144 ReSideRdrLeDetn236RdrDetnAmbigState 0;
BA_ "GenSigSendType" SG_ 144 ReSideRdrLeDetn236RdrDetnAssoTrkID 0;
BA_ "GenSigSendType" SG_ 144 ReSideRdrLeDetn236RdrDetnAzi 0;
BA_ "GenSigStartValue" SG_ 144 ReSideRdrLeDetn236RdrDetnAzi 900;
BA_ "GenSigDataID" SG_ 144 ReSideRdrLeDetn236RdrDetnChks "0x1148";
BA_ "GenSigFuncType" SG_ 144 ReSideRdrLeDetn236RdrDetnChks 15;
BA_ "GenSigSendType" SG_ 144 ReSideRdrLeDetn236RdrDetnChks 0;
BA_ "GenSigFuncType" SG_ 144 ReSideRdrLeDetn236RdrDetnCntr 16;
BA_ "GenSigSendType" SG_ 144 ReSideRdrLeDetn236RdrDetnCntr 0;
BA_ "GenSigSendType" SG_ 144 ReSideRdrLeDetn236RdrDetnConf 0;
BA_ "GenSigSendType" SG_ 144 ReSideRdrLeDetn236RdrDetnElevn 0;
BA_ "GenSigStartValue" SG_ 144 ReSideRdrLeDetn236RdrDetnElevn 15;
BA_ "GenSigSendType" SG_ 144 ReSideRdrLeDetn236RdrDetnPwr 0;
BA_ "GenSigSendType" SG_ 144 ReSideRdrLeDetn236RdrDetnRng 0;
BA_ "GenSigStartValue" SG_ 144 ReSideRdrLeDetn236RdrDetnRng 10050;
BA_ "GenSigSendType" SG_ 144 ReSideRdrLeDetn236RdrDetnRngV 0;
BA_ "GenSigStartValue" SG_ 144 ReSideRdrLeDetn236RdrDetnRngV 4000;
BA_ "GenSigSendType" SG_ 144 ReSideRdrLeDetn236RdrDetnSameRV 0;
BA_ "GenSigSendType" SG_ 144 ReSideRdrLeDetn236RdrDetnSts 0;
BA_ "GenSigStartValue" SG_ 144 ReSideRdrLeDetn236RdrDetnSts 3;
BA_ "GenSigSendType" SG_ 144 ReSideRdrLeDetn237RdrDetnAmbigState 0;
BA_ "GenSigSendType" SG_ 144 ReSideRdrLeDetn237RdrDetnAssoTrkID 0;
BA_ "GenSigSendType" SG_ 144 ReSideRdrLeDetn237RdrDetnAzi 0;
BA_ "GenSigStartValue" SG_ 144 ReSideRdrLeDetn237RdrDetnAzi 900;
BA_ "GenSigDataID" SG_ 144 ReSideRdrLeDetn237RdrDetnChks "0x1149";
BA_ "GenSigFuncType" SG_ 144 ReSideRdrLeDetn237RdrDetnChks 15;
BA_ "GenSigSendType" SG_ 144 ReSideRdrLeDetn237RdrDetnChks 0;
BA_ "GenSigFuncType" SG_ 144 ReSideRdrLeDetn237RdrDetnCntr 16;
BA_ "GenSigSendType" SG_ 144 ReSideRdrLeDetn237RdrDetnCntr 0;
BA_ "GenSigSendType" SG_ 144 ReSideRdrLeDetn237RdrDetnConf 0;
BA_ "GenSigSendType" SG_ 144 ReSideRdrLeDetn237RdrDetnElevn 0;
BA_ "GenSigStartValue" SG_ 144 ReSideRdrLeDetn237RdrDetnElevn 15;
BA_ "GenSigSendType" SG_ 144 ReSideRdrLeDetn237RdrDetnPwr 0;
BA_ "GenSigSendType" SG_ 144 ReSideRdrLeDetn237RdrDetnRng 0;
BA_ "GenSigStartValue" SG_ 144 ReSideRdrLeDetn237RdrDetnRng 10050;
BA_ "GenSigSendType" SG_ 144 ReSideRdrLeDetn237RdrDetnRngV 0;
BA_ "GenSigStartValue" SG_ 144 ReSideRdrLeDetn237RdrDetnRngV 4000;
BA_ "GenSigSendType" SG_ 144 ReSideRdrLeDetn237RdrDetnSameRV 0;
BA_ "GenSigSendType" SG_ 144 ReSideRdrLeDetn237RdrDetnSts 0;
BA_ "GenSigStartValue" SG_ 144 ReSideRdrLeDetn237RdrDetnSts 3;
BA_ "GenSigSendType" SG_ 144 ReSideRdrLeDetn238RdrDetnAmbigState 0;
BA_ "GenSigSendType" SG_ 144 ReSideRdrLeDetn238RdrDetnAssoTrkID 0;
BA_ "GenSigSendType" SG_ 144 ReSideRdrLeDetn238RdrDetnAzi 0;
BA_ "GenSigStartValue" SG_ 144 ReSideRdrLeDetn238RdrDetnAzi 900;
BA_ "GenSigDataID" SG_ 144 ReSideRdrLeDetn238RdrDetnChks "0x114A";
BA_ "GenSigFuncType" SG_ 144 ReSideRdrLeDetn238RdrDetnChks 15;
BA_ "GenSigSendType" SG_ 144 ReSideRdrLeDetn238RdrDetnChks 0;
BA_ "GenSigFuncType" SG_ 144 ReSideRdrLeDetn238RdrDetnCntr 16;
BA_ "GenSigSendType" SG_ 144 ReSideRdrLeDetn238RdrDetnCntr 0;
BA_ "GenSigSendType" SG_ 144 ReSideRdrLeDetn238RdrDetnConf 0;
BA_ "GenSigSendType" SG_ 144 ReSideRdrLeDetn238RdrDetnElevn 0;
BA_ "GenSigStartValue" SG_ 144 ReSideRdrLeDetn238RdrDetnElevn 15;
BA_ "GenSigSendType" SG_ 144 ReSideRdrLeDetn238RdrDetnPwr 0;
BA_ "GenSigSendType" SG_ 144 ReSideRdrLeDetn238RdrDetnRng 0;
BA_ "GenSigStartValue" SG_ 144 ReSideRdrLeDetn238RdrDetnRng 10050;
BA_ "GenSigSendType" SG_ 144 ReSideRdrLeDetn238RdrDetnRngV 0;
BA_ "GenSigStartValue" SG_ 144 ReSideRdrLeDetn238RdrDetnRngV 4000;
BA_ "GenSigSendType" SG_ 144 ReSideRdrLeDetn238RdrDetnSameRV 0;
BA_ "GenSigSendType" SG_ 144 ReSideRdrLeDetn238RdrDetnSts 0;
BA_ "GenSigStartValue" SG_ 144 ReSideRdrLeDetn238RdrDetnSts 3;
BA_ "GenSigSendType" SG_ 144 ReSideRdrLeDetn239RdrDetnAmbigState 0;
BA_ "GenSigSendType" SG_ 144 ReSideRdrLeDetn239RdrDetnAssoTrkID 0;
BA_ "GenSigSendType" SG_ 144 ReSideRdrLeDetn239RdrDetnAzi 0;
BA_ "GenSigStartValue" SG_ 144 ReSideRdrLeDetn239RdrDetnAzi 900;
BA_ "GenSigDataID" SG_ 144 ReSideRdrLeDetn239RdrDetnChks "0x114B";
BA_ "GenSigFuncType" SG_ 144 ReSideRdrLeDetn239RdrDetnChks 15;
BA_ "GenSigSendType" SG_ 144 ReSideRdrLeDetn239RdrDetnChks 0;
BA_ "GenSigFuncType" SG_ 144 ReSideRdrLeDetn239RdrDetnCntr 16;
BA_ "GenSigSendType" SG_ 144 ReSideRdrLeDetn239RdrDetnCntr 0;
BA_ "GenSigSendType" SG_ 144 ReSideRdrLeDetn239RdrDetnConf 0;
BA_ "GenSigSendType" SG_ 144 ReSideRdrLeDetn239RdrDetnElevn 0;
BA_ "GenSigStartValue" SG_ 144 ReSideRdrLeDetn239RdrDetnElevn 15;
BA_ "GenSigSendType" SG_ 144 ReSideRdrLeDetn239RdrDetnPwr 0;
BA_ "GenSigSendType" SG_ 144 ReSideRdrLeDetn239RdrDetnRng 0;
BA_ "GenSigStartValue" SG_ 144 ReSideRdrLeDetn239RdrDetnRng 10050;
BA_ "GenSigSendType" SG_ 144 ReSideRdrLeDetn239RdrDetnRngV 0;
BA_ "GenSigStartValue" SG_ 144 ReSideRdrLeDetn239RdrDetnRngV 4000;
BA_ "GenSigSendType" SG_ 144 ReSideRdrLeDetn239RdrDetnSameRV 0;
BA_ "GenSigSendType" SG_ 144 ReSideRdrLeDetn239RdrDetnSts 0;
BA_ "GenSigStartValue" SG_ 144 ReSideRdrLeDetn239RdrDetnSts 3;
BA_ "GenSigSendType" SG_ 144 ReSideRdrLeDetn240RdrDetnAmbigState 0;
BA_ "GenSigSendType" SG_ 144 ReSideRdrLeDetn240RdrDetnAssoTrkID 0;
BA_ "GenSigSendType" SG_ 144 ReSideRdrLeDetn240RdrDetnAzi 0;
BA_ "GenSigStartValue" SG_ 144 ReSideRdrLeDetn240RdrDetnAzi 900;
BA_ "GenSigDataID" SG_ 144 ReSideRdrLeDetn240RdrDetnChks "0x114C";
BA_ "GenSigFuncType" SG_ 144 ReSideRdrLeDetn240RdrDetnChks 15;
BA_ "GenSigSendType" SG_ 144 ReSideRdrLeDetn240RdrDetnChks 0;
BA_ "GenSigFuncType" SG_ 144 ReSideRdrLeDetn240RdrDetnCntr 16;
BA_ "GenSigSendType" SG_ 144 ReSideRdrLeDetn240RdrDetnCntr 0;
BA_ "GenSigSendType" SG_ 144 ReSideRdrLeDetn240RdrDetnConf 0;
BA_ "GenSigSendType" SG_ 144 ReSideRdrLeDetn240RdrDetnElevn 0;
BA_ "GenSigStartValue" SG_ 144 ReSideRdrLeDetn240RdrDetnElevn 15;
BA_ "GenSigSendType" SG_ 144 ReSideRdrLeDetn240RdrDetnPwr 0;
BA_ "GenSigSendType" SG_ 144 ReSideRdrLeDetn240RdrDetnRng 0;
BA_ "GenSigStartValue" SG_ 144 ReSideRdrLeDetn240RdrDetnRng 10050;
BA_ "GenSigSendType" SG_ 144 ReSideRdrLeDetn240RdrDetnRngV 0;
BA_ "GenSigStartValue" SG_ 144 ReSideRdrLeDetn240RdrDetnRngV 4000;
BA_ "GenSigSendType" SG_ 144 ReSideRdrLeDetn240RdrDetnSameRV 0;
BA_ "GenSigSendType" SG_ 144 ReSideRdrLeDetn240RdrDetnSts 0;
BA_ "GenSigStartValue" SG_ 144 ReSideRdrLeDetn240RdrDetnSts 3;
BA_ "GenSigSendType" SG_ 145 ReSideRdrLeDetn241RdrDetnAmbigState 0;
BA_ "GenSigSendType" SG_ 145 ReSideRdrLeDetn241RdrDetnAssoTrkID 0;
BA_ "GenSigSendType" SG_ 145 ReSideRdrLeDetn241RdrDetnAzi 0;
BA_ "GenSigStartValue" SG_ 145 ReSideRdrLeDetn241RdrDetnAzi 900;
BA_ "GenSigDataID" SG_ 145 ReSideRdrLeDetn241RdrDetnChks "0x114D";
BA_ "GenSigFuncType" SG_ 145 ReSideRdrLeDetn241RdrDetnChks 15;
BA_ "GenSigSendType" SG_ 145 ReSideRdrLeDetn241RdrDetnChks 0;
BA_ "GenSigFuncType" SG_ 145 ReSideRdrLeDetn241RdrDetnCntr 16;
BA_ "GenSigSendType" SG_ 145 ReSideRdrLeDetn241RdrDetnCntr 0;
BA_ "GenSigSendType" SG_ 145 ReSideRdrLeDetn241RdrDetnConf 0;
BA_ "GenSigSendType" SG_ 145 ReSideRdrLeDetn241RdrDetnElevn 0;
BA_ "GenSigStartValue" SG_ 145 ReSideRdrLeDetn241RdrDetnElevn 15;
BA_ "GenSigSendType" SG_ 145 ReSideRdrLeDetn241RdrDetnPwr 0;
BA_ "GenSigSendType" SG_ 145 ReSideRdrLeDetn241RdrDetnRng 0;
BA_ "GenSigStartValue" SG_ 145 ReSideRdrLeDetn241RdrDetnRng 10050;
BA_ "GenSigSendType" SG_ 145 ReSideRdrLeDetn241RdrDetnRngV 0;
BA_ "GenSigStartValue" SG_ 145 ReSideRdrLeDetn241RdrDetnRngV 4000;
BA_ "GenSigSendType" SG_ 145 ReSideRdrLeDetn241RdrDetnSameRV 0;
BA_ "GenSigSendType" SG_ 145 ReSideRdrLeDetn241RdrDetnSts 0;
BA_ "GenSigStartValue" SG_ 145 ReSideRdrLeDetn241RdrDetnSts 3;
BA_ "GenSigSendType" SG_ 145 ReSideRdrLeDetn242RdrDetnAmbigState 0;
BA_ "GenSigSendType" SG_ 145 ReSideRdrLeDetn242RdrDetnAssoTrkID 0;
BA_ "GenSigSendType" SG_ 145 ReSideRdrLeDetn242RdrDetnAzi 0;
BA_ "GenSigStartValue" SG_ 145 ReSideRdrLeDetn242RdrDetnAzi 900;
BA_ "GenSigDataID" SG_ 145 ReSideRdrLeDetn242RdrDetnChks "0x114E";
BA_ "GenSigFuncType" SG_ 145 ReSideRdrLeDetn242RdrDetnChks 15;
BA_ "GenSigSendType" SG_ 145 ReSideRdrLeDetn242RdrDetnChks 0;
BA_ "GenSigFuncType" SG_ 145 ReSideRdrLeDetn242RdrDetnCntr 16;
BA_ "GenSigSendType" SG_ 145 ReSideRdrLeDetn242RdrDetnCntr 0;
BA_ "GenSigSendType" SG_ 145 ReSideRdrLeDetn242RdrDetnConf 0;
BA_ "GenSigSendType" SG_ 145 ReSideRdrLeDetn242RdrDetnElevn 0;
BA_ "GenSigStartValue" SG_ 145 ReSideRdrLeDetn242RdrDetnElevn 15;
BA_ "GenSigSendType" SG_ 145 ReSideRdrLeDetn242RdrDetnPwr 0;
BA_ "GenSigSendType" SG_ 145 ReSideRdrLeDetn242RdrDetnRng 0;
BA_ "GenSigStartValue" SG_ 145 ReSideRdrLeDetn242RdrDetnRng 10050;
BA_ "GenSigSendType" SG_ 145 ReSideRdrLeDetn242RdrDetnRngV 0;
BA_ "GenSigStartValue" SG_ 145 ReSideRdrLeDetn242RdrDetnRngV 4000;
BA_ "GenSigSendType" SG_ 145 ReSideRdrLeDetn242RdrDetnSameRV 0;
BA_ "GenSigSendType" SG_ 145 ReSideRdrLeDetn242RdrDetnSts 0;
BA_ "GenSigStartValue" SG_ 145 ReSideRdrLeDetn242RdrDetnSts 3;
BA_ "GenSigSendType" SG_ 145 ReSideRdrLeDetn243RdrDetnAmbigState 0;
BA_ "GenSigSendType" SG_ 145 ReSideRdrLeDetn243RdrDetnAssoTrkID 0;
BA_ "GenSigSendType" SG_ 145 ReSideRdrLeDetn243RdrDetnAzi 0;
BA_ "GenSigStartValue" SG_ 145 ReSideRdrLeDetn243RdrDetnAzi 900;
BA_ "GenSigDataID" SG_ 145 ReSideRdrLeDetn243RdrDetnChks "0x114F";
BA_ "GenSigFuncType" SG_ 145 ReSideRdrLeDetn243RdrDetnChks 15;
BA_ "GenSigSendType" SG_ 145 ReSideRdrLeDetn243RdrDetnChks 0;
BA_ "GenSigFuncType" SG_ 145 ReSideRdrLeDetn243RdrDetnCntr 16;
BA_ "GenSigSendType" SG_ 145 ReSideRdrLeDetn243RdrDetnCntr 0;
BA_ "GenSigSendType" SG_ 145 ReSideRdrLeDetn243RdrDetnConf 0;
BA_ "GenSigSendType" SG_ 145 ReSideRdrLeDetn243RdrDetnElevn 0;
BA_ "GenSigStartValue" SG_ 145 ReSideRdrLeDetn243RdrDetnElevn 15;
BA_ "GenSigSendType" SG_ 145 ReSideRdrLeDetn243RdrDetnPwr 0;
BA_ "GenSigSendType" SG_ 145 ReSideRdrLeDetn243RdrDetnRng 0;
BA_ "GenSigStartValue" SG_ 145 ReSideRdrLeDetn243RdrDetnRng 10050;
BA_ "GenSigSendType" SG_ 145 ReSideRdrLeDetn243RdrDetnRngV 0;
BA_ "GenSigStartValue" SG_ 145 ReSideRdrLeDetn243RdrDetnRngV 4000;
BA_ "GenSigSendType" SG_ 145 ReSideRdrLeDetn243RdrDetnSameRV 0;
BA_ "GenSigSendType" SG_ 145 ReSideRdrLeDetn243RdrDetnSts 0;
BA_ "GenSigStartValue" SG_ 145 ReSideRdrLeDetn243RdrDetnSts 3;
BA_ "GenSigSendType" SG_ 145 ReSideRdrLeDetn244RdrDetnAmbigState 0;
BA_ "GenSigSendType" SG_ 145 ReSideRdrLeDetn244RdrDetnAssoTrkID 0;
BA_ "GenSigSendType" SG_ 145 ReSideRdrLeDetn244RdrDetnAzi 0;
BA_ "GenSigStartValue" SG_ 145 ReSideRdrLeDetn244RdrDetnAzi 900;
BA_ "GenSigDataID" SG_ 145 ReSideRdrLeDetn244RdrDetnChks "0x1150";
BA_ "GenSigFuncType" SG_ 145 ReSideRdrLeDetn244RdrDetnChks 15;
BA_ "GenSigSendType" SG_ 145 ReSideRdrLeDetn244RdrDetnChks 0;
BA_ "GenSigFuncType" SG_ 145 ReSideRdrLeDetn244RdrDetnCntr 16;
BA_ "GenSigSendType" SG_ 145 ReSideRdrLeDetn244RdrDetnCntr 0;
BA_ "GenSigSendType" SG_ 145 ReSideRdrLeDetn244RdrDetnConf 0;
BA_ "GenSigSendType" SG_ 145 ReSideRdrLeDetn244RdrDetnElevn 0;
BA_ "GenSigStartValue" SG_ 145 ReSideRdrLeDetn244RdrDetnElevn 15;
BA_ "GenSigSendType" SG_ 145 ReSideRdrLeDetn244RdrDetnPwr 0;
BA_ "GenSigSendType" SG_ 145 ReSideRdrLeDetn244RdrDetnRng 0;
BA_ "GenSigStartValue" SG_ 145 ReSideRdrLeDetn244RdrDetnRng 10050;
BA_ "GenSigSendType" SG_ 145 ReSideRdrLeDetn244RdrDetnRngV 0;
BA_ "GenSigStartValue" SG_ 145 ReSideRdrLeDetn244RdrDetnRngV 4000;
BA_ "GenSigSendType" SG_ 145 ReSideRdrLeDetn244RdrDetnSameRV 0;
BA_ "GenSigSendType" SG_ 145 ReSideRdrLeDetn244RdrDetnSts 0;
BA_ "GenSigStartValue" SG_ 145 ReSideRdrLeDetn244RdrDetnSts 3;
BA_ "GenSigSendType" SG_ 145 ReSideRdrLeDetn245RdrDetnAmbigState 0;
BA_ "GenSigSendType" SG_ 145 ReSideRdrLeDetn245RdrDetnAssoTrkID 0;
BA_ "GenSigSendType" SG_ 145 ReSideRdrLeDetn245RdrDetnAzi 0;
BA_ "GenSigStartValue" SG_ 145 ReSideRdrLeDetn245RdrDetnAzi 900;
BA_ "GenSigDataID" SG_ 145 ReSideRdrLeDetn245RdrDetnChks "0x1151";
BA_ "GenSigFuncType" SG_ 145 ReSideRdrLeDetn245RdrDetnChks 15;
BA_ "GenSigSendType" SG_ 145 ReSideRdrLeDetn245RdrDetnChks 0;
BA_ "GenSigFuncType" SG_ 145 ReSideRdrLeDetn245RdrDetnCntr 16;
BA_ "GenSigSendType" SG_ 145 ReSideRdrLeDetn245RdrDetnCntr 0;
BA_ "GenSigSendType" SG_ 145 ReSideRdrLeDetn245RdrDetnConf 0;
BA_ "GenSigSendType" SG_ 145 ReSideRdrLeDetn245RdrDetnElevn 0;
BA_ "GenSigStartValue" SG_ 145 ReSideRdrLeDetn245RdrDetnElevn 15;
BA_ "GenSigSendType" SG_ 145 ReSideRdrLeDetn245RdrDetnPwr 0;
BA_ "GenSigSendType" SG_ 145 ReSideRdrLeDetn245RdrDetnRng 0;
BA_ "GenSigStartValue" SG_ 145 ReSideRdrLeDetn245RdrDetnRng 10050;
BA_ "GenSigSendType" SG_ 145 ReSideRdrLeDetn245RdrDetnRngV 0;
BA_ "GenSigStartValue" SG_ 145 ReSideRdrLeDetn245RdrDetnRngV 4000;
BA_ "GenSigSendType" SG_ 145 ReSideRdrLeDetn245RdrDetnSameRV 0;
BA_ "GenSigSendType" SG_ 145 ReSideRdrLeDetn245RdrDetnSts 0;
BA_ "GenSigStartValue" SG_ 145 ReSideRdrLeDetn245RdrDetnSts 3;
BA_ "GenSigSendType" SG_ 145 ReSideRdrLeDetn246RdrDetnAmbigState 0;
BA_ "GenSigSendType" SG_ 145 ReSideRdrLeDetn246RdrDetnAssoTrkID 0;
BA_ "GenSigSendType" SG_ 145 ReSideRdrLeDetn246RdrDetnAzi 0;
BA_ "GenSigStartValue" SG_ 145 ReSideRdrLeDetn246RdrDetnAzi 900;
BA_ "GenSigDataID" SG_ 145 ReSideRdrLeDetn246RdrDetnChks "0x1152";
BA_ "GenSigFuncType" SG_ 145 ReSideRdrLeDetn246RdrDetnChks 15;
BA_ "GenSigSendType" SG_ 145 ReSideRdrLeDetn246RdrDetnChks 0;
BA_ "GenSigFuncType" SG_ 145 ReSideRdrLeDetn246RdrDetnCntr 16;
BA_ "GenSigSendType" SG_ 145 ReSideRdrLeDetn246RdrDetnCntr 0;
BA_ "GenSigSendType" SG_ 145 ReSideRdrLeDetn246RdrDetnConf 0;
BA_ "GenSigSendType" SG_ 145 ReSideRdrLeDetn246RdrDetnElevn 0;
BA_ "GenSigStartValue" SG_ 145 ReSideRdrLeDetn246RdrDetnElevn 15;
BA_ "GenSigSendType" SG_ 145 ReSideRdrLeDetn246RdrDetnPwr 0;
BA_ "GenSigSendType" SG_ 145 ReSideRdrLeDetn246RdrDetnRng 0;
BA_ "GenSigStartValue" SG_ 145 ReSideRdrLeDetn246RdrDetnRng 10050;
BA_ "GenSigSendType" SG_ 145 ReSideRdrLeDetn246RdrDetnRngV 0;
BA_ "GenSigStartValue" SG_ 145 ReSideRdrLeDetn246RdrDetnRngV 4000;
BA_ "GenSigSendType" SG_ 145 ReSideRdrLeDetn246RdrDetnSameRV 0;
BA_ "GenSigSendType" SG_ 145 ReSideRdrLeDetn246RdrDetnSts 0;
BA_ "GenSigStartValue" SG_ 145 ReSideRdrLeDetn246RdrDetnSts 3;
BA_ "GenSigSendType" SG_ 146 ReSideRdrLeDetn247RdrDetnAmbigState 0;
BA_ "GenSigSendType" SG_ 146 ReSideRdrLeDetn247RdrDetnAssoTrkID 0;
BA_ "GenSigSendType" SG_ 146 ReSideRdrLeDetn247RdrDetnAzi 0;
BA_ "GenSigStartValue" SG_ 146 ReSideRdrLeDetn247RdrDetnAzi 900;
BA_ "GenSigDataID" SG_ 146 ReSideRdrLeDetn247RdrDetnChks "0x1153";
BA_ "GenSigFuncType" SG_ 146 ReSideRdrLeDetn247RdrDetnChks 15;
BA_ "GenSigSendType" SG_ 146 ReSideRdrLeDetn247RdrDetnChks 0;
BA_ "GenSigFuncType" SG_ 146 ReSideRdrLeDetn247RdrDetnCntr 16;
BA_ "GenSigSendType" SG_ 146 ReSideRdrLeDetn247RdrDetnCntr 0;
BA_ "GenSigSendType" SG_ 146 ReSideRdrLeDetn247RdrDetnConf 0;
BA_ "GenSigSendType" SG_ 146 ReSideRdrLeDetn247RdrDetnElevn 0;
BA_ "GenSigStartValue" SG_ 146 ReSideRdrLeDetn247RdrDetnElevn 15;
BA_ "GenSigSendType" SG_ 146 ReSideRdrLeDetn247RdrDetnPwr 0;
BA_ "GenSigSendType" SG_ 146 ReSideRdrLeDetn247RdrDetnRng 0;
BA_ "GenSigStartValue" SG_ 146 ReSideRdrLeDetn247RdrDetnRng 10050;
BA_ "GenSigSendType" SG_ 146 ReSideRdrLeDetn247RdrDetnRngV 0;
BA_ "GenSigStartValue" SG_ 146 ReSideRdrLeDetn247RdrDetnRngV 4000;
BA_ "GenSigSendType" SG_ 146 ReSideRdrLeDetn247RdrDetnSameRV 0;
BA_ "GenSigSendType" SG_ 146 ReSideRdrLeDetn247RdrDetnSts 0;
BA_ "GenSigStartValue" SG_ 146 ReSideRdrLeDetn247RdrDetnSts 3;
BA_ "GenSigSendType" SG_ 146 ReSideRdrLeDetn248RdrDetnAmbigState 0;
BA_ "GenSigSendType" SG_ 146 ReSideRdrLeDetn248RdrDetnAssoTrkID 0;
BA_ "GenSigSendType" SG_ 146 ReSideRdrLeDetn248RdrDetnAzi 0;
BA_ "GenSigStartValue" SG_ 146 ReSideRdrLeDetn248RdrDetnAzi 900;
BA_ "GenSigDataID" SG_ 146 ReSideRdrLeDetn248RdrDetnChks "0x1154";
BA_ "GenSigFuncType" SG_ 146 ReSideRdrLeDetn248RdrDetnChks 15;
BA_ "GenSigSendType" SG_ 146 ReSideRdrLeDetn248RdrDetnChks 0;
BA_ "GenSigFuncType" SG_ 146 ReSideRdrLeDetn248RdrDetnCntr 16;
BA_ "GenSigSendType" SG_ 146 ReSideRdrLeDetn248RdrDetnCntr 0;
BA_ "GenSigSendType" SG_ 146 ReSideRdrLeDetn248RdrDetnConf 0;
BA_ "GenSigSendType" SG_ 146 ReSideRdrLeDetn248RdrDetnElevn 0;
BA_ "GenSigStartValue" SG_ 146 ReSideRdrLeDetn248RdrDetnElevn 15;
BA_ "GenSigSendType" SG_ 146 ReSideRdrLeDetn248RdrDetnPwr 0;
BA_ "GenSigSendType" SG_ 146 ReSideRdrLeDetn248RdrDetnRng 0;
BA_ "GenSigStartValue" SG_ 146 ReSideRdrLeDetn248RdrDetnRng 10050;
BA_ "GenSigSendType" SG_ 146 ReSideRdrLeDetn248RdrDetnRngV 0;
BA_ "GenSigStartValue" SG_ 146 ReSideRdrLeDetn248RdrDetnRngV 4000;
BA_ "GenSigSendType" SG_ 146 ReSideRdrLeDetn248RdrDetnSameRV 0;
BA_ "GenSigSendType" SG_ 146 ReSideRdrLeDetn248RdrDetnSts 0;
BA_ "GenSigStartValue" SG_ 146 ReSideRdrLeDetn248RdrDetnSts 3;
BA_ "GenSigSendType" SG_ 146 ReSideRdrLeDetn249RdrDetnAmbigState 0;
BA_ "GenSigSendType" SG_ 146 ReSideRdrLeDetn249RdrDetnAssoTrkID 0;
BA_ "GenSigSendType" SG_ 146 ReSideRdrLeDetn249RdrDetnAzi 0;
BA_ "GenSigStartValue" SG_ 146 ReSideRdrLeDetn249RdrDetnAzi 900;
BA_ "GenSigDataID" SG_ 146 ReSideRdrLeDetn249RdrDetnChks "0x1155";
BA_ "GenSigFuncType" SG_ 146 ReSideRdrLeDetn249RdrDetnChks 15;
BA_ "GenSigSendType" SG_ 146 ReSideRdrLeDetn249RdrDetnChks 0;
BA_ "GenSigFuncType" SG_ 146 ReSideRdrLeDetn249RdrDetnCntr 16;
BA_ "GenSigSendType" SG_ 146 ReSideRdrLeDetn249RdrDetnCntr 0;
BA_ "GenSigSendType" SG_ 146 ReSideRdrLeDetn249RdrDetnConf 0;
BA_ "GenSigSendType" SG_ 146 ReSideRdrLeDetn249RdrDetnElevn 0;
BA_ "GenSigStartValue" SG_ 146 ReSideRdrLeDetn249RdrDetnElevn 15;
BA_ "GenSigSendType" SG_ 146 ReSideRdrLeDetn249RdrDetnPwr 0;
BA_ "GenSigSendType" SG_ 146 ReSideRdrLeDetn249RdrDetnRng 0;
BA_ "GenSigStartValue" SG_ 146 ReSideRdrLeDetn249RdrDetnRng 10050;
BA_ "GenSigSendType" SG_ 146 ReSideRdrLeDetn249RdrDetnRngV 0;
BA_ "GenSigStartValue" SG_ 146 ReSideRdrLeDetn249RdrDetnRngV 4000;
BA_ "GenSigSendType" SG_ 146 ReSideRdrLeDetn249RdrDetnSameRV 0;
BA_ "GenSigSendType" SG_ 146 ReSideRdrLeDetn249RdrDetnSts 0;
BA_ "GenSigStartValue" SG_ 146 ReSideRdrLeDetn249RdrDetnSts 3;
BA_ "GenSigSendType" SG_ 146 ReSideRdrLeDetn250RdrDetnAmbigState 0;
BA_ "GenSigSendType" SG_ 146 ReSideRdrLeDetn250RdrDetnAssoTrkID 0;
BA_ "GenSigSendType" SG_ 146 ReSideRdrLeDetn250RdrDetnAzi 0;
BA_ "GenSigStartValue" SG_ 146 ReSideRdrLeDetn250RdrDetnAzi 900;
BA_ "GenSigDataID" SG_ 146 ReSideRdrLeDetn250RdrDetnChks "0x1156";
BA_ "GenSigFuncType" SG_ 146 ReSideRdrLeDetn250RdrDetnChks 15;
BA_ "GenSigSendType" SG_ 146 ReSideRdrLeDetn250RdrDetnChks 0;
BA_ "GenSigFuncType" SG_ 146 ReSideRdrLeDetn250RdrDetnCntr 16;
BA_ "GenSigSendType" SG_ 146 ReSideRdrLeDetn250RdrDetnCntr 0;
BA_ "GenSigSendType" SG_ 146 ReSideRdrLeDetn250RdrDetnConf 0;
BA_ "GenSigSendType" SG_ 146 ReSideRdrLeDetn250RdrDetnElevn 0;
BA_ "GenSigStartValue" SG_ 146 ReSideRdrLeDetn250RdrDetnElevn 15;
BA_ "GenSigSendType" SG_ 146 ReSideRdrLeDetn250RdrDetnPwr 0;
BA_ "GenSigSendType" SG_ 146 ReSideRdrLeDetn250RdrDetnRng 0;
BA_ "GenSigStartValue" SG_ 146 ReSideRdrLeDetn250RdrDetnRng 10050;
BA_ "GenSigSendType" SG_ 146 ReSideRdrLeDetn250RdrDetnRngV 0;
BA_ "GenSigStartValue" SG_ 146 ReSideRdrLeDetn250RdrDetnRngV 4000;
BA_ "GenSigSendType" SG_ 146 ReSideRdrLeDetn250RdrDetnSameRV 0;
BA_ "GenSigSendType" SG_ 146 ReSideRdrLeDetn250RdrDetnSts 0;
BA_ "GenSigStartValue" SG_ 146 ReSideRdrLeDetn250RdrDetnSts 3;
BA_ "GenSigSendType" SG_ 146 ReSideRdrLeDetn251RdrDetnAmbigState 0;
BA_ "GenSigSendType" SG_ 146 ReSideRdrLeDetn251RdrDetnAssoTrkID 0;
BA_ "GenSigSendType" SG_ 146 ReSideRdrLeDetn251RdrDetnAzi 0;
BA_ "GenSigStartValue" SG_ 146 ReSideRdrLeDetn251RdrDetnAzi 900;
BA_ "GenSigDataID" SG_ 146 ReSideRdrLeDetn251RdrDetnChks "0x1157";
BA_ "GenSigFuncType" SG_ 146 ReSideRdrLeDetn251RdrDetnChks 15;
BA_ "GenSigSendType" SG_ 146 ReSideRdrLeDetn251RdrDetnChks 0;
BA_ "GenSigFuncType" SG_ 146 ReSideRdrLeDetn251RdrDetnCntr 16;
BA_ "GenSigSendType" SG_ 146 ReSideRdrLeDetn251RdrDetnCntr 0;
BA_ "GenSigSendType" SG_ 146 ReSideRdrLeDetn251RdrDetnConf 0;
BA_ "GenSigSendType" SG_ 146 ReSideRdrLeDetn251RdrDetnElevn 0;
BA_ "GenSigStartValue" SG_ 146 ReSideRdrLeDetn251RdrDetnElevn 15;
BA_ "GenSigSendType" SG_ 146 ReSideRdrLeDetn251RdrDetnPwr 0;
BA_ "GenSigSendType" SG_ 146 ReSideRdrLeDetn251RdrDetnRng 0;
BA_ "GenSigStartValue" SG_ 146 ReSideRdrLeDetn251RdrDetnRng 10050;
BA_ "GenSigSendType" SG_ 146 ReSideRdrLeDetn251RdrDetnRngV 0;
BA_ "GenSigStartValue" SG_ 146 ReSideRdrLeDetn251RdrDetnRngV 4000;
BA_ "GenSigSendType" SG_ 146 ReSideRdrLeDetn251RdrDetnSameRV 0;
BA_ "GenSigSendType" SG_ 146 ReSideRdrLeDetn251RdrDetnSts 0;
BA_ "GenSigStartValue" SG_ 146 ReSideRdrLeDetn251RdrDetnSts 3;
BA_ "GenSigSendType" SG_ 146 ReSideRdrLeDetn252RdrDetnAmbigState 0;
BA_ "GenSigSendType" SG_ 146 ReSideRdrLeDetn252RdrDetnAssoTrkID 0;
BA_ "GenSigSendType" SG_ 146 ReSideRdrLeDetn252RdrDetnAzi 0;
BA_ "GenSigStartValue" SG_ 146 ReSideRdrLeDetn252RdrDetnAzi 900;
BA_ "GenSigDataID" SG_ 146 ReSideRdrLeDetn252RdrDetnChks "0x1158";
BA_ "GenSigFuncType" SG_ 146 ReSideRdrLeDetn252RdrDetnChks 15;
BA_ "GenSigSendType" SG_ 146 ReSideRdrLeDetn252RdrDetnChks 0;
BA_ "GenSigFuncType" SG_ 146 ReSideRdrLeDetn252RdrDetnCntr 16;
BA_ "GenSigSendType" SG_ 146 ReSideRdrLeDetn252RdrDetnCntr 0;
BA_ "GenSigSendType" SG_ 146 ReSideRdrLeDetn252RdrDetnConf 0;
BA_ "GenSigSendType" SG_ 146 ReSideRdrLeDetn252RdrDetnElevn 0;
BA_ "GenSigStartValue" SG_ 146 ReSideRdrLeDetn252RdrDetnElevn 15;
BA_ "GenSigSendType" SG_ 146 ReSideRdrLeDetn252RdrDetnPwr 0;
BA_ "GenSigSendType" SG_ 146 ReSideRdrLeDetn252RdrDetnRng 0;
BA_ "GenSigStartValue" SG_ 146 ReSideRdrLeDetn252RdrDetnRng 10050;
BA_ "GenSigSendType" SG_ 146 ReSideRdrLeDetn252RdrDetnRngV 0;
BA_ "GenSigStartValue" SG_ 146 ReSideRdrLeDetn252RdrDetnRngV 4000;
BA_ "GenSigSendType" SG_ 146 ReSideRdrLeDetn252RdrDetnSameRV 0;
BA_ "GenSigSendType" SG_ 146 ReSideRdrLeDetn252RdrDetnSts 0;
BA_ "GenSigStartValue" SG_ 146 ReSideRdrLeDetn252RdrDetnSts 3;
BA_ "GenSigSendType" SG_ 147 ReSideRdrLeDetn253RdrDetnAmbigState 0;
BA_ "GenSigSendType" SG_ 147 ReSideRdrLeDetn253RdrDetnAssoTrkID 0;
BA_ "GenSigSendType" SG_ 147 ReSideRdrLeDetn253RdrDetnAzi 0;
BA_ "GenSigStartValue" SG_ 147 ReSideRdrLeDetn253RdrDetnAzi 900;
BA_ "GenSigDataID" SG_ 147 ReSideRdrLeDetn253RdrDetnChks "0x1159";
BA_ "GenSigFuncType" SG_ 147 ReSideRdrLeDetn253RdrDetnChks 15;
BA_ "GenSigSendType" SG_ 147 ReSideRdrLeDetn253RdrDetnChks 0;
BA_ "GenSigFuncType" SG_ 147 ReSideRdrLeDetn253RdrDetnCntr 16;
BA_ "GenSigSendType" SG_ 147 ReSideRdrLeDetn253RdrDetnCntr 0;
BA_ "GenSigSendType" SG_ 147 ReSideRdrLeDetn253RdrDetnConf 0;
BA_ "GenSigSendType" SG_ 147 ReSideRdrLeDetn253RdrDetnElevn 0;
BA_ "GenSigStartValue" SG_ 147 ReSideRdrLeDetn253RdrDetnElevn 15;
BA_ "GenSigSendType" SG_ 147 ReSideRdrLeDetn253RdrDetnPwr 0;
BA_ "GenSigSendType" SG_ 147 ReSideRdrLeDetn253RdrDetnRng 0;
BA_ "GenSigStartValue" SG_ 147 ReSideRdrLeDetn253RdrDetnRng 10050;
BA_ "GenSigSendType" SG_ 147 ReSideRdrLeDetn253RdrDetnRngV 0;
BA_ "GenSigStartValue" SG_ 147 ReSideRdrLeDetn253RdrDetnRngV 4000;
BA_ "GenSigSendType" SG_ 147 ReSideRdrLeDetn253RdrDetnSameRV 0;
BA_ "GenSigSendType" SG_ 147 ReSideRdrLeDetn253RdrDetnSts 0;
BA_ "GenSigStartValue" SG_ 147 ReSideRdrLeDetn253RdrDetnSts 3;
BA_ "GenSigSendType" SG_ 147 ReSideRdrLeDetn254RdrDetnAmbigState 0;
BA_ "GenSigSendType" SG_ 147 ReSideRdrLeDetn254RdrDetnAssoTrkID 0;
BA_ "GenSigSendType" SG_ 147 ReSideRdrLeDetn254RdrDetnAzi 0;
BA_ "GenSigStartValue" SG_ 147 ReSideRdrLeDetn254RdrDetnAzi 900;
BA_ "GenSigDataID" SG_ 147 ReSideRdrLeDetn254RdrDetnChks "0x115A";
BA_ "GenSigFuncType" SG_ 147 ReSideRdrLeDetn254RdrDetnChks 15;
BA_ "GenSigSendType" SG_ 147 ReSideRdrLeDetn254RdrDetnChks 0;
BA_ "GenSigFuncType" SG_ 147 ReSideRdrLeDetn254RdrDetnCntr 16;
BA_ "GenSigSendType" SG_ 147 ReSideRdrLeDetn254RdrDetnCntr 0;
BA_ "GenSigSendType" SG_ 147 ReSideRdrLeDetn254RdrDetnConf 0;
BA_ "GenSigSendType" SG_ 147 ReSideRdrLeDetn254RdrDetnElevn 0;
BA_ "GenSigStartValue" SG_ 147 ReSideRdrLeDetn254RdrDetnElevn 15;
BA_ "GenSigSendType" SG_ 147 ReSideRdrLeDetn254RdrDetnPwr 0;
BA_ "GenSigSendType" SG_ 147 ReSideRdrLeDetn254RdrDetnRng 0;
BA_ "GenSigStartValue" SG_ 147 ReSideRdrLeDetn254RdrDetnRng 10050;
BA_ "GenSigSendType" SG_ 147 ReSideRdrLeDetn254RdrDetnRngV 0;
BA_ "GenSigStartValue" SG_ 147 ReSideRdrLeDetn254RdrDetnRngV 4000;
BA_ "GenSigSendType" SG_ 147 ReSideRdrLeDetn254RdrDetnSameRV 0;
BA_ "GenSigSendType" SG_ 147 ReSideRdrLeDetn254RdrDetnSts 0;
BA_ "GenSigStartValue" SG_ 147 ReSideRdrLeDetn254RdrDetnSts 3;
BA_ "GenSigSendType" SG_ 147 ReSideRdrLeDetn255RdrDetnAmbigState 0;
BA_ "GenSigSendType" SG_ 147 ReSideRdrLeDetn255RdrDetnAssoTrkID 0;
BA_ "GenSigSendType" SG_ 147 ReSideRdrLeDetn255RdrDetnAzi 0;
BA_ "GenSigStartValue" SG_ 147 ReSideRdrLeDetn255RdrDetnAzi 900;
BA_ "GenSigDataID" SG_ 147 ReSideRdrLeDetn255RdrDetnChks "0x115B";
BA_ "GenSigFuncType" SG_ 147 ReSideRdrLeDetn255RdrDetnChks 15;
BA_ "GenSigSendType" SG_ 147 ReSideRdrLeDetn255RdrDetnChks 0;
BA_ "GenSigFuncType" SG_ 147 ReSideRdrLeDetn255RdrDetnCntr 16;
BA_ "GenSigSendType" SG_ 147 ReSideRdrLeDetn255RdrDetnCntr 0;
BA_ "GenSigSendType" SG_ 147 ReSideRdrLeDetn255RdrDetnConf 0;
BA_ "GenSigSendType" SG_ 147 ReSideRdrLeDetn255RdrDetnElevn 0;
BA_ "GenSigStartValue" SG_ 147 ReSideRdrLeDetn255RdrDetnElevn 15;
BA_ "GenSigSendType" SG_ 147 ReSideRdrLeDetn255RdrDetnPwr 0;
BA_ "GenSigSendType" SG_ 147 ReSideRdrLeDetn255RdrDetnRng 0;
BA_ "GenSigStartValue" SG_ 147 ReSideRdrLeDetn255RdrDetnRng 10050;
BA_ "GenSigSendType" SG_ 147 ReSideRdrLeDetn255RdrDetnRngV 0;
BA_ "GenSigStartValue" SG_ 147 ReSideRdrLeDetn255RdrDetnRngV 4000;
BA_ "GenSigSendType" SG_ 147 ReSideRdrLeDetn255RdrDetnSameRV 0;
BA_ "GenSigSendType" SG_ 147 ReSideRdrLeDetn255RdrDetnSts 0;
BA_ "GenSigStartValue" SG_ 147 ReSideRdrLeDetn255RdrDetnSts 3;
BA_ "GenSigSendType" SG_ 147 ReSideRdrLeDetn256RdrDetnAmbigState 0;
BA_ "GenSigSendType" SG_ 147 ReSideRdrLeDetn256RdrDetnAssoTrkID 0;
BA_ "GenSigSendType" SG_ 147 ReSideRdrLeDetn256RdrDetnAzi 0;
BA_ "GenSigStartValue" SG_ 147 ReSideRdrLeDetn256RdrDetnAzi 900;
BA_ "GenSigDataID" SG_ 147 ReSideRdrLeDetn256RdrDetnChks "0x115C";
BA_ "GenSigFuncType" SG_ 147 ReSideRdrLeDetn256RdrDetnChks 15;
BA_ "GenSigSendType" SG_ 147 ReSideRdrLeDetn256RdrDetnChks 0;
BA_ "GenSigFuncType" SG_ 147 ReSideRdrLeDetn256RdrDetnCntr 16;
BA_ "GenSigSendType" SG_ 147 ReSideRdrLeDetn256RdrDetnCntr 0;
BA_ "GenSigSendType" SG_ 147 ReSideRdrLeDetn256RdrDetnConf 0;
BA_ "GenSigSendType" SG_ 147 ReSideRdrLeDetn256RdrDetnElevn 0;
BA_ "GenSigStartValue" SG_ 147 ReSideRdrLeDetn256RdrDetnElevn 15;
BA_ "GenSigSendType" SG_ 147 ReSideRdrLeDetn256RdrDetnPwr 0;
BA_ "GenSigSendType" SG_ 147 ReSideRdrLeDetn256RdrDetnRng 0;
BA_ "GenSigStartValue" SG_ 147 ReSideRdrLeDetn256RdrDetnRng 10050;
BA_ "GenSigSendType" SG_ 147 ReSideRdrLeDetn256RdrDetnRngV 0;
BA_ "GenSigStartValue" SG_ 147 ReSideRdrLeDetn256RdrDetnRngV 4000;
BA_ "GenSigSendType" SG_ 147 ReSideRdrLeDetn256RdrDetnSameRV 0;
BA_ "GenSigSendType" SG_ 147 ReSideRdrLeDetn256RdrDetnSts 0;
BA_ "GenSigStartValue" SG_ 147 ReSideRdrLeDetn256RdrDetnSts 3;
BA_ "GenSigSendType" SG_ 149 SODL20PartNumPartNumType 0;
BA_ "GenSigSendType" SG_ 149 SODL20PartNumPartNumValue 0;
VAL_ 137 ReSideRdrLeDetn229RdrDetnAmbigState 0 "YesNo1_Yes" 1 "YesNo1_No";
VAL_ 137 ReSideRdrLeDetn229RdrDetnSameRV 0 "Mode6_0" 1 "Mode6_1" 2 "Mode6_2";
VAL_ 137 ReSideRdrLeDetn229RdrDetnSts 0 "RdrDetnSts_Ukwn" 1 "RdrDetnSts_Movg" 2 "RdrDetnSts_Staty" 3 "RdrDetnSts_Invalid";
VAL_ 137 ReSideRdrLeDetn230RdrDetnAmbigState 0 "YesNo1_Yes" 1 "YesNo1_No";
VAL_ 137 ReSideRdrLeDetn230RdrDetnSameRV 0 "Mode6_0" 1 "Mode6_1" 2 "Mode6_2";
VAL_ 137 ReSideRdrLeDetn230RdrDetnSts 0 "RdrDetnSts_Ukwn" 1 "RdrDetnSts_Movg" 2 "RdrDetnSts_Staty" 3 "RdrDetnSts_Invalid";
VAL_ 137 ReSideRdrLeDetn231RdrDetnAmbigState 0 "YesNo1_Yes" 1 "YesNo1_No";
VAL_ 137 ReSideRdrLeDetn231RdrDetnSameRV 0 "Mode6_0" 1 "Mode6_1" 2 "Mode6_2";
VAL_ 137 ReSideRdrLeDetn231RdrDetnSts 0 "RdrDetnSts_Ukwn" 1 "RdrDetnSts_Movg" 2 "RdrDetnSts_Staty" 3 "RdrDetnSts_Invalid";
VAL_ 137 ReSideRdrLeDetn232RdrDetnAmbigState 0 "YesNo1_Yes" 1 "YesNo1_No";
VAL_ 137 ReSideRdrLeDetn232RdrDetnSameRV 0 "Mode6_0" 1 "Mode6_1" 2 "Mode6_2";
VAL_ 137 ReSideRdrLeDetn232RdrDetnSts 0 "RdrDetnSts_Ukwn" 1 "RdrDetnSts_Movg" 2 "RdrDetnSts_Staty" 3 "RdrDetnSts_Invalid";
VAL_ 137 ReSideRdrLeDetn233RdrDetnAmbigState 0 "YesNo1_Yes" 1 "YesNo1_No";
VAL_ 137 ReSideRdrLeDetn233RdrDetnSameRV 0 "Mode6_0" 1 "Mode6_1" 2 "Mode6_2";
VAL_ 137 ReSideRdrLeDetn233RdrDetnSts 0 "RdrDetnSts_Ukwn" 1 "RdrDetnSts_Movg" 2 "RdrDetnSts_Staty" 3 "RdrDetnSts_Invalid";
VAL_ 137 ReSideRdrLeDetn234RdrDetnAmbigState 0 "YesNo1_Yes" 1 "YesNo1_No";
VAL_ 137 ReSideRdrLeDetn234RdrDetnSameRV 0 "Mode6_0" 1 "Mode6_1" 2 "Mode6_2";
VAL_ 137 ReSideRdrLeDetn234RdrDetnSts 0 "RdrDetnSts_Ukwn" 1 "RdrDetnSts_Movg" 2 "RdrDetnSts_Staty" 3 "RdrDetnSts_Invalid";
VAL_ 144 ReSideRdrLeDetn235RdrDetnAmbigState 0 "YesNo1_Yes" 1 "YesNo1_No";
VAL_ 144 ReSideRdrLeDetn235RdrDetnSameRV 0 "Mode6_0" 1 "Mode6_1" 2 "Mode6_2";
VAL_ 144 ReSideRdrLeDetn235RdrDetnSts 0 "RdrDetnSts_Ukwn" 1 "RdrDetnSts_Movg" 2 "RdrDetnSts_Staty" 3 "RdrDetnSts_Invalid";
VAL_ 144 ReSideRdrLeDetn236RdrDetnAmbigState 0 "YesNo1_Yes" 1 "YesNo1_No";
VAL_ 144 ReSideRdrLeDetn236RdrDetnSameRV 0 "Mode6_0" 1 "Mode6_1" 2 "Mode6_2";
VAL_ 144 ReSideRdrLeDetn236RdrDetnSts 0 "RdrDetnSts_Ukwn" 1 "RdrDetnSts_Movg" 2 "RdrDetnSts_Staty" 3 "RdrDetnSts_Invalid";
VAL_ 144 ReSideRdrLeDetn237RdrDetnAmbigState 0 "YesNo1_Yes" 1 "YesNo1_No";
VAL_ 144 ReSideRdrLeDetn237RdrDetnSameRV 0 "Mode6_0" 1 "Mode6_1" 2 "Mode6_2";
VAL_ 144 ReSideRdrLeDetn237RdrDetnSts 0 "RdrDetnSts_Ukwn" 1 "RdrDetnSts_Movg" 2 "RdrDetnSts_Staty" 3 "RdrDetnSts_Invalid";
VAL_ 144 ReSideRdrLeDetn238RdrDetnAmbigState 0 "YesNo1_Yes" 1 "YesNo1_No";
VAL_ 144 ReSideRdrLeDetn238RdrDetnSameRV 0 "Mode6_0" 1 "Mode6_1" 2 "Mode6_2";
VAL_ 144 ReSideRdrLeDetn238RdrDetnSts 0 "RdrDetnSts_Ukwn" 1 "RdrDetnSts_Movg" 2 "RdrDetnSts_Staty" 3 "RdrDetnSts_Invalid";
VAL_ 144 ReSideRdrLeDetn239RdrDetnAmbigState 0 "YesNo1_Yes" 1 "YesNo1_No";
VAL_ 144 ReSideRdrLeDetn239RdrDetnSameRV 0 "Mode6_0" 1 "Mode6_1" 2 "Mode6_2";
VAL_ 144 ReSideRdrLeDetn239RdrDetnSts 0 "RdrDetnSts_Ukwn" 1 "RdrDetnSts_Movg" 2 "RdrDetnSts_Staty" 3 "RdrDetnSts_Invalid";
VAL_ 144 ReSideRdrLeDetn240RdrDetnAmbigState 0 "YesNo1_Yes" 1 "YesNo1_No";
VAL_ 144 ReSideRdrLeDetn240RdrDetnSameRV 0 "Mode6_0" 1 "Mode6_1" 2 "Mode6_2";
VAL_ 144 ReSideRdrLeDetn240RdrDetnSts 0 "RdrDetnSts_Ukwn" 1 "RdrDetnSts_Movg" 2 "RdrDetnSts_Staty" 3 "RdrDetnSts_Invalid";
VAL_ 145 ReSideRdrLeDetn241RdrDetnAmbigState 0 "YesNo1_Yes" 1 "YesNo1_No";
VAL_ 145 ReSideRdrLeDetn241RdrDetnSameRV 0 "Mode6_0" 1 "Mode6_1" 2 "Mode6_2";
VAL_ 145 ReSideRdrLeDetn241RdrDetnSts 0 "RdrDetnSts_Ukwn" 1 "RdrDetnSts_Movg" 2 "RdrDetnSts_Staty" 3 "RdrDetnSts_Invalid";
VAL_ 145 ReSideRdrLeDetn242RdrDetnAmbigState 0 "YesNo1_Yes" 1 "YesNo1_No";
VAL_ 145 ReSideRdrLeDetn242RdrDetnSameRV 0 "Mode6_0" 1 "Mode6_1" 2 "Mode6_2";
VAL_ 145 ReSideRdrLeDetn242RdrDetnSts 0 "RdrDetnSts_Ukwn" 1 "RdrDetnSts_Movg" 2 "RdrDetnSts_Staty" 3 "RdrDetnSts_Invalid";
VAL_ 145 ReSideRdrLeDetn243RdrDetnAmbigState 0 "YesNo1_Yes" 1 "YesNo1_No";
VAL_ 145 ReSideRdrLeDetn243RdrDetnSameRV 0 "Mode6_0" 1 "Mode6_1" 2 "Mode6_2";
VAL_ 145 ReSideRdrLeDetn243RdrDetnSts 0 "RdrDetnSts_Ukwn" 1 "RdrDetnSts_Movg" 2 "RdrDetnSts_Staty" 3 "RdrDetnSts_Invalid";
VAL_ 145 ReSideRdrLeDetn244RdrDetnAmbigState 0 "YesNo1_Yes" 1 "YesNo1_No";
VAL_ 145 ReSideRdrLeDetn244RdrDetnSameRV 0 "Mode6_0" 1 "Mode6_1" 2 "Mode6_2";
VAL_ 145 ReSideRdrLeDetn244RdrDetnSts 0 "RdrDetnSts_Ukwn" 1 "RdrDetnSts_Movg" 2 "RdrDetnSts_Staty" 3 "RdrDetnSts_Invalid";
VAL_ 145 ReSideRdrLeDetn245RdrDetnAmbigState 0 "YesNo1_Yes" 1 "YesNo1_No";
VAL_ 145 ReSideRdrLeDetn245RdrDetnSameRV 0 "Mode6_0" 1 "Mode6_1" 2 "Mode6_2";
VAL_ 145 ReSideRdrLeDetn245RdrDetnSts 0 "RdrDetnSts_Ukwn" 1 "RdrDetnSts_Movg" 2 "RdrDetnSts_Staty" 3 "RdrDetnSts_Invalid";
VAL_ 145 ReSideRdrLeDetn246RdrDetnAmbigState 0 "YesNo1_Yes" 1 "YesNo1_No";
VAL_ 145 ReSideRdrLeDetn246RdrDetnSameRV 0 "Mode6_0" 1 "Mode6_1" 2 "Mode6_2";
VAL_ 145 ReSideRdrLeDetn246RdrDetnSts 0 "RdrDetnSts_Ukwn" 1 "RdrDetnSts_Movg" 2 "RdrDetnSts_Staty" 3 "RdrDetnSts_Invalid";
VAL_ 146 ReSideRdrLeDetn247RdrDetnAmbigState 0 "YesNo1_Yes" 1 "YesNo1_No";
VAL_ 146 ReSideRdrLeDetn247RdrDetnSameRV 0 "Mode6_0" 1 "Mode6_1" 2 "Mode6_2";
VAL_ 146 ReSideRdrLeDetn247RdrDetnSts 0 "RdrDetnSts_Ukwn" 1 "RdrDetnSts_Movg" 2 "RdrDetnSts_Staty" 3 "RdrDetnSts_Invalid";
VAL_ 146 ReSideRdrLeDetn248RdrDetnAmbigState 0 "YesNo1_Yes" 1 "YesNo1_No";
VAL_ 146 ReSideRdrLeDetn248RdrDetnSameRV 0 "Mode6_0" 1 "Mode6_1" 2 "Mode6_2";
VAL_ 146 ReSideRdrLeDetn248RdrDetnSts 0 "RdrDetnSts_Ukwn" 1 "RdrDetnSts_Movg" 2 "RdrDetnSts_Staty" 3 "RdrDetnSts_Invalid";
VAL_ 146 ReSideRdrLeDetn249RdrDetnAmbigState 0 "YesNo1_Yes" 1 "YesNo1_No";
VAL_ 146 ReSideRdrLeDetn249RdrDetnSameRV 0 "Mode6_0" 1 "Mode6_1" 2 "Mode6_2";
VAL_ 146 ReSideRdrLeDetn249RdrDetnSts 0 "RdrDetnSts_Ukwn" 1 "RdrDetnSts_Movg" 2 "RdrDetnSts_Staty" 3 "RdrDetnSts_Invalid";
VAL_ 146 ReSideRdrLeDetn250RdrDetnAmbigState 0 "YesNo1_Yes" 1 "YesNo1_No";
VAL_ 146 ReSideRdrLeDetn250RdrDetnSameRV 0 "Mode6_0" 1 "Mode6_1" 2 "Mode6_2";
VAL_ 146 ReSideRdrLeDetn250RdrDetnSts 0 "RdrDetnSts_Ukwn" 1 "RdrDetnSts_Movg" 2 "RdrDetnSts_Staty" 3 "RdrDetnSts_Invalid";
VAL_ 146 ReSideRdrLeDetn251RdrDetnAmbigState 0 "YesNo1_Yes" 1 "YesNo1_No";
VAL_ 146 ReSideRdrLeDetn251RdrDetnSameRV 0 "Mode6_0" 1 "Mode6_1" 2 "Mode6_2";
VAL_ 146 ReSideRdrLeDetn251RdrDetnSts 0 "RdrDetnSts_Ukwn" 1 "RdrDetnSts_Movg" 2 "RdrDetnSts_Staty" 3 "RdrDetnSts_Invalid";
VAL_ 146 ReSideRdrLeDetn252RdrDetnAmbigState 0 "YesNo1_Yes" 1 "YesNo1_No";
VAL_ 146 ReSideRdrLeDetn252RdrDetnSameRV 0 "Mode6_0" 1 "Mode6_1" 2 "Mode6_2";
VAL_ 146 ReSideRdrLeDetn252RdrDetnSts 0 "RdrDetnSts_Ukwn" 1 "RdrDetnSts_Movg" 2 "RdrDetnSts_Staty" 3 "RdrDetnSts_Invalid";
VAL_ 147 ReSideRdrLeDetn253RdrDetnAmbigState 0 "YesNo1_Yes" 1 "YesNo1_No";
VAL_ 147 ReSideRdrLeDetn253RdrDetnSameRV 0 "Mode6_0" 1 "Mode6_1" 2 "Mode6_2";
VAL_ 147 ReSideRdrLeDetn253RdrDetnSts 0 "RdrDetnSts_Ukwn" 1 "RdrDetnSts_Movg" 2 "RdrDetnSts_Staty" 3 "RdrDetnSts_Invalid";
VAL_ 147 ReSideRdrLeDetn254RdrDetnAmbigState 0 "YesNo1_Yes" 1 "YesNo1_No";
VAL_ 147 ReSideRdrLeDetn254RdrDetnSameRV 0 "Mode6_0" 1 "Mode6_1" 2 "Mode6_2";
VAL_ 147 ReSideRdrLeDetn254RdrDetnSts 0 "RdrDetnSts_Ukwn" 1 "RdrDetnSts_Movg" 2 "RdrDetnSts_Staty" 3 "RdrDetnSts_Invalid";
VAL_ 147 ReSideRdrLeDetn255RdrDetnAmbigState 0 "YesNo1_Yes" 1 "YesNo1_No";
VAL_ 147 ReSideRdrLeDetn255RdrDetnSameRV 0 "Mode6_0" 1 "Mode6_1" 2 "Mode6_2";
VAL_ 147 ReSideRdrLeDetn255RdrDetnSts 0 "RdrDetnSts_Ukwn" 1 "RdrDetnSts_Movg" 2 "RdrDetnSts_Staty" 3 "RdrDetnSts_Invalid";
VAL_ 147 ReSideRdrLeDetn256RdrDetnAmbigState 0 "YesNo1_Yes" 1 "YesNo1_No";
VAL_ 147 ReSideRdrLeDetn256RdrDetnSameRV 0 "Mode6_0" 1 "Mode6_1" 2 "Mode6_2";
VAL_ 147 ReSideRdrLeDetn256RdrDetnSts 0 "RdrDetnSts_Ukwn" 1 "RdrDetnSts_Movg" 2 "RdrDetnSts_Staty" 3 "RdrDetnSts_Invalid";
VAL_ 148 ReSideRdrLeDetTiSyncRdrStsDetTistampStsGlbTiBas 0 "YesNo2_No" 1 "YesNo2_Yes";
VAL_ 148 ReSideRdrLeDetTiSyncRdrStsDetTistampStsSyncToGateway 0 "YesNo2_No" 1 "YesNo2_Yes";
VAL_ 148 ReSideRdrLeDetTiSyncRdrStsDetTistampStsTiLeap 0 "YesNo2_No" 1 "YesNo2_Yes";
VAL_ 148 ReSideRdrLeDetTiSyncRdrStsDetTistampStsTiOut 0 "YesNo2_No" 1 "YesNo2_Yes";
SIG_GROUP_ 137 ReSideRdrLeDetn229 1 : ReSideRdrLeDetn229RdrDetnAmbigState ReSideRdrLeDetn229RdrDetnAssoTrkID ReSideRdrLeDetn229RdrDetnAzi ReSideRdrLeDetn229RdrDetnChks ReSideRdrLeDetn229RdrDetnCntr ReSideRdrLeDetn229RdrDetnConf ReSideRdrLeDetn229RdrDetnElevn ReSideRdrLeDetn229RdrDetnPwr ReSideRdrLeDetn229RdrDetnRng ReSideRdrLeDetn229RdrDetnRngV ReSideRdrLeDetn229RdrDetnSameRV ReSideRdrLeDetn229RdrDetnSts;
SIG_GROUP_ 137 ReSideRdrLeDetn230 1 : ReSideRdrLeDetn230RdrDetnAmbigState ReSideRdrLeDetn230RdrDetnAssoTrkID ReSideRdrLeDetn230RdrDetnAzi ReSideRdrLeDetn230RdrDetnChks ReSideRdrLeDetn230RdrDetnCntr ReSideRdrLeDetn230RdrDetnConf ReSideRdrLeDetn230RdrDetnElevn ReSideRdrLeDetn230RdrDetnPwr ReSideRdrLeDetn230RdrDetnRng ReSideRdrLeDetn230RdrDetnRngV ReSideRdrLeDetn230RdrDetnSameRV ReSideRdrLeDetn230RdrDetnSts;
SIG_GROUP_ 137 ReSideRdrLeDetn231 1 : ReSideRdrLeDetn231RdrDetnAmbigState ReSideRdrLeDetn231RdrDetnAssoTrkID ReSideRdrLeDetn231RdrDetnAzi ReSideRdrLeDetn231RdrDetnChks ReSideRdrLeDetn231RdrDetnCntr ReSideRdrLeDetn231RdrDetnConf ReSideRdrLeDetn231RdrDetnElevn ReSideRdrLeDetn231RdrDetnPwr ReSideRdrLeDetn231RdrDetnRng ReSideRdrLeDetn231RdrDetnRngV ReSideRdrLeDetn231RdrDetnSameRV ReSideRdrLeDetn231RdrDetnSts;
SIG_GROUP_ 137 ReSideRdrLeDetn232 1 : ReSideRdrLeDetn232RdrDetnAmbigState ReSideRdrLeDetn232RdrDetnAssoTrkID ReSideRdrLeDetn232RdrDetnAzi ReSideRdrLeDetn232RdrDetnChks ReSideRdrLeDetn232RdrDetnCntr ReSideRdrLeDetn232RdrDetnConf ReSideRdrLeDetn232RdrDetnElevn ReSideRdrLeDetn232RdrDetnPwr ReSideRdrLeDetn232RdrDetnRng ReSideRdrLeDetn232RdrDetnRngV ReSideRdrLeDetn232RdrDetnSameRV ReSideRdrLeDetn232RdrDetnSts;
SIG_GROUP_ 137 ReSideRdrLeDetn233 1 : ReSideRdrLeDetn233RdrDetnAmbigState ReSideRdrLeDetn233RdrDetnAssoTrkID ReSideRdrLeDetn233RdrDetnAzi ReSideRdrLeDetn233RdrDetnChks ReSideRdrLeDetn233RdrDetnCntr ReSideRdrLeDetn233RdrDetnConf ReSideRdrLeDetn233RdrDetnElevn ReSideRdrLeDetn233RdrDetnPwr ReSideRdrLeDetn233RdrDetnRng ReSideRdrLeDetn233RdrDetnRngV ReSideRdrLeDetn233RdrDetnSameRV ReSideRdrLeDetn233RdrDetnSts;
SIG_GROUP_ 137 ReSideRdrLeDetn234 1 : ReSideRdrLeDetn234RdrDetnAmbigState ReSideRdrLeDetn234RdrDetnAssoTrkID ReSideRdrLeDetn234RdrDetnAzi ReSideRdrLeDetn234RdrDetnChks ReSideRdrLeDetn234RdrDetnCntr ReSideRdrLeDetn234RdrDetnConf ReSideRdrLeDetn234RdrDetnElevn ReSideRdrLeDetn234RdrDetnPwr ReSideRdrLeDetn234RdrDetnRng ReSideRdrLeDetn234RdrDetnRngV ReSideRdrLeDetn234RdrDetnSameRV ReSideRdrLeDetn234RdrDetnSts;
SIG_GROUP_ 144 ReSideRdrLeDetn235 1 : ReSideRdrLeDetn235RdrDetnAmbigState ReSideRdrLeDetn235RdrDetnAssoTrkID ReSideRdrLeDetn235RdrDetnAzi ReSideRdrLeDetn235RdrDetnChks ReSideRdrLeDetn235RdrDetnCntr ReSideRdrLeDetn235RdrDetnConf ReSideRdrLeDetn235RdrDetnElevn ReSideRdrLeDetn235RdrDetnPwr ReSideRdrLeDetn235RdrDetnRng ReSideRdrLeDetn235RdrDetnRngV ReSideRdrLeDetn235RdrDetnSameRV ReSideRdrLeDetn235RdrDetnSts;
SIG_GROUP_ 144 ReSideRdrLeDetn236 1 : ReSideRdrLeDetn236RdrDetnAmbigState ReSideRdrLeDetn236RdrDetnAssoTrkID ReSideRdrLeDetn236RdrDetnAzi ReSideRdrLeDetn236RdrDetnChks ReSideRdrLeDetn236RdrDetnCntr ReSideRdrLeDetn236RdrDetnConf ReSideRdrLeDetn236RdrDetnElevn ReSideRdrLeDetn236RdrDetnPwr ReSideRdrLeDetn236RdrDetnRng ReSideRdrLeDetn236RdrDetnRngV ReSideRdrLeDetn236RdrDetnSameRV ReSideRdrLeDetn236RdrDetnSts;
SIG_GROUP_ 144 ReSideRdrLeDetn237 1 : ReSideRdrLeDetn237RdrDetnAmbigState ReSideRdrLeDetn237RdrDetnAssoTrkID ReSideRdrLeDetn237RdrDetnAzi ReSideRdrLeDetn237RdrDetnChks ReSideRdrLeDetn237RdrDetnCntr ReSideRdrLeDetn237RdrDetnConf ReSideRdrLeDetn237RdrDetnElevn ReSideRdrLeDetn237RdrDetnPwr ReSideRdrLeDetn237RdrDetnRng ReSideRdrLeDetn237RdrDetnRngV ReSideRdrLeDetn237RdrDetnSameRV ReSideRdrLeDetn237RdrDetnSts;
SIG_GROUP_ 144 ReSideRdrLeDetn238 1 : ReSideRdrLeDetn238RdrDetnAmbigState ReSideRdrLeDetn238RdrDetnAssoTrkID ReSideRdrLeDetn238RdrDetnAzi ReSideRdrLeDetn238RdrDetnChks ReSideRdrLeDetn238RdrDetnCntr ReSideRdrLeDetn238RdrDetnConf ReSideRdrLeDetn238RdrDetnElevn ReSideRdrLeDetn238RdrDetnPwr ReSideRdrLeDetn238RdrDetnRng ReSideRdrLeDetn238RdrDetnRngV ReSideRdrLeDetn238RdrDetnSameRV ReSideRdrLeDetn238RdrDetnSts;
SIG_GROUP_ 144 ReSideRdrLeDetn239 1 : ReSideRdrLeDetn239RdrDetnAmbigState ReSideRdrLeDetn239RdrDetnAssoTrkID ReSideRdrLeDetn239RdrDetnAzi ReSideRdrLeDetn239RdrDetnChks ReSideRdrLeDetn239RdrDetnCntr ReSideRdrLeDetn239RdrDetnConf ReSideRdrLeDetn239RdrDetnElevn ReSideRdrLeDetn239RdrDetnPwr ReSideRdrLeDetn239RdrDetnRng ReSideRdrLeDetn239RdrDetnRngV ReSideRdrLeDetn239RdrDetnSameRV ReSideRdrLeDetn239RdrDetnSts;
SIG_GROUP_ 144 ReSideRdrLeDetn240 1 : ReSideRdrLeDetn240RdrDetnAmbigState ReSideRdrLeDetn240RdrDetnAssoTrkID ReSideRdrLeDetn240RdrDetnAzi ReSideRdrLeDetn240RdrDetnChks ReSideRdrLeDetn240RdrDetnCntr ReSideRdrLeDetn240RdrDetnConf ReSideRdrLeDetn240RdrDetnElevn ReSideRdrLeDetn240RdrDetnPwr ReSideRdrLeDetn240RdrDetnRng ReSideRdrLeDetn240RdrDetnRngV ReSideRdrLeDetn240RdrDetnSameRV ReSideRdrLeDetn240RdrDetnSts;
SIG_GROUP_ 145 ReSideRdrLeDetn241 1 : ReSideRdrLeDetn241RdrDetnAmbigState ReSideRdrLeDetn241RdrDetnAssoTrkID ReSideRdrLeDetn241RdrDetnAzi ReSideRdrLeDetn241RdrDetnChks ReSideRdrLeDetn241RdrDetnCntr ReSideRdrLeDetn241RdrDetnConf ReSideRdrLeDetn241RdrDetnElevn ReSideRdrLeDetn241RdrDetnPwr ReSideRdrLeDetn241RdrDetnRng ReSideRdrLeDetn241RdrDetnRngV ReSideRdrLeDetn241RdrDetnSameRV ReSideRdrLeDetn241RdrDetnSts;
SIG_GROUP_ 145 ReSideRdrLeDetn242 1 : ReSideRdrLeDetn242RdrDetnAmbigState ReSideRdrLeDetn242RdrDetnAssoTrkID ReSideRdrLeDetn242RdrDetnAzi ReSideRdrLeDetn242RdrDetnChks ReSideRdrLeDetn242RdrDetnCntr ReSideRdrLeDetn242RdrDetnConf ReSideRdrLeDetn242RdrDetnElevn ReSideRdrLeDetn242RdrDetnPwr ReSideRdrLeDetn242RdrDetnRng ReSideRdrLeDetn242RdrDetnRngV ReSideRdrLeDetn242RdrDetnSameRV ReSideRdrLeDetn242RdrDetnSts;
SIG_GROUP_ 145 ReSideRdrLeDetn243 1 : ReSideRdrLeDetn243RdrDetnAmbigState ReSideRdrLeDetn243RdrDetnAssoTrkID ReSideRdrLeDetn243RdrDetnAzi ReSideRdrLeDetn243RdrDetnChks ReSideRdrLeDetn243RdrDetnCntr ReSideRdrLeDetn243RdrDetnConf ReSideRdrLeDetn243RdrDetnElevn ReSideRdrLeDetn243RdrDetnPwr ReSideRdrLeDetn243RdrDetnRng ReSideRdrLeDetn243RdrDetnRngV ReSideRdrLeDetn243RdrDetnSameRV ReSideRdrLeDetn243RdrDetnSts;
SIG_GROUP_ 145 ReSideRdrLeDetn244 1 : ReSideRdrLeDetn244RdrDetnAmbigState ReSideRdrLeDetn244RdrDetnAssoTrkID ReSideRdrLeDetn244RdrDetnAzi ReSideRdrLeDetn244RdrDetnChks ReSideRdrLeDetn244RdrDetnCntr ReSideRdrLeDetn244RdrDetnConf ReSideRdrLeDetn244RdrDetnElevn ReSideRdrLeDetn244RdrDetnPwr ReSideRdrLeDetn244RdrDetnRng ReSideRdrLeDetn244RdrDetnRngV ReSideRdrLeDetn244RdrDetnSameRV ReSideRdrLeDetn244RdrDetnSts;
SIG_GROUP_ 145 ReSideRdrLeDetn245 1 : ReSideRdrLeDetn245RdrDetnAmbigState ReSideRdrLeDetn245RdrDetnAssoTrkID ReSideRdrLeDetn245RdrDetnAzi ReSideRdrLeDetn245RdrDetnChks ReSideRdrLeDetn245RdrDetnCntr ReSideRdrLeDetn245RdrDetnConf ReSideRdrLeDetn245RdrDetnElevn ReSideRdrLeDetn245RdrDetnPwr ReSideRdrLeDetn245RdrDetnRng ReSideRdrLeDetn245RdrDetnRngV ReSideRdrLeDetn245RdrDetnSameRV ReSideRdrLeDetn245RdrDetnSts;
SIG_GROUP_ 145 ReSideRdrLeDetn246 1 : ReSideRdrLeDetn246RdrDetnAmbigState ReSideRdrLeDetn246RdrDetnAssoTrkID ReSideRdrLeDetn246RdrDetnAzi ReSideRdrLeDetn246RdrDetnChks ReSideRdrLeDetn246RdrDetnCntr ReSideRdrLeDetn246RdrDetnConf ReSideRdrLeDetn246RdrDetnElevn ReSideRdrLeDetn246RdrDetnPwr ReSideRdrLeDetn246RdrDetnRng ReSideRdrLeDetn246RdrDetnRngV ReSideRdrLeDetn246RdrDetnSameRV ReSideRdrLeDetn246RdrDetnSts;
SIG_GROUP_ 146 ReSideRdrLeDetn247 1 : ReSideRdrLeDetn247RdrDetnAmbigState ReSideRdrLeDetn247RdrDetnAssoTrkID ReSideRdrLeDetn247RdrDetnAzi ReSideRdrLeDetn247RdrDetnChks ReSideRdrLeDetn247RdrDetnCntr ReSideRdrLeDetn247RdrDetnConf ReSideRdrLeDetn247RdrDetnElevn ReSideRdrLeDetn247RdrDetnPwr ReSideRdrLeDetn247RdrDetnRng ReSideRdrLeDetn247RdrDetnRngV ReSideRdrLeDetn247RdrDetnSameRV ReSideRdrLeDetn247RdrDetnSts;
SIG_GROUP_ 146 ReSideRdrLeDetn248 1 : ReSideRdrLeDetn248RdrDetnAmbigState ReSideRdrLeDetn248RdrDetnAssoTrkID ReSideRdrLeDetn248RdrDetnAzi ReSideRdrLeDetn248RdrDetnChks ReSideRdrLeDetn248RdrDetnCntr ReSideRdrLeDetn248RdrDetnConf ReSideRdrLeDetn248RdrDetnElevn ReSideRdrLeDetn248RdrDetnPwr ReSideRdrLeDetn248RdrDetnRng ReSideRdrLeDetn248RdrDetnRngV ReSideRdrLeDetn248RdrDetnSameRV ReSideRdrLeDetn248RdrDetnSts;
SIG_GROUP_ 146 ReSideRdrLeDetn249 1 : ReSideRdrLeDetn249RdrDetnAmbigState ReSideRdrLeDetn249RdrDetnAssoTrkID ReSideRdrLeDetn249RdrDetnAzi ReSideRdrLeDetn249RdrDetnChks ReSideRdrLeDetn249RdrDetnCntr ReSideRdrLeDetn249RdrDetnConf ReSideRdrLeDetn249RdrDetnElevn ReSideRdrLeDetn249RdrDetnPwr ReSideRdrLeDetn249RdrDetnRng ReSideRdrLeDetn249RdrDetnRngV ReSideRdrLeDetn249RdrDetnSameRV ReSideRdrLeDetn249RdrDetnSts;
SIG_GROUP_ 146 ReSideRdrLeDetn250 1 : ReSideRdrLeDetn250RdrDetnAmbigState ReSideRdrLeDetn250RdrDetnAssoTrkID ReSideRdrLeDetn250RdrDetnAzi ReSideRdrLeDetn250RdrDetnChks ReSideRdrLeDetn250RdrDetnCntr ReSideRdrLeDetn250RdrDetnConf ReSideRdrLeDetn250RdrDetnElevn ReSideRdrLeDetn250RdrDetnPwr ReSideRdrLeDetn250RdrDetnRng ReSideRdrLeDetn250RdrDetnRngV ReSideRdrLeDetn250RdrDetnSameRV ReSideRdrLeDetn250RdrDetnSts;
SIG_GROUP_ 146 ReSideRdrLeDetn251 1 : ReSideRdrLeDetn251RdrDetnAmbigState ReSideRdrLeDetn251RdrDetnAssoTrkID ReSideRdrLeDetn251RdrDetnAzi ReSideRdrLeDetn251RdrDetnChks ReSideRdrLeDetn251RdrDetnCntr ReSideRdrLeDetn251RdrDetnConf ReSideRdrLeDetn251RdrDetnElevn ReSideRdrLeDetn251RdrDetnPwr ReSideRdrLeDetn251RdrDetnRng ReSideRdrLeDetn251RdrDetnRngV ReSideRdrLeDetn251RdrDetnSameRV ReSideRdrLeDetn251RdrDetnSts;
SIG_GROUP_ 146 ReSideRdrLeDetn252 1 : ReSideRdrLeDetn252RdrDetnAmbigState ReSideRdrLeDetn252RdrDetnAssoTrkID ReSideRdrLeDetn252RdrDetnAzi ReSideRdrLeDetn252RdrDetnChks ReSideRdrLeDetn252RdrDetnCntr ReSideRdrLeDetn252RdrDetnConf ReSideRdrLeDetn252RdrDetnElevn ReSideRdrLeDetn252RdrDetnPwr ReSideRdrLeDetn252RdrDetnRng ReSideRdrLeDetn252RdrDetnRngV ReSideRdrLeDetn252RdrDetnSameRV ReSideRdrLeDetn252RdrDetnSts;
SIG_GROUP_ 147 ReSideRdrLeDetn253 1 : ReSideRdrLeDetn253RdrDetnAmbigState ReSideRdrLeDetn253RdrDetnAssoTrkID ReSideRdrLeDetn253RdrDetnAzi ReSideRdrLeDetn253RdrDetnChks ReSideRdrLeDetn253RdrDetnCntr ReSideRdrLeDetn253RdrDetnConf ReSideRdrLeDetn253RdrDetnElevn ReSideRdrLeDetn253RdrDetnPwr ReSideRdrLeDetn253RdrDetnRng ReSideRdrLeDetn253RdrDetnRngV ReSideRdrLeDetn253RdrDetnSameRV ReSideRdrLeDetn253RdrDetnSts;
SIG_GROUP_ 147 ReSideRdrLeDetn254 1 : ReSideRdrLeDetn254RdrDetnAmbigState ReSideRdrLeDetn254RdrDetnAssoTrkID ReSideRdrLeDetn254RdrDetnAzi ReSideRdrLeDetn254RdrDetnChks ReSideRdrLeDetn254RdrDetnCntr ReSideRdrLeDetn254RdrDetnConf ReSideRdrLeDetn254RdrDetnElevn ReSideRdrLeDetn254RdrDetnPwr ReSideRdrLeDetn254RdrDetnRng ReSideRdrLeDetn254RdrDetnRngV ReSideRdrLeDetn254RdrDetnSameRV ReSideRdrLeDetn254RdrDetnSts;
SIG_GROUP_ 147 ReSideRdrLeDetn255 1 : ReSideRdrLeDetn255RdrDetnAmbigState ReSideRdrLeDetn255RdrDetnAssoTrkID ReSideRdrLeDetn255RdrDetnAzi ReSideRdrLeDetn255RdrDetnChks ReSideRdrLeDetn255RdrDetnCntr ReSideRdrLeDetn255RdrDetnConf ReSideRdrLeDetn255RdrDetnElevn ReSideRdrLeDetn255RdrDetnPwr ReSideRdrLeDetn255RdrDetnRng ReSideRdrLeDetn255RdrDetnRngV ReSideRdrLeDetn255RdrDetnSameRV ReSideRdrLeDetn255RdrDetnSts;
SIG_GROUP_ 147 ReSideRdrLeDetn256 1 : ReSideRdrLeDetn256RdrDetnAmbigState ReSideRdrLeDetn256RdrDetnAssoTrkID ReSideRdrLeDetn256RdrDetnAzi ReSideRdrLeDetn256RdrDetnChks ReSideRdrLeDetn256RdrDetnCntr ReSideRdrLeDetn256RdrDetnConf ReSideRdrLeDetn256RdrDetnElevn ReSideRdrLeDetn256RdrDetnPwr ReSideRdrLeDetn256RdrDetnRng ReSideRdrLeDetn256RdrDetnRngV ReSideRdrLeDetn256RdrDetnSameRV ReSideRdrLeDetn256RdrDetnSts;
SIG_GROUP_ 148 ReSideRdrLeDetTiSync 1 : ReSideRdrLeDetTiSyncRdrStsDetChks ReSideRdrLeDetTiSyncRdrStsDetCntr ReSideRdrLeDetTiSyncRdrStsDetLatency ReSideRdrLeDetTiSyncRdrStsDetTiStamp20 ReSideRdrLeDetTiSyncRdrStsDetTiStampHi20 ReSideRdrLeDetTiSyncRdrStsDetTiStampNano20 ReSideRdrLeDetTiSyncRdrStsDetTistampStsGlbTiBas ReSideRdrLeDetTiSyncRdrStsDetTistampStsSyncToGateway ReSideRdrLeDetTiSyncRdrStsDetTistampStsTiLeap ReSideRdrLeDetTiSyncRdrStsDetTistampStsTiOut;
SIG_GROUP_ 149 SODL20PartNum 1 : SODL20PartNumPartNumType SODL20PartNumPartNumValue;
